VERSION "BASE;119 -- 04.07.2025 -- R3233 -- FDMgenDBC1.0"

NS_ :

BS_:

BU_: CM4

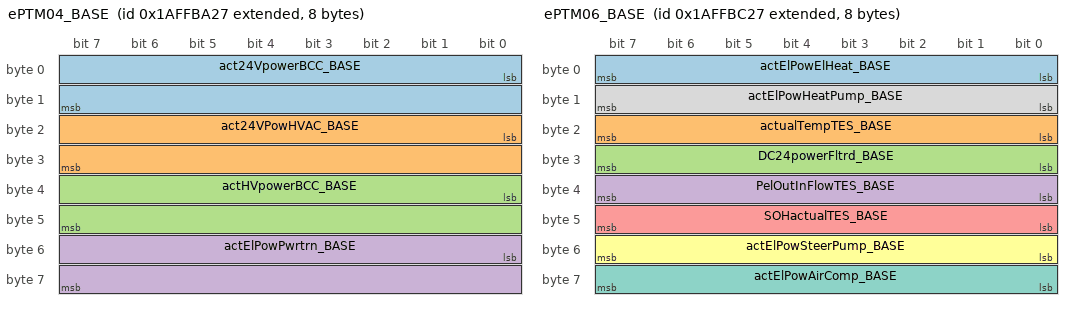
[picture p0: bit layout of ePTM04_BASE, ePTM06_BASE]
BO_ 2600450599 ePTM04_BASE: 8 Vector__XXX
 SG_ act24VpowerBCC_BASE : 0|16@1+ (0.0025,0) [0|13] "kW" CM4
 SG_ act24VPowHVAC_BASE : 16|16@1+ (1,0) [0|60000] "W" CM4
 SG_ actHVpowerBCC_BASE : 32|16@1+ (0.0125,0) [0|100] "kW" CM4
 SG_ actElPowPwrtrn_BASE : 48|16@1+ (1,-600) [-600|600] "kW" CM4

BO_ 2600451111 ePTM06_BASE: 8 Vector__XXX
 SG_ actElPowElHeat_BASE : 0|8@1+ (500,0) [0|125000] "W" CM4
 SG_ actualTempTES_BASE : 16|8@1+ (0.5,-40) [-40|85] "°C" CM4
 SG_ DC24powerFltrd_BASE : 24|8@1+ (0.125,0) [0|30] "kW" CM4
 SG_ PelOutInFlowTES_BASE : 32|8@1+ (5,-625) [-625|625] "kW" CM4
 SG_ SOHactualTES_BASE : 40|8@1+ (0.4,0) [0|100] "%" CM4
 SG_ actElPowSteerPump_BASE : 48|8@1+ (0.05,0) [0|8.125] "kW" CM4
 SG_ actElPowAirComp_BASE : 56|8@1+ (0.05,0) [0|10.8] "kW" CM4
 SG_ actElPowHeatPump_BASE : 8|8@1+ (500,0) [0|125000] "W" CM4

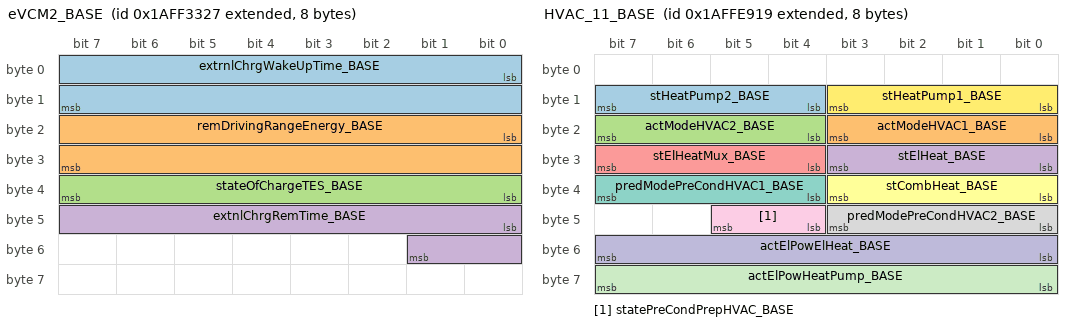
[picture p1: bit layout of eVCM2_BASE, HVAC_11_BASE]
BO_ 2600416039 eVCM2_BASE: 8 Vector__XXX
 SG_ extrnlChrgWakeUpTime_BASE : 0|16@1+ (60,0) [0|64255] "s" CM4
 SG_ remDrivingRangeEnergy_BASE : 16|16@1+ (0.5,0) [0|32127.5] "km" CM4
 SG_ stateOfChargeTES_BASE : 32|8@1+ (0.4,0) [0|100] "%" CM4
 SG_ extnlChrgRemTime_BASE : 40|10@1+ (5,0) [0|4320] "min" CM4

BO_ 2600462617 HVAC_11_BASE: 8 Vector__XXX
 SG_ stHeatPump2_BASE : 12|4@1+ (1,0) [0|0] "-" CM4
 SG_ actModeHVAC1_BASE : 16|4@1+ (1,0) [0|0] "-" CM4
 SG_ actModeHVAC2_BASE : 20|4@1+ (1,0) [0|0] "-" CM4
 SG_ stElHeat_BASE : 24|4@1+ (1,0) [0|0] "-" CM4
 SG_ stElHeatMux_BASE : 28|4@1+ (1,0) [0|0] "-" CM4
 SG_ stCombHeat_BASE : 32|4@1+ (1,0) [0|0] "-" CM4
 SG_ predModePreCondHVAC1_BASE : 36|4@1+ (1,0) [0|0] "-" CM4
 SG_ predModePreCondHVAC2_BASE : 40|4@1+ (1,0) [0|0] "-" CM4
 SG_ statePreCondPrepHVAC_BASE : 44|2@1+ (1,0) [0|0] "-" CM4
 SG_ actElPowElHeat_BASE : 48|8@1+ (500,0) [0|125000] "W" CM4
 SG_ actElPowHeatPump_BASE : 56|8@1+ (500,0) [0|125000] "W" CM4
 SG_ stHeatPump1_BASE : 8|4@1+ (1,0) [0|0] "-" CM4

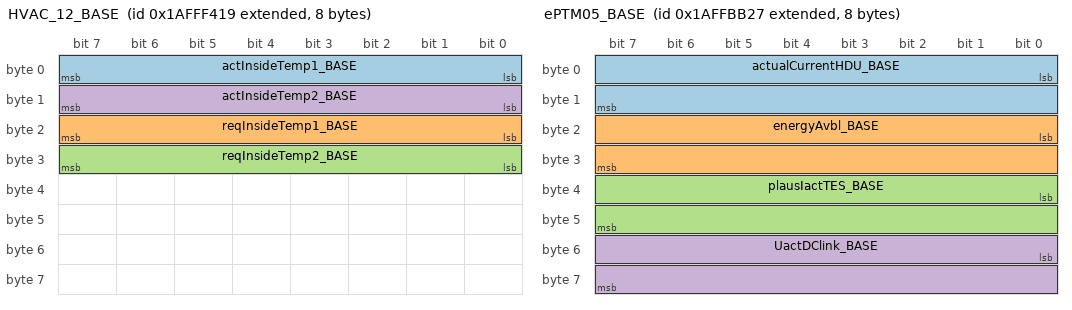
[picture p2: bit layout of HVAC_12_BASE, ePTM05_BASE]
BO_ 2600465433 HVAC_12_BASE: 8 Vector__XXX
 SG_ actInsideTemp1_BASE : 0|8@1+ (0.33,-30) [-30|52.5] "°C" CM4
 SG_ reqInsideTemp1_BASE : 16|8@1+ (0.33,-30) [-30|52.5] "°C" CM4
 SG_ reqInsideTemp2_BASE : 24|8@1+ (0.33,-30) [-30|52.5] "°C" CM4
 SG_ actInsideTemp2_BASE : 8|8@1+ (0.33,-30) [-30|52.5] "°C" CM4

BO_ 2600450855 ePTM05_BASE: 8 Vector__XXX
 SG_ actualCurrentHDU_BASE : 0|16@1+ (0.25,-8031.75) [-8031.75|8032] "A" CM4
 SG_ energyAvbl_BASE : 16|16@1+ (0.01,0) [0|600] "kWh" CM4
 SG_ plausIactTES_BASE : 32|16@1+ (0.25,-8031.875) [-8031.875|8031.875] "A" CM4
 SG_ UactDClink_BASE : 48|16@1+ (0.05,0) [0|3212.75] "V" CM4

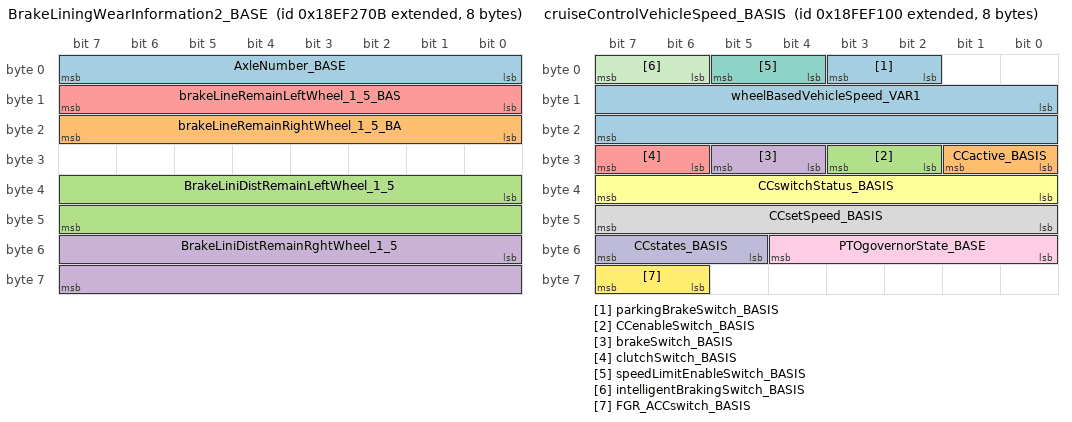
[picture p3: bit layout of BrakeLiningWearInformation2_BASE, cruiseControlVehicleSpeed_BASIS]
BO_ 2565809931 BrakeLiningWearInformation2_BASE: 8 Vector__XXX
 SG_ AxleNumber_BASE : 0|8@1+ (1,0) [0|250] "-" CM4
 SG_ brakeLineRemainRightWheel_1_5_BA : 16|8@1+ (0.4,0) [0|100] "%" CM4
 SG_ BrakeLiniDistRemainLeftWheel_1_5 : 32|16@1+ (100,0) [0|6553500] "km" CM4
 SG_ BrakeLiniDistRemainRghtWheel_1_5 : 48|16@1+ (100,0) [0|6553500] "km" CM4
 SG_ brakeLineRemainLeftWheel_1_5_BAS : 8|8@1+ (0.4,0) [0|100] "%" CM4

BO_ 2566844672 cruiseControlVehicleSpeed_BASIS: 8 Vector__XXX
 SG_ parkingBrakeSwitch_BASIS : 2|2@1+ (1,0) [0|0] "-" CM4
 SG_ CCactive_BASIS : 24|2@1+ (1,0) [0|0] "-" CM4
 SG_ CCenableSwitch_BASIS : 26|2@1+ (1,0) [0|0] "-" CM4
 SG_ brakeSwitch_BASIS : 28|2@1+ (1,0) [0|0] "-" CM4
 SG_ clutchSwitch_BASIS : 30|2@1+ (1,0) [0|0] "-" CM4
 SG_ CCswitchStatus_BASIS : 32|8@1+ (1,0) [0|0] "-" CM4
 SG_ speedLimitEnableSwitch_BASIS : 4|2@1+ (1,0) [0|0] "-" CM4
 SG_ CCsetSpeed_BASIS : 40|8@1+ (1,0) [0|250] "km/h" CM4
 SG_ PTOgovernorState_BASE : 48|5@1+ (1,0) [0|0] "-" CM4
 SG_ CCstates_BASIS : 53|3@1+ (1,0) [0|0] "-" CM4
 SG_ intelligentBrakingSwitch_BASIS : 6|2@1+ (1,0) [0|0] "-" CM4
 SG_ FGR_ACCswitch_BASIS : 62|2@1+ (1,0) [0|0] "-" CM4
 SG_ wheelBasedVehicleSpeed_VAR1 : 8|16@1+ (0.00390625,0) [0|250.996] "km/h" CM4

BO_ 2365479471 ASC1_BASIS: 8 Vector__XXX
 SG_ nominalLevelFrontAxle_BASIS : 0|4@1+ (1,0) [0|0] "-" CM4
 SG_ belowNominalLevelRearAxle_BASIS : 10|2@1+ (1,0) [0|0] "-" CM4
 SG_ aboveNominalLevelFrontAxle_BASIS : 12|2@1+ (1,0) [0|0] "-" CM4
 SG_ aboveNominalLevelRearAxle_BASIS : 14|2@1+ (1,0) [0|0] "-" CM4
 SG_ loweringControlModeFrontAxle_BAS : 16|2@1+ (1,0) [0|0] "-" CM4
 SG_ loweringControlModeRearAxle_BASI : 18|2@1+ (1,0) [0|0] "-" CM4
 SG_ liftingControlModeFrontAxle_BASI : 20|2@1+ (1,0) [0|0] "-" CM4
 SG_ liftingControlModeRearAxle_BASIS : 22|2@1+ (1,0) [0|0] "-" CM4
 SG_ kneelingInformation_BASIS : 24|4@1+ (1,0) [0|0] "-" CM4
 SG_ levelControlMode_BASIS : 28|4@1+ (1,0) [0|0] "-" CM4
 SG_ securityDevice_BASIS : 32|2@1+ (1,0) [0|0] "-" CM4
 SG_ vehicleMotionInhibit_BASIS : 34|2@1+ (1,0) [0|0] "-" CM4
 SG_ doorRelease_BASIS : 36|2@1+ (1,0) [0|0] "-" CM4
 SG_ liftAxle1position_BASIS : 38|2@1+ (1,0) [0|0] "-" CM4
 SG_ nominalLevelRearAxle_BASIS : 4|4@1+ (1,0) [0|0] "-" CM4
 SG_ frontAxleBumperRange_BASIS : 40|2@1+ (1,0) [0|0] "-" CM4
 SG_ rearAxleBumperRange_BASIS : 42|2@1+ (1,0) [0|0] "-" CM4
 SG_ liftAxle2position_BASIS : 46|2@1+ (1,0) [0|0] "-" CM4
 SG_ suspensionRemoteControl1_BASIS : 48|2@1+ (1,0) [0|0] "-" CM4
 SG_ suspensionRemoteControl2_BASIS : 50|2@1+ (1,0) [0|0] "-" CM4
 SG_ allowLvlCtrlDuringBrakingStatus_ : 52|2@1+ (1,0) [0|0] "-" CM4
 SG_ speedDependantLevelControlStatus : 54|2@1+ (1,0) [0|0] "-" CM4
 SG_ suspensionControlRefusalInfo_BAS : 56|4@1+ (1,0) [0|0] "-" CM4
 SG_ belowNominalLevelFrontAxle_BASIS : 8|2@1+ (1,0) [0|0] "-" CM4

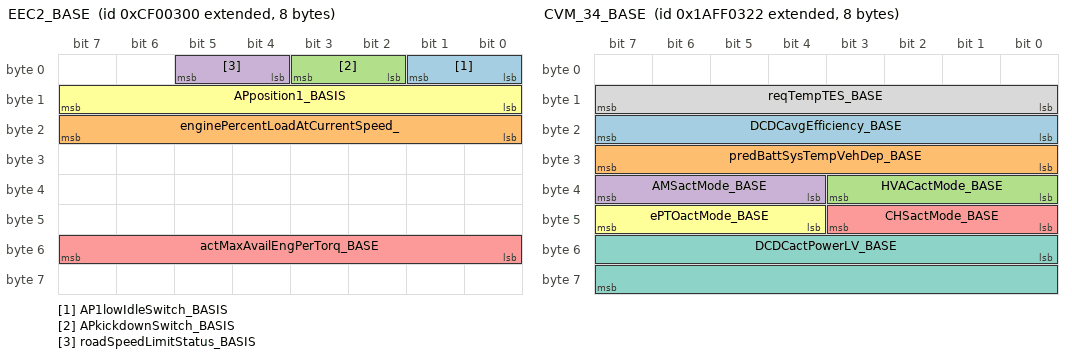
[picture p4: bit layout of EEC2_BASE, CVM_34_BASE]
BO_ 2364539648 EEC2_BASE: 8 Vector__XXX
 SG_ AP1lowIdleSwitch_BASIS : 0|2@1+ (1,0) [0|0] "-" CM4
 SG_ enginePercentLoadAtCurrentSpeed_ : 16|8@1+ (1,0) [0|250] "%" CM4
 SG_ APkickdownSwitch_BASIS : 2|2@1+ (1,0) [0|0] "-" CM4
 SG_ roadSpeedLimitStatus_BASIS : 4|2@1+ (1,0) [0|0] "-" CM4
 SG_ actMaxAvailEngPerTorq_BASE : 48|8@1+ (0.4,0) [0|100] "%" CM4
 SG_ APposition1_BASIS : 8|8@1+ (0.4,0) [0|100] "%" CM4

BO_ 2600403746 CVM_34_BASE: 8 Vector__XXX
 SG_ DCDCavgEfficiency_BASE : 16|8@1+ (0.005,0) [0|1] "-" CM4
 SG_ predBattSysTempVehDep_BASE : 24|8@1+ (0.5,-40) [-40|85] "°C" CM4
 SG_ HVACactMode_BASE : 32|4@1+ (1,0) [0|0] "-" CM4
 SG_ AMSactMode_BASE : 36|4@1+ (1,0) [0|0] "-" CM4
 SG_ CHSactMode_BASE : 40|4@1+ (1,0) [0|0] "-" CM4
 SG_ ePTOactMode_BASE : 44|4@1+ (1,0) [0|0] "-" CM4
 SG_ DCDCactPowerLV_BASE : 48|16@1+ (0.025,-800) [-800|800] "kW" CM4
 SG_ reqTempTES_BASE : 8|8@1+ (0.5,-40) [-40|85] "°C" CM4

BO_ 2600403748 CVM_36_BASE: 8 Vector__XXX
 SG_ AMSenergyNorm_BASE : 0|32@1+ (0.0025,-1000000) [-1000000|1000000] "kWs" CM4
 SG_ AMS1sMeanPowerLV_BASE : 32|16@1+ (0.025,-800) [-800|800] "kW" CM4
 SG_ AMS1sMeanPowerHV_BASE : 48|16@1+ (0.025,-800) [-800|800] "kW" CM4

BO_ 2600403749 CVM_37_BASE: 8 Vector__XXX
 SG_ CHSenergyNorm_BASE : 0|32@1+ (0.0025,-1000000) [-1000000|1000000] "kWs" CM4
 SG_ CHS1sMeanPowerLV_BASE : 32|16@1+ (0.025,-800) [-800|800] "kW" CM4
 SG_ CHS1sMeanPowerHV_BASE : 48|16@1+ (0.025,-800) [-800|800] "kW" CM4

BO_ 2600403750 CVM_38_BASE: 8 Vector__XXX
 SG_ ePTOenergyNorm_BASE : 0|32@1+ (0.0025,-1000000) [-1000000|1000000] "kWs" CM4
 SG_ ePTO1sMeanPowerLV_BASE : 32|16@1+ (0.025,-800) [-800|800] "kW" CM4
 SG_ ePTO1sMeanPowerHV_BASE : 48|16@1+ (0.025,-800) [-800|800] "kW" CM4

BO_ 2600403751 CVM_39_BASE: 8 Vector__XXX
 SG_ HVACenergyNorm_BASE : 0|32@1+ (0.0025,-1000000) [-1000000|1000000] "kWs" CM4
 SG_ HVAC1sMeanPowerLV_BASE : 32|16@1+ (0.025,-800) [-800|800] "kW" CM4
 SG_ HVAC1sMeanPowerHV_BASE : 48|16@1+ (0.025,-800) [-800|800] "kW" CM4

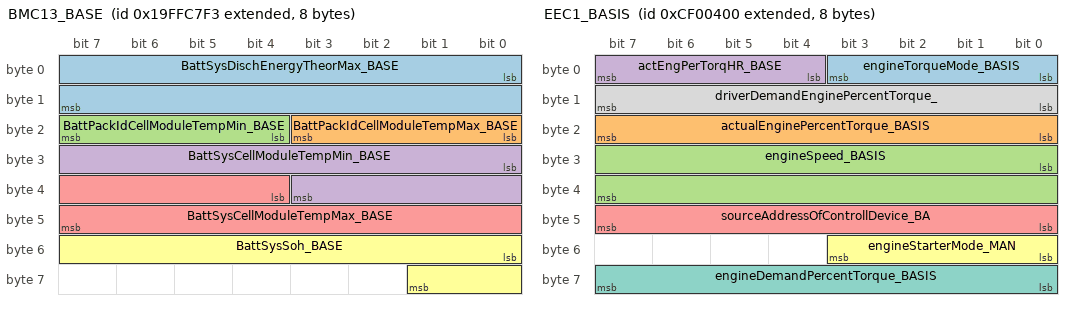
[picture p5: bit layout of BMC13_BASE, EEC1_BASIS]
BO_ 2583676915 BMC13_BASE: 8 Vector__XXX
 SG_ BattSysDischEnergyTheorMax_BASE : 0|16@1+ (0.05,0) [0|1000] "kWh" CM4
 SG_ BattPackIdCellModuleTempMax_BASE : 16|4@1+ (1,1) [1|16] "-" CM4
 SG_ BattPackIdCellModuleTempMin_BASE : 20|4@1+ (1,1) [1|16] "-" CM4
 SG_ BattSysCellModuleTempMin_BASE : 24|12@1+ (0.1,-50) [-50|90] "°C" CM4
 SG_ BattSysCellModuleTempMax_BASE : 36|12@1+ (0.1,-50) [-50|90] "°C" CM4
 SG_ BattSysSoh_BASE : 48|10@1+ (0.1,0) [0|100] "%" CM4

BO_ 2566535975 EPTO1I_BASE: 8 Vector__XXX
 SG_ ePTO1CurrentLimit_BASE : 0|16@1+ (0.05,0) [0|3212.75] "-" CM4
 SG_ ePTO1Current_BASE : 16|16@1+ (0.05,0) [0|3212.75] "A" CM4
 SG_ ePTO1Voltage_BASE : 32|16@1+ (0.05,0) [0|3212.75] "-" CM4

BO_ 2566889761 auxStatZBR1_BASIS: 8 Vector__XXX
 SG_ tuerkontaktLinks_BASIS : 0|2@1+ (1,0) [0|0] "-" CM4
 SG_ fahrerhausVerriegelung_BASIS : 10|2@1+ (1,0) [0|0] "-" CM4
 SG_ haengerABSerkennung_BASIS : 12|2@1+ (1,0) [0|0] "-" CM4
 SG_ flammstartAktiv_BASIS : 14|2@1+ (1,0) [0|0] "-" CM4
 SG_ fernlichtEinRueckmeldung_BASIS : 18|2@1+ (1,0) [0|0] "-" CM4
 SG_ tuerkontaktRechts_BASIS : 2|2@1+ (1,0) [0|0] "-" CM4
 SG_ schalterFahrniveau1oder2senken_B : 24|2@1+ (1,0) [0|0] "-" CM4
 SG_ hybTripReset_BASE : 36|2@1+ (1,0) [0|0] "-" CM4
 SG_ instrFunktionsfaehig_BASIS : 38|2@1+ (1,0) [0|0] "-" CM4
 SG_ kraftstoffuellstandZuNiedrig_BAS : 4|2@1+ (1,0) [0|0] "-" CM4
 SG_ schalterBlinkerRechtsRueckm_BASI : 44|2@1+ (1,0) [0|0] "-" CM4
 SG_ schalterBlinkerLinksRueckm_BASIS : 46|2@1+ (1,0) [0|0] "-" CM4
 SG_ lichttestAktivRueckmeldung_BASIS : 48|2@1+ (1,0) [0|0] "-" CM4
 SG_ kontrVersorgAnhaengerABS_BASIS : 50|2@1+ (1,0) [0|0] "-" CM4
 SG_ highBeamOutpState_BASE : 52|2@1+ (1,0) [0|0] "-" CM4
 SG_ beleuchtungHaenger1erkannt_BASIS : 54|2@1+ (1,0) [0|0] "-" CM4
 SG_ fahrlichtEinRueckmeldung_BASIS : 56|2@1+ (1,0) [0|0] "-" CM4
 SG_ rueckwaertsgangEingelegt_BASIS : 6|2@1+ (1,0) [0|0] "-" CM4
 SG_ infoNotaus_BASIS : 8|2@1+ (1,0) [0|0] "-" CM4

BO_ 2565865739 EBC1_BASIS: 8 Vector__XXX
 SG_ ASRengineControlActPass_BASIS : 0|2@1+ (1,0) [0|0] "-" CM4
 SG_ ABSoffroadSwitch_BASIS : 16|2@1+ (1,0) [0|0] "-" CM4
 SG_ ASRoffroadSwitch_BASIS : 18|2@1+ (1,0) [0|0] "-" CM4
 SG_ ASRbrakeControlActPass_BASIS : 2|2@1+ (1,0) [0|0] "-" CM4
 SG_ ASRhillHolderSwitch_BASIS : 20|2@1+ (1,0) [0|0] "-" CM4
 SG_ tractionControlOverrideSwitch_BA : 22|2@1+ (1,0) [0|0] "-" CM4
 SG_ acceleratorInterlockSwitch_BASIS : 24|2@1+ (1,0) [0|0] "-" CM4
 SG_ engineDerateSwitch_BASIS : 26|2@1+ (1,0) [0|0] "-" CM4
 SG_ engineAuxiliaryShutdownSwitch_BA : 28|2@1+ (1,0) [0|0] "-" CM4
 SG_ remoteAcceleratorEnableSwitch_BA : 30|2@1+ (1,0) [0|0] "-" CM4
 SG_ engineRetarderSelection_BASIS : 32|8@1+ (0.4,0) [0|100] "%" CM4
 SG_ ABSactive_BASIS : 4|2@1+ (1,0) [0|0] "-" CM4
 SG_ ABSfullyOperational_BASIS : 40|2@1+ (1,0) [0|0] "-" CM4
 SG_ EBSredWarningSignal_BASIS : 42|2@1+ (1,0) [0|0] "-" CM4
 SG_ ABS_EBSamberWarningSignal_BASIS : 44|2@1+ (1,0) [0|0] "-" CM4
 SG_ ATC_ASRinformationSignal_BASIS : 46|2@1+ (1,0) [0|0] "-" CM4
 SG_ sourceAddressOfControllDevice_EB : 48|8@1+ (1,0) [0|253] "-" CM4
 SG_ haltBrakeSwitch_BASIS : 58|2@1+ (1,0) [0|0] "-" CM4
 SG_ EBSbrakeSwitch_BASIS : 6|2@1+ (1,0) [0|0] "-" CM4
 SG_ trailerABSstatus_BASIS : 60|2@1+ (1,0) [0|0] "-" CM4
 SG_ tractMountTrailerABSwarningSig_B : 62|2@1+ (1,0) [0|0] "-" CM4
 SG_ BPposition_BASIS : 8|8@1+ (0.4,0) [0|100] "%" CM4

BO_ 2364539904 EEC1_BASIS: 8 Vector__XXX
 SG_ engineTorqueMode_BASIS : 0|4@1+ (1,0) [0|0] "-" CM4
 SG_ actualEnginePercentTorque_BASIS : 16|8@1+ (1,-125) [-125|125] "%" CM4
 SG_ engineSpeed_BASIS : 24|16@1+ (0.125,0) [0|8031.875] "rpm" CM4
 SG_ actEngPerTorqHR_BASE : 4|4@1+ (0.125,0) [0|1.875] "%" CM4
 SG_ sourceAddressOfControllDevice_BA : 40|8@1+ (1,0) [0|255] "-" CM4
 SG_ engineStarterMode_MAN : 48|4@1+ (1,0) [0|0] "-" CM4
 SG_ engineDemandPercentTorque_BASIS : 56|8@1+ (1,-125) [-125|125] "%" CM4
 SG_ driverDemandEnginePercentTorque_ : 8|8@1+ (1,-125) [-125|125] "%" CM4

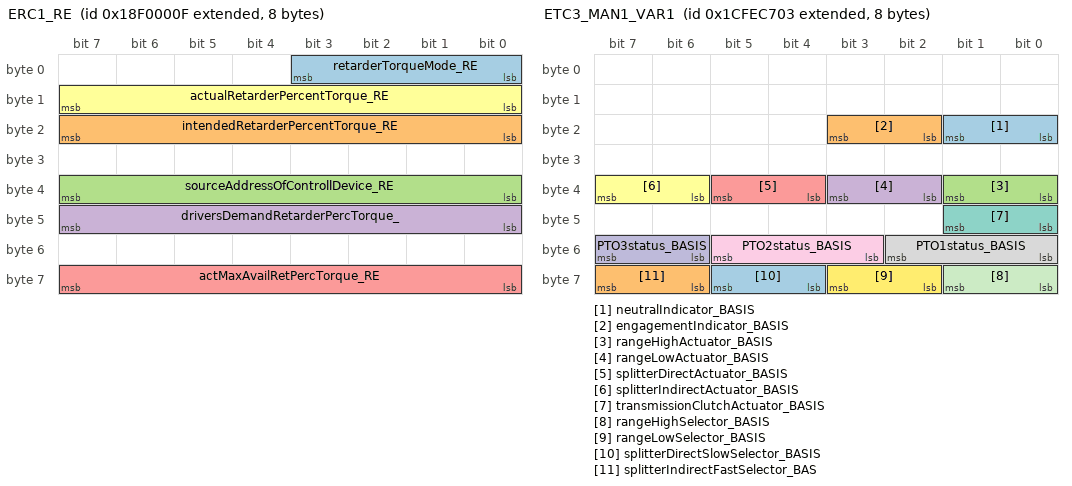
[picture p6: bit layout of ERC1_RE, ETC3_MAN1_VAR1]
BO_ 2565865487 ERC1_RE: 8 Vector__XXX
 SG_ retarderTorqueMode_RE : 0|4@1+ (1,0) [0|0] "-" CM4
 SG_ intendedRetarderPercentTorque_RE : 16|8@1+ (1,-125) [-125|125] "%" CM4
 SG_ sourceAddressOfControllDevice_RE : 32|8@1+ (1,0) [0|255] "-" CM4
 SG_ driversDemandRetarderPercTorque_ : 40|8@1+ (1,-125) [-125|125] "%" CM4
 SG_ actMaxAvailRetPercTorque_RE : 56|8@1+ (1,-125) [-125|125] "%" CM4
 SG_ actualRetarderPercentTorque_RE : 8|8@1+ (1,-125) [-125|125] "%" CM4

BO_ 2633942787 ETC3_MAN1_VAR1: 8 Vector__XXX
 SG_ neutralIndicator_BASIS : 16|2@1+ (1,0) [0|0] "-" CM4
 SG_ engagementIndicator_BASIS : 18|2@1+ (1,0) [0|0] "-" CM4
 SG_ rangeHighActuator_BASIS : 32|2@1+ (1,0) [0|0] "-" CM4
 SG_ rangeLowActuator_BASIS : 34|2@1+ (1,0) [0|0] "-" CM4
 SG_ splitterDirectActuator_BASIS : 36|2@1+ (1,0) [0|0] "-" CM4
 SG_ splitterIndirectActuator_BASIS : 38|2@1+ (1,0) [0|0] "-" CM4
 SG_ transmissionClutchActuator_BASIS : 40|2@1+ (1,0) [0|0] "-" CM4
 SG_ PTO1status_BASIS : 48|3@1+ (1,0) [0|0] "-" CM4
 SG_ PTO2status_BASIS : 51|3@1+ (1,0) [0|0] "-" CM4
 SG_ PTO3status_BASIS : 54|2@1+ (1,0) [0|0] "-" CM4
 SG_ rangeHighSelector_BASIS : 56|2@1+ (1,0) [0|0] "-" CM4
 SG_ rangeLowSelector_BASIS : 58|2@1+ (1,0) [0|0] "-" CM4
 SG_ splitterDirectSlowSelector_BASIS : 60|2@1+ (1,0) [0|0] "-" CM4
 SG_ splitterIndirectFastSelector_BAS : 62|2@1+ (1,0) [0|0] "-" CM4

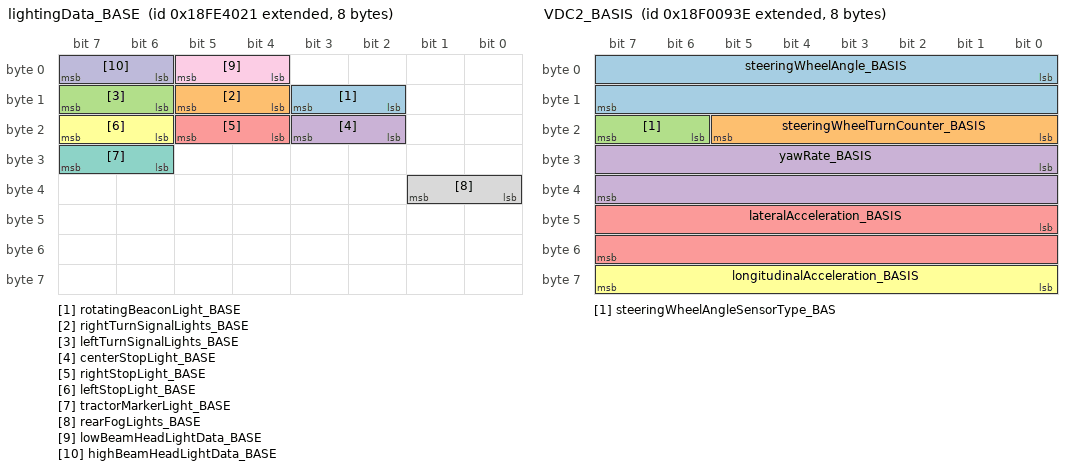
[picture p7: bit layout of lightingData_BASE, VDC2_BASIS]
BO_ 2566799393 lightingData_BASE: 8 Vector__XXX
 SG_ rotatingBeaconLight_BASE : 10|2@1+ (1,0) [0|0] "-" CM4
 SG_ rightTurnSignalLights_BASE : 12|2@1+ (1,0) [0|0] "-" CM4
 SG_ leftTurnSignalLights_BASE : 14|2@1+ (1,0) [0|0] "-" CM4
 SG_ centerStopLight_BASE : 18|2@1+ (1,0) [0|0] "-" CM4
 SG_ rightStopLight_BASE : 20|2@1+ (1,0) [0|0] "-" CM4
 SG_ leftStopLight_BASE : 22|2@1+ (1,0) [0|0] "-" CM4
 SG_ tractorMarkerLight_BASE : 30|2@1+ (1,0) [0|0] "-" CM4
 SG_ rearFogLights_BASE : 32|2@1+ (1,0) [0|0] "-" CM4
 SG_ lowBeamHeadLightData_BASE : 4|2@1+ (1,0) [0|0] "-" CM4
 SG_ highBeamHeadLightData_BASE : 6|2@1+ (1,0) [0|0] "-" CM4

BO_ 2565867838 VDC2_BASIS: 8 Vector__XXX
 SG_ steeringWheelAngle_BASIS : 0|16@1+ (0.0009765625,-31.374) [-31.374|31.3750234375000012221] "rad" CM4
 SG_ steeringWheelTurnCounter_BASIS : 16|6@1+ (1,-32) [-32|29] "turn" CM4
 SG_ steeringWheelAngleSensorType_BAS : 22|2@1+ (1,0) [0|0] "-" CM4
 SG_ yawRate_BASIS : 24|16@1+ (0.0001220703125,-3.92) [-3.92|3.9236279296875000711] "rad/s" CM4
 SG_ lateralAcceleration_BASIS : 40|16@1+ (0.00048828125,-15.687) [-15.687|15.687] "m/s²" CM4
 SG_ longitudinalAcceleration_BASIS : 56|8@1+ (0.1,-12.5) [-12.5|12.5] "m/s²" CM4

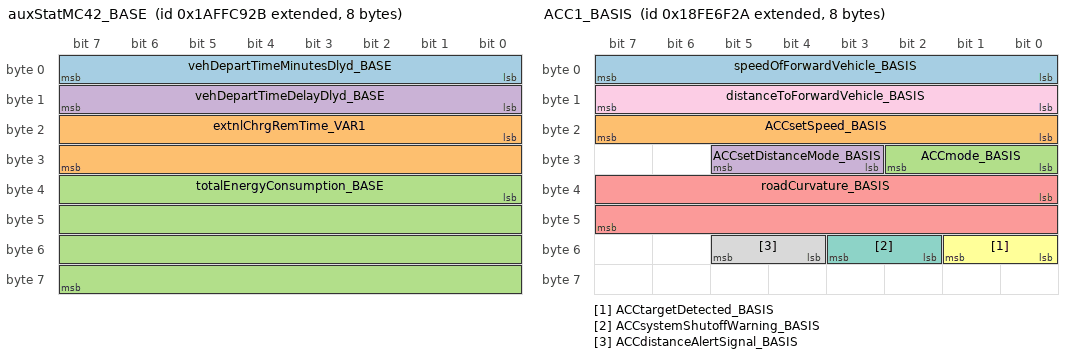
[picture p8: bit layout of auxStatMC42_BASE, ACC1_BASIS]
BO_ 2600454443 auxStatMC42_BASE: 8 Vector__XXX
 SG_ vehDepartTimeMinutesDlyd_BASE : 0|8@1+ (1,0) [0|250] "min" CM4
 SG_ extnlChrgRemTime_VAR1 : 16|16@1+ (5,0) [0|4320] "min" CM4
 SG_ totalEnergyConsumption_BASE : 32|32@1+ (1,0) [0|4211081215] "kWh" CM4
 SG_ vehDepartTimeDelayDlyd_BASE : 8|8@1+ (5,0) [0|1250] "min" CM4

BO_ 2566811434 ACC1_BASIS: 8 Vector__XXX
 SG_ speedOfForwardVehicle_BASIS : 0|8@1+ (1,0) [0|250] "km/h" CM4
 SG_ ACCsetSpeed_BASIS : 16|8@1+ (1,0) [0|250] "km/h" CM4
 SG_ ACCmode_BASIS : 24|3@1+ (1,0) [0|0] "-" CM4
 SG_ ACCsetDistanceMode_BASIS : 27|3@1+ (1,0) [0|0] "-" CM4
 SG_ roadCurvature_BASIS : 32|16@1+ (0.007813,-250) [-250|251.992] "1/km" CM4
 SG_ ACCtargetDetected_BASIS : 48|2@1+ (1,0) [0|0] "-" CM4
 SG_ ACCsystemShutoffWarning_BASIS : 50|2@1+ (1,0) [0|0] "-" CM4
 SG_ ACCdistanceAlertSignal_BASIS : 52|2@1+ (1,0) [0|0] "-" CM4
 SG_ distanceToForwardVehicle_BASIS : 8|8@1+ (1,0) [0|250] "m" CM4

BO_ 2566889767 auxStatMC1_BASE: 8 Vector__XXX
 SG_ AEBSactivationState_BASE : 0|2@1+ (1,0) [0|0] "-" CM4
 SG_ DPFlowLevelWarning_BASE : 10|2@1+ (1,0) [0|0] "-" CM4
 SG_ DPFmiddleLevelWarning_BASE : 12|2@1+ (1,0) [0|0] "-" CM4
 SG_ DPFactiveRegenerationManual_BASE : 14|2@1+ (1,0) [0|0] "-" CM4
 SG_ engDerateDueToUreaLevel_BASE : 16|2@1+ (1,0) [0|0] "-" CM4
 SG_ engDerateDueToUreaQuality_BASE : 18|2@1+ (1,0) [0|0] "-" CM4
 SG_ wrnDfctLDW_BASE : 2|2@1+ (1,0) [0|0] "-" CM4
 SG_ engDerateDueToUreaSystem_BASE : 20|2@1+ (1,0) [0|0] "-" CM4
 SG_ engDerateDueToATSystem_BASE : 22|2@1+ (1,0) [0|0] "-" CM4
 SG_ creepModeDueToUreaLevel_BASE : 24|2@1+ (1,0) [0|0] "-" CM4
 SG_ creepModeDueToUreaQuality_BASE : 26|2@1+ (1,0) [0|0] "-" CM4
 SG_ creepModeDueToUreaSystem_BASE : 28|2@1+ (1,0) [0|0] "-" CM4
 SG_ creepModeDueToATSystem_BASE : 30|2@1+ (1,0) [0|0] "-" CM4
 SG_ emgcyBrkState_BASE : 32|2@1+ (1,0) [0|0] "-" CM4
 SG_ antiJackknifeBrake_BASE : 34|2@1+ (1,0) [0|0] "-" CM4
 SG_ vehSpdLimWrn_BASE : 38|2@1+ (1,0) [0|0] "-" CM4
 SG_ wrnDfctEBA_BASE : 4|2@1+ (1,0) [0|0] "-" CM4
 SG_ PCCAenabled_BASE : 40|2@1+ (1,0) [0|0] "-" CM4
 SG_ PCCAecoDisp_BASE : 48|2@1+ (1,0) [0|0] "-" CM4
 SG_ dispMotionDataCnflct_BASE : 50|2@1+ (1,0) [0|0] "-" CM4
 SG_ LDWselected_BASE : 52|2@1+ (1,0) [0|0] "-" CM4
 SG_ dispMotionDataLimit_BASE : 54|2@1+ (1,0) [0|0] "-" CM4
 SG_ PCCAactiveDisp_BASE : 56|4@1+ (1,0) [0|0] "-" CM4
 SG_ brakeLightTailDfct_BASE : 6|2@1+ (1,0) [0|0] "-" CM4
 SG_ drvSysReadyToMove_BASE : 60|2@1+ (1,0) [0|0] "-" CM4
 SG_ exhaustHighTempLamp_BASE : 8|2@1+ (1,0) [0|0] "-" CM4

BO_ 2566913831 PCCA_VAR2: 8 Vector__XXX
 SG_ modePCCA_BASE : 0|4@1+ (1,0) [0|0] "-" CM4
 SG_ spdIncPCCA_BASE : 16|8@1+ (1,0) [0|250] "km/h" CM4
 SG_ spdDecPCCA_BASE : 24|8@1+ (1,0) [0|250] "km/h" CM4

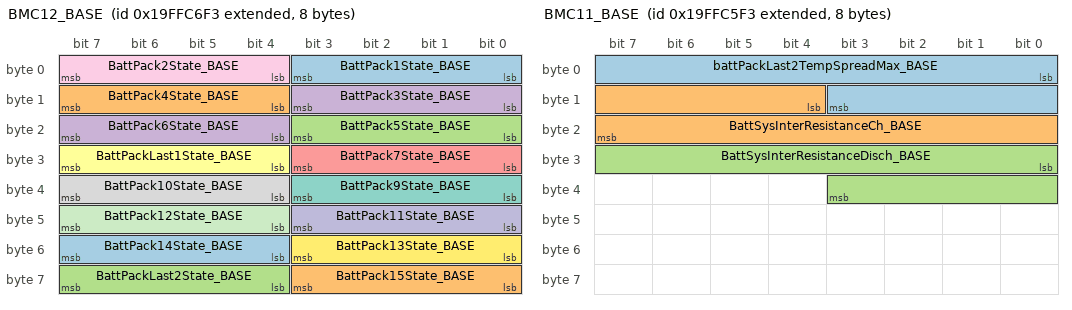
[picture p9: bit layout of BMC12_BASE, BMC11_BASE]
BO_ 2583676659 BMC12_BASE: 8 Vector__XXX
 SG_ BattPack1State_BASE : 0|4@1+ (1,0) [0|0] "-" CM4
 SG_ BattPack4State_BASE : 12|4@1+ (1,0) [0|0] "-" CM4
 SG_ BattPack5State_BASE : 16|4@1+ (1,0) [0|0] "-" CM4
 SG_ BattPack6State_BASE : 20|4@1+ (1,0) [0|0] "-" CM4
 SG_ BattPack7State_BASE : 24|4@1+ (1,0) [0|0] "-" CM4
 SG_ BattPackLast1State_BASE : 28|4@1+ (1,0) [0|0] "-" CM4
 SG_ BattPack9State_BASE : 32|4@1+ (1,0) [0|0] "-" CM4
 SG_ BattPack10State_BASE : 36|4@1+ (1,0) [0|0] "-" CM4
 SG_ BattPack2State_BASE : 4|4@1+ (1,0) [0|0] "-" CM4
 SG_ BattPack11State_BASE : 40|4@1+ (1,0) [0|0] "-" CM4
 SG_ BattPack12State_BASE : 44|4@1+ (1,0) [0|0] "-" CM4
 SG_ BattPack13State_BASE : 48|4@1+ (1,0) [0|0] "-" CM4
 SG_ BattPack14State_BASE : 52|4@1+ (1,0) [0|0] "-" CM4
 SG_ BattPack15State_BASE : 56|4@1+ (1,0) [0|0] "-" CM4
 SG_ BattPackLast2State_BASE : 60|4@1+ (1,0) [0|0] "-" CM4
 SG_ BattPack3State_BASE : 8|4@1+ (1,0) [0|0] "-" CM4

BO_ 2583676403 BMC11_BASE: 8 Vector__XXX
 SG_ battPackLast2TempSpreadMax_BASE : 0|12@1+ (0.1,0) [0|401.5] "°C" CM4
 SG_ BattSysInterResistanceCh_BASE : 12|12@1+ (0.001,0) [0|4.015] "Ohm" CM4
 SG_ BattSysInterResistanceDisch_BASE : 24|12@1+ (0.001,0) [0|4.015] "Ohm" CM4

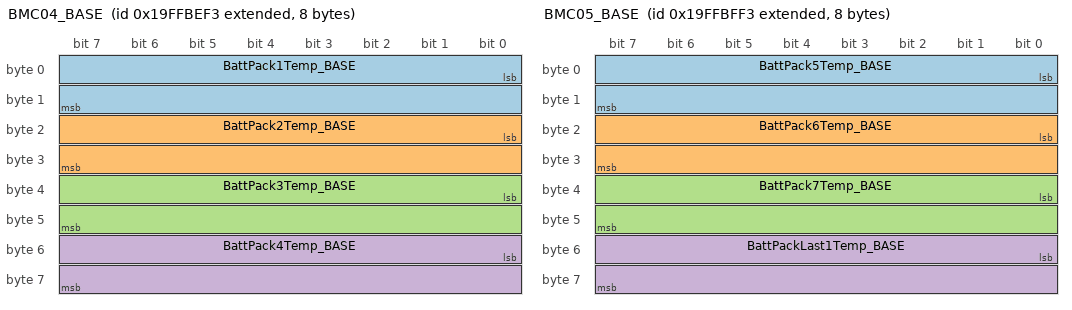
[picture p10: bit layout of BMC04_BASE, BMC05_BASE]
BO_ 2583674611 BMC04_BASE: 8 Vector__XXX
 SG_ BattPack1Temp_BASE : 0|16@1+ (0.01,-50) [-50|592.55] "°C" CM4
 SG_ BattPack2Temp_BASE : 16|16@1+ (0.01,-50) [-50|592.55] "°C" CM4
 SG_ BattPack3Temp_BASE : 32|16@1+ (0.01,-50) [-50|592.55] "°C" CM4
 SG_ BattPack4Temp_BASE : 48|16@1+ (0.01,-50) [-50|592.55] "°C" CM4

BO_ 2583674867 BMC05_BASE: 8 Vector__XXX
 SG_ BattPack5Temp_BASE : 0|16@1+ (0.01,-50) [-50|592.55] "°C" CM4
 SG_ BattPack6Temp_BASE : 16|16@1+ (0.01,-50) [-50|592.55] "°C" CM4
 SG_ BattPack7Temp_BASE : 32|16@1+ (0.01,-50) [-50|592.55] "°C" CM4
 SG_ BattPackLast1Temp_BASE : 48|16@1+ (0.01,-50) [-50|592.55] "°C" CM4

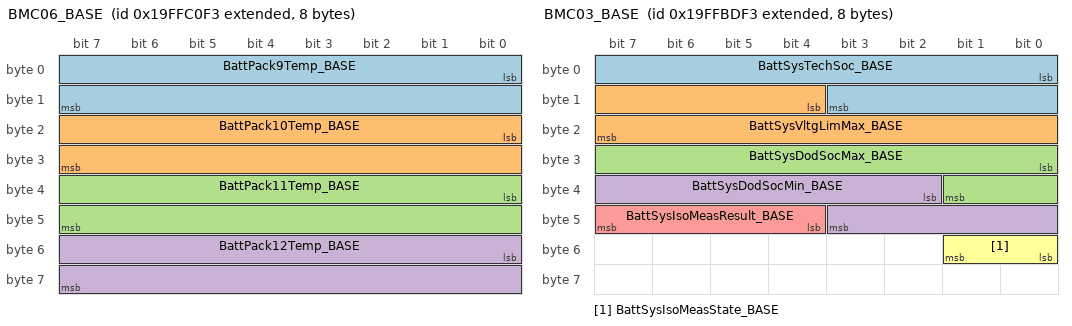
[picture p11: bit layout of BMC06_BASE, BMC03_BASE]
BO_ 2583675123 BMC06_BASE: 8 Vector__XXX
 SG_ BattPack9Temp_BASE : 0|16@1+ (0.01,-50) [-50|592.55] "°C" CM4
 SG_ BattPack10Temp_BASE : 16|16@1+ (0.01,-50) [-50|592.55] "°C" CM4
 SG_ BattPack11Temp_BASE : 32|16@1+ (0.01,-50) [-50|592.55] "°C" CM4
 SG_ BattPack12Temp_BASE : 48|16@1+ (0.01,-50) [-50|592.55] "°C" CM4

BO_ 2583675379 BMC07_BASE: 8 Vector__XXX
 SG_ BattPack13Temp_BASE : 0|16@1+ (0.01,-50) [-50|592.55] "°C" CM4
 SG_ BattPack14Temp_BASE : 16|16@1+ (0.01,-50) [-50|592.55] "°C" CM4
 SG_ BattPack15Temp_BASE : 32|16@1+ (0.01,-50) [-50|592.55] "°C" CM4
 SG_ BattPackLast2Temp_BASE : 48|16@1+ (0.01,-50) [-50|592.55] "°C" CM4

BO_ 2566801959 ETC7_VAR1: 8 Vector__XXX
 SG_ transmissionMode1indicator_BASIS : 22|2@1+ (1,0) [0|0] "-" CM4

BO_ 2583674355 BMC03_BASE: 8 Vector__XXX
 SG_ BattSysTechSoc_BASE : 0|12@1+ (0.025,0) [0|100.375] "%" CM4
 SG_ BattSysVltgLimMax_BASE : 12|12@1+ (0.5,0) [0|2007.5] "V" CM4
 SG_ BattSysDodSocMax_BASE : 24|10@1+ (0.1,0) [0|100] "%" CM4
 SG_ BattSysDodSocMin_BASE : 34|10@1+ (0.1,0) [0|100] "%" CM4
 SG_ BattSysIsoMeasResult_BASE : 44|4@1+ (1,0) [0|0] "-" CM4
 SG_ BattSysIsoMeasState_BASE : 48|2@1+ (1,0) [0|0] "-" CM4

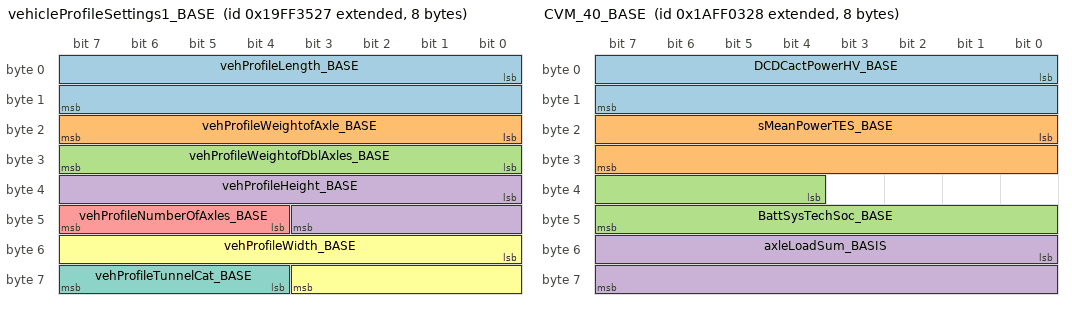
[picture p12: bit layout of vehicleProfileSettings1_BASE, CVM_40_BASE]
BO_ 2583639335 vehicleProfileSettings1_BASE: 8 Vector__XXX
 SG_ vehProfileLength_BASE : 0|16@1+ (0.01,0) [0|51.82] "m" CM4
 SG_ vehProfileWeightofAxle_BASE : 16|8@1+ (500,0) [0|99000] "kg" CM4
 SG_ vehProfileWeightofDblAxles_BASE : 24|8@1+ (500,0) [0|99000] "kg" CM4
 SG_ vehProfileHeight_BASE : 32|12@1+ (0.01,0) [0|6.1] "m" CM4
 SG_ vehProfileNumberOfAxles_BASE : 44|4@1+ (1,0) [0|11] "-" CM4
 SG_ vehProfileWidth_BASE : 48|12@1+ (0.01,0) [0|3.05] "m" CM4
 SG_ vehProfileTunnelCat_BASE : 60|4@1+ (1,0) [0|0] "-" CM4

BO_ 2600403752 CVM_40_BASE: 8 Vector__XXX
 SG_ DCDCactPowerHV_BASE : 0|16@1+ (0.025,-800) [-800|800] "kW" CM4
 SG_ sMeanPowerTES_BASE : 16|16@1+ (0.05,-1600) [-1600|1600] "kW" CM4
 SG_ BattSysTechSoc_BASE : 36|12@1+ (0.025,0) [0|100.375] "%" CM4
 SG_ axleLoadSum_BASIS : 48|16@1+ (2,0) [0|128510] "kg" CM4

BO_ 2600403753 CVM_41_BASE: 8 Vector__XXX
 SG_ BattSysChCurrLimDyn_BASE : 0|16@1+ (0.1,0) [0|6425.5] "A" CM4
 SG_ extrnlChrgImaxLim_BASE : 16|16@1+ (0.0625,0) [0|4015.9375] "A" CM4
 SG_ extrnlChrgTargetCurrHR_BASE : 32|16@1+ (0.0625,0) [0|4015.9375] "A" CM4
 SG_ extrnlChrgDCchrgngCurrent_BASE : 48|16@1+ (0.25,-8031.75) [-8031.75|8032] "A" CM4

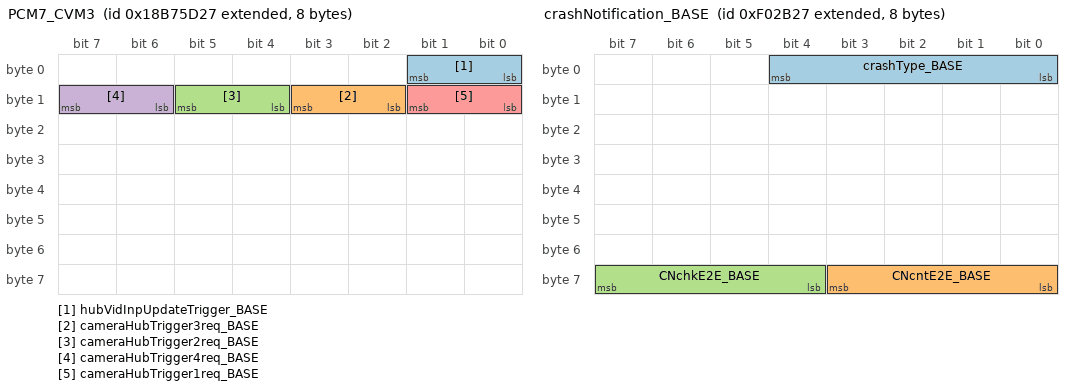
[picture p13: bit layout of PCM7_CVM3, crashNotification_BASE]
BO_ 2562153767 PCM7_CVM3: 8 Vector__XXX
 SG_ hubVidInpUpdateTrigger_BASE : 0|2@1+ (1,0) [0|0] "-" CM4
 SG_ cameraHubTrigger3req_BASE : 10|2@1+ (1,0) [0|0] "-" CM4
 SG_ cameraHubTrigger2req_BASE : 12|2@1+ (1,0) [0|0] "-" CM4
 SG_ cameraHubTrigger4req_BASE : 14|2@1+ (1,0) [0|0] "-" CM4
 SG_ cameraHubTrigger1req_BASE : 8|2@1+ (1,0) [0|0] "-" CM4

BO_ 2600407304 customerInterface15_BASE: 8 Vector__XXX
 SG_ placeholderCuIntf15_BASE : 0|8@1+ (1,0) [0|255] "-" CM4

BO_ 2600407309 customerInterface20_BASE: 8 Vector__XXX
 SG_ placeholderCuIntf20_BASE : 0|8@1+ (1,0) [0|255] "-" CM4

BO_ 2600407307 customerInterface18_BASE: 8 Vector__XXX
 SG_ placeholderCuIntf18_BASE : 0|8@1+ (1,0) [0|255] "-" CM4

BO_ 2600407308 customerInterface19_BASE: 8 Vector__XXX
 SG_ placeholderCuIntf19_BASE : 0|8@1+ (1,0) [0|255] "-" CM4

BO_ 2600407306 customerInterface17_BASE: 8 Vector__XXX
 SG_ placeholderCuIntf17_BASE : 0|8@1+ (1,0) [0|255] "-" CM4

BO_ 2600407305 customerInterface16_BASE: 8 Vector__XXX
 SG_ placeholderCuIntf16_BASE : 0|8@1+ (1,0) [0|255] "-" CM4

BO_ 2566575655 EVSE1S1_BASE: 8 Vector__XXX
 SG_ inletContactorState_BASE : 10|2@1+ (1,0) [0|0] "-" CM4
 SG_ EVSEconnectorLockState_BASE : 4|3@1+ (1,0) [0|0] "-" CM4

BO_ 2365561639 bodyBuilderInfo5_BASE: 8 Vector__XXX
 SG_ BB_PlaceHolder_BASE : 0|8@1+ (1,0) [0|255] "-" CM4

BO_ 2554986535 EVMCDCS1_BASE: 8 Vector__XXX
 SG_ EVmcCabinCondFlag_BASE : 0|2@1+ (1,0) [0|0] "-" CM4
 SG_ EVmcRESScondFlag_BASE : 2|2@1+ (1,0) [0|0] "-" CM4

BO_ 2163223335 crashNotification_BASE: 8 Vector__XXX
 SG_ crashType_BASE : 0|5@1+ (1,0) [0|0] "-" CM4
 SG_ CNcntE2E_BASE : 56|4@1+ (1,0) [0|15] "-" CM4
 SG_ CNchkE2E_BASE : 60|4@1+ (1,0) [0|15] "-" CM4

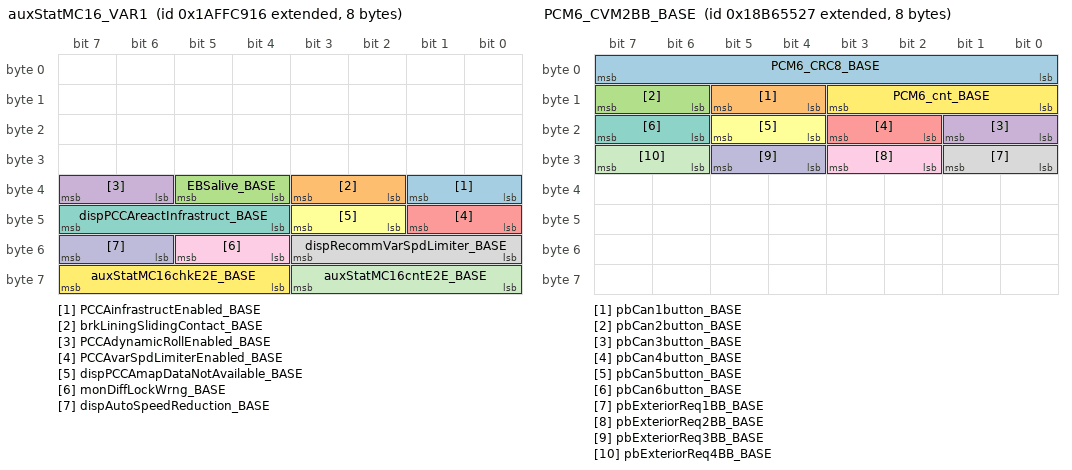
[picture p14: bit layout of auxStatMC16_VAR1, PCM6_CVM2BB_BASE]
BO_ 2600454422 auxStatMC16_VAR1: 8 Vector__XXX
 SG_ PCCAinfrastructEnabled_BASE : 32|2@1+ (1,0) [0|0] "-" CM4
 SG_ brkLiningSlidingContact_BASE : 34|2@1+ (1,0) [0|0] "-" CM4
 SG_ EBSalive_BASE : 36|2@1+ (1,0) [0|0] "-" CM4
 SG_ PCCAdynamicRollEnabled_BASE : 38|2@1+ (1,0) [0|0] "-" CM4
 SG_ PCCAvarSpdLimiterEnabled_BASE : 40|2@1+ (1,0) [0|0] "-" CM4
 SG_ dispPCCAmapDataNotAvailable_BASE : 42|2@1+ (1,0) [0|0] "-" CM4
 SG_ dispPCCAreactInfrastruct_BASE : 44|4@1+ (1,0) [0|0] "-" CM4
 SG_ dispRecommVarSpdLimiter_BASE : 48|4@1+ (1,0) [0|0] "-" CM4
 SG_ monDiffLockWrng_BASE : 52|2@1+ (1,0) [0|0] "-" CM4
 SG_ dispAutoSpeedReduction_BASE : 54|2@1+ (1,0) [0|0] "-" CM4
 SG_ auxStatMC16cntE2E_BASE : 56|4@1+ (1,0) [0|15] "-" CM4
 SG_ auxStatMC16chkE2E_BASE : 60|4@1+ (1,0) [0|15] "-" CM4

BO_ 2562086183 PCM6_CVM2BB_BASE: 8 Vector__XXX
 SG_ PCM6_CRC8_BASE : 0|8@1+ (1,0) [0|255] "-" CM4
 SG_ pbCan1button_BASE : 12|2@1+ (1,0) [0|0] "-" CM4
 SG_ pbCan2button_BASE : 14|2@1+ (1,0) [0|0] "-" CM4
 SG_ pbCan3button_BASE : 16|2@1+ (1,0) [0|0] "-" CM4
 SG_ pbCan4button_BASE : 18|2@1+ (1,0) [0|0] "-" CM4
 SG_ pbCan5button_BASE : 20|2@1+ (1,0) [0|0] "-" CM4
 SG_ pbCan6button_BASE : 22|2@1+ (1,0) [0|0] "-" CM4
 SG_ pbExteriorReq1BB_BASE : 24|2@1+ (1,0) [0|0] "-" CM4
 SG_ pbExteriorReq2BB_BASE : 26|2@1+ (1,0) [0|0] "-" CM4
 SG_ pbExteriorReq3BB_BASE : 28|2@1+ (1,0) [0|0] "-" CM4
 SG_ pbExteriorReq4BB_BASE : 30|2@1+ (1,0) [0|0] "-" CM4
 SG_ PCM6_cnt_BASE : 8|4@1+ (1,0) [0|15] "-" CM4

BO_ 2566540583 EVEI_BASE: 8 Vector__XXX
 SG_ totalTripEnergyConsumed_BASE : 0|32@1+ (0.1,0) [0|421108121.5] "kWh" CM4
 SG_ tripDriveEnergyEconomy_BASE : 32|16@1+ (0.001953125,0) [0|125.498046875] "kWh/km" CM4

BO_ 2600403754 CVM_42_BASE: 8 Vector__XXX
 SG_ ActTransmOutputShaftTrq_BASE : 0|14@1+ (10,-80000) [-80000|83030] "Nm" CM4
 SG_ DrivrDemTransOutputShftTrq_BASE : 16|14@1+ (10,-80000) [-80000|83030] "Nm" CM4

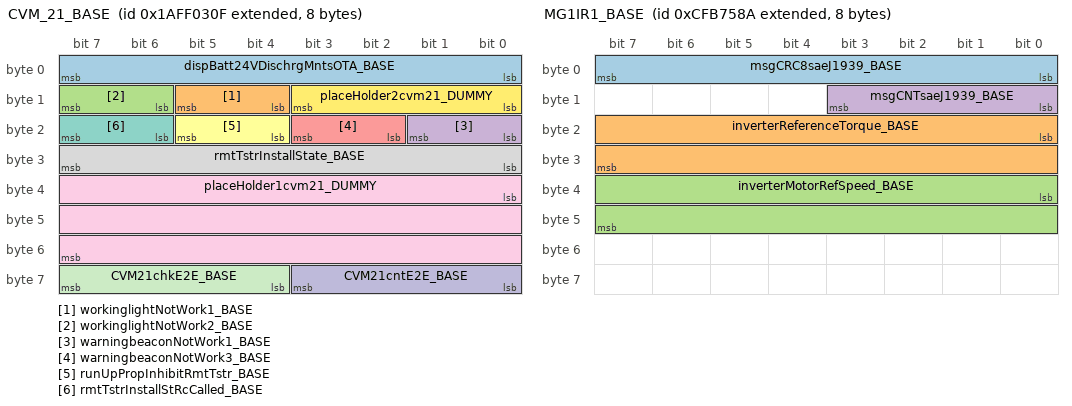
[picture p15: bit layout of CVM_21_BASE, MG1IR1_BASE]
BO_ 2600403727 CVM_21_BASE: 8 Vector__XXX
 SG_ dispBatt24VDischrgMntsOTA_BASE : 0|8@1+ (5,0) [0|1250] "min" CM4
 SG_ workinglightNotWork1_BASE : 12|2@1+ (1,0) [0|0] "-" CM4
 SG_ workinglightNotWork2_BASE : 14|2@1+ (1,0) [0|0] "-" CM4
 SG_ warningbeaconNotWork1_BASE : 16|2@1+ (1,0) [0|0] "-" CM4
 SG_ warningbeaconNotWork3_BASE : 18|2@1+ (1,0) [0|0] "-" CM4
 SG_ runUpPropInhibitRmtTstr_BASE : 20|2@1+ (1,0) [0|0] "-" CM4
 SG_ rmtTstrInstallStRcCalled_BASE : 22|2@1+ (1,0) [0|0] "-" CM4
 SG_ rmtTstrInstallState_BASE : 24|8@1+ (1,0) [0|0] "-" CM4
 SG_ placeHolder1cvm21_DUMMY : 32|24@1+ (1,0) [0|1] "-" CM4
 SG_ CVM21cntE2E_BASE : 56|4@1+ (1,0) [0|15] "-" CM4
 SG_ CVM21chkE2E_BASE : 60|4@1+ (1,0) [0|15] "-" CM4
 SG_ placeHolder2cvm21_DUMMY : 8|4@1+ (1,0) [0|1] "-" CM4

BO_ 2365289866 MG1IR1_BASE: 8 Vector__XXX
 SG_ msgCRC8saeJ1939_BASE : 0|8@1+ (1,0) [0|255] "-" CM4
 SG_ inverterReferenceTorque_BASE : 16|16@1+ (0.5,0) [0|32127.5] "-" CM4
 SG_ inverterMotorRefSpeed_BASE : 32|16@1+ (4,0) [0|257020] "rpm" CM4
 SG_ msgCNTsaeJ1939_BASE : 8|4@1+ (1,0) [0|15] "-" CM4

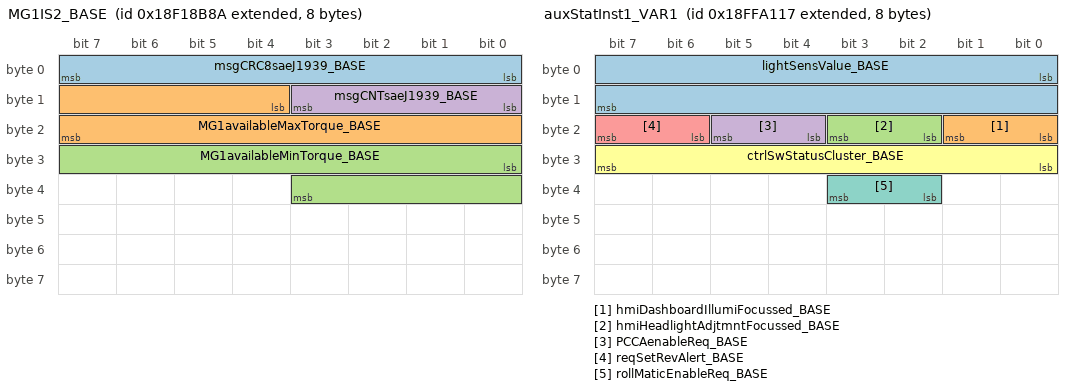
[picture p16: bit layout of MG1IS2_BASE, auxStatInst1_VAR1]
BO_ 2565966730 MG1IS2_BASE: 8 Vector__XXX
 SG_ msgCRC8saeJ1939_BASE : 0|8@1+ (1,0) [0|255] "-" CM4
 SG_ MG1availableMaxTorque_BASE : 12|12@1+ (0.0625,-125) [-125|125.9375] "-" CM4
 SG_ MG1availableMinTorque_BASE : 24|12@1+ (0.0625,-125) [-125|125.9375] "-" CM4
 SG_ msgCNTsaeJ1939_BASE : 8|4@1+ (1,0) [0|15] "-" CM4

BO_ 2566889751 auxStatInst1_VAR1: 8 Vector__XXX
 SG_ lightSensValue_BASE : 0|16@1+ (1,0) [0|5400] "lx" CM4
 SG_ hmiDashboardIllumiFocussed_BASE : 16|2@1+ (1,0) [0|0] "-" CM4
 SG_ hmiHeadlightAdjtmntFocussed_BASE : 18|2@1+ (1,0) [0|0] "-" CM4
 SG_ PCCAenableReq_BASE : 20|2@1+ (1,0) [0|0] "-" CM4
 SG_ reqSetRevAlert_BASE : 22|2@1+ (1,0) [0|0] "-" CM4
 SG_ ctrlSwStatusCluster_BASE : 24|8@1+ (1,0) [0|0] "-" CM4
 SG_ rollMaticEnableReq_BASE : 34|2@1+ (1,0) [0|0] "-" CM4

BO_ 2566890263 auxStatInst3_BASE: 8 Vector__XXX
 SG_ daytimeRunninLightReq_BASE : 0|2@1+ (1,0) [0|0] "-" CM4
 SG_ backgroundLightAutoRevReq_BASE : 12|2@1+ (1,0) [0|0] "-" CM4
 SG_ bckgrndLghtDyNghtMdAutReq_BASE : 14|2@1+ (1,0) [0|0] "-" CM4
 SG_ uiFCWactivWrnReq_BASE : 16|2@1+ (1,0) [0|0] "-" CM4
 SG_ uiFCWactivActWrnReq_BASE : 18|2@1+ (1,0) [0|0] "-" CM4
 SG_ DPFrgnrtnReq_BASE : 2|2@1+ (1,0) [0|0] "-" CM4
 SG_ hmiWarningAGenabledReq_BASE : 20|4@1+ (1,0) [0|0] "-" CM4
 SG_ lccpaEnableReq_BASE : 24|2@1+ (1,0) [0|0] "-" CM4
 SG_ reqHmiSeatVbrtnLft_BASE : 26|2@1+ (1,0) [0|0] "-" CM4
 SG_ reqHmiSeatVbrtnRght_BASE : 28|2@1+ (1,0) [0|0] "-" CM4
 SG_ crpCtrlEnableReq_BASE : 30|2@1+ (1,0) [0|0] "-" CM4
 SG_ bckgrndLghtDyNghtMdManReq_BASE : 32|2@1+ (1,0) [0|0] "-" CM4
 SG_ interiorLightAutoCLreq_BASE : 34|2@1+ (1,0) [0|0] "-" CM4
 SG_ interiorLightAutoReq_BASE : 36|2@1+ (1,0) [0|0] "-" CM4
 SG_ lightWasherReq_BASE : 38|2@1+ (1,0) [0|0] "-" CM4
 SG_ comfModeSlct_BASE : 4|2@1+ (1,0) [0|0] "-" CM4
 SG_ showAxleLoadCntrlReq_BASE : 40|2@1+ (1,0) [0|0] "-" CM4
 SG_ reqLateralLaneAlignmentLKA_BASE : 42|4@1+ (1,0) [0|0] "-" CM4
 SG_ confirmReverseReq_BASE : 46|2@1+ (1,0) [0|0] "-" CM4
 SG_ entranceLightAutoReq_BASE : 48|2@1+ (1,0) [0|0] "-" CM4
 SG_ uiCntrlLockSpeedSelect_BASE : 50|2@1+ (1,0) [0|0] "-" CM4
 SG_ uiCntrlUnlockDoorSelect_BASE : 52|2@1+ (1,0) [0|0] "-" CM4
 SG_ uiDispAddDrvTimePreWarnReq_BASE : 54|2@1+ (1,0) [0|0] "-" CM4
 SG_ intBrkSwReq_BASE : 6|2@1+ (1,0) [0|0] "-" CM4
 SG_ brkmaticOffsetReq_BASE : 8|4@1+ (1,0) [0|12] "km/h" CM4

BO_ 2566890519 auxStatInst4_BASE: 8 Vector__XXX
 SG_ resetTourReason1_BASE : 0|2@1+ (1,0) [0|0] "-" CM4
 SG_ lightTestWithLearnReq_BASE : 16|2@1+ (1,0) [0|0] "-" CM4
 SG_ lightTestWithoutLearnReq_BASE : 18|2@1+ (1,0) [0|0] "-" CM4
 SG_ resetTourReason2_BASE : 2|2@1+ (1,0) [0|0] "-" CM4
 SG_ PCCAinfrastructEnableReq_BASE : 20|2@1+ (1,0) [0|0] "-" CM4
 SG_ PCCAdynamicRollEnableReq_BASE : 22|2@1+ (1,0) [0|0] "-" CM4
 SG_ PCCAvarSpdLimiterEnableReq_BASE : 24|2@1+ (1,0) [0|0] "-" CM4
 SG_ revgPrhbtnSw_BASE : 26|2@1+ (1,0) [0|0] "-" CM4
 SG_ TJAenableReq_BASE : 28|2@1+ (1,0) [0|0] "-" CM4
 SG_ LGAenableReq_BASE : 30|2@1+ (1,0) [0|0] "-" CM4
 SG_ LDWenableReq_BASE : 32|2@1+ (1,0) [0|0] "-" CM4
 SG_ setTirePressAutoMode_BASE : 34|2@1+ (1,0) [0|0] "-" CM4
 SG_ instrWorkg_BASE : 36|2@1+ (1,0) [0|0] "-" CM4
 SG_ payloadReset_BASE : 38|2@1+ (1,0) [0|0] "-" CM4
 SG_ resetTourReason3_BASE : 4|2@1+ (1,0) [0|0] "-" CM4
 SG_ setTireSize_BASE : 40|8@1+ (1,0) [0|250] "-" CM4
 SG_ axleLocSetTireSize_BASE : 48|8@1+ (1,0) [0|0] "-" CM4
 SG_ auxStatInst4cntE2E_BASE : 56|4@1+ (1,0) [0|15] "-" CM4
 SG_ transferCaseCtrlNeutReq_BASE : 6|2@1+ (1,0) [0|0] "-" CM4
 SG_ auxStatInst4chkE2E_BASE : 60|4@1+ (1,0) [0|15] "-" CM4
 SG_ statusAcousticWrnSig_BASE : 8|8@1+ (1,0) [0|0] "-" CM4

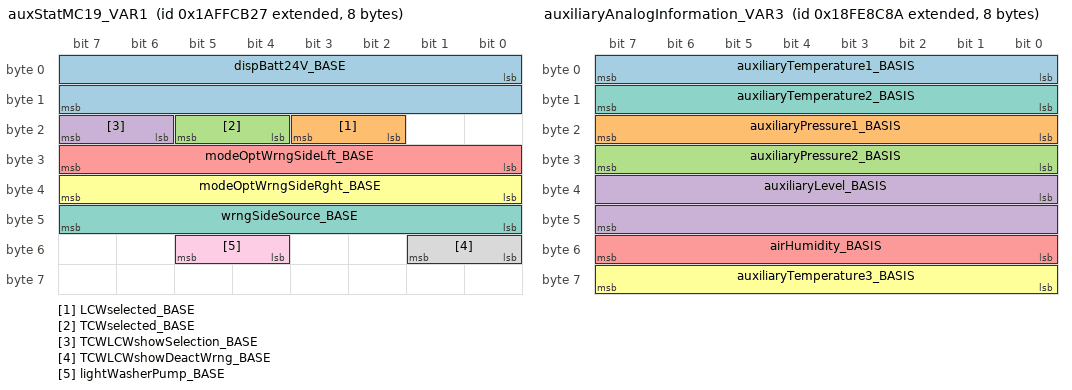
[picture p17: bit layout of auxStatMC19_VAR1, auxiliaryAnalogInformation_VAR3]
BO_ 2600454951 auxStatMC19_VAR1: 8 Vector__XXX
 SG_ dispBatt24V_BASE : 0|16@1+ (0.001,0) [0|64.255] "V" CM4
 SG_ LCWselected_BASE : 18|2@1+ (1,0) [0|0] "-" CM4
 SG_ TCWselected_BASE : 20|2@1+ (1,0) [0|0] "-" CM4
 SG_ TCWLCWshowSelection_BASE : 22|2@1+ (1,0) [0|0] "-" CM4
 SG_ modeOptWrngSideLft_BASE : 24|8@1+ (1,0) [0|0] "-" CM4
 SG_ modeOptWrngSideRght_BASE : 32|8@1+ (1,0) [0|0] "-" CM4
 SG_ wrngSideSource_BASE : 40|8@1+ (1,0) [0|0] "-" CM4
 SG_ TCWLCWshowDeactWrng_BASE : 48|2@1+ (1,0) [0|0] "-" CM4
 SG_ lightWasherPump_BASE : 52|2@1+ (1,0) [0|0] "-" CM4

BO_ 2600454424 auxStatMC23_VAR1: 8 Vector__XXX
 SG_ dispHGBactiveState_BASE : 0|4@1+ (1,0) [0|0] "-" CM4
 SG_ tsiStateLEDreq_BASE : 12|2@1+ (1,0) [0|0] "-" CM4
 SG_ TSInotificationSound_BASE : 14|2@1+ (1,0) [0|0] "-" CM4
 SG_ TSIwrnSound_BASE : 16|2@1+ (1,0) [0|0] "-" CM4
 SG_ reqDispSafeStopEnd_BASE : 18|2@1+ (1,0) [0|0] "-" CM4
 SG_ reqDispSafeStopActive_BASE : 20|2@1+ (1,0) [0|0] "-" CM4
 SG_ dispCrpCtrlAbortPreWarn_BASE : 22|2@1+ (1,0) [0|0] "-" CM4
 SG_ dispCrpCtrlState_BASE : 24|4@1+ (1,0) [0|0] "-" CM4
 SG_ dispCrpCtrlActivationState_BASE : 28|2@1+ (1,0) [0|0] "-" CM4
 SG_ tsiChangeInfoSetting_BASE : 30|2@1+ (1,0) [0|0] "-" CM4
 SG_ tsiToleranceSetting_BASE : 32|6@1+ (1,0) [0|0] "-" CM4
 SG_ tsiEnableSpdWrn_BASE : 38|2@1+ (1,0) [0|0] "-" CM4
 SG_ dispHGBactiveStateAcoustic_BASE : 4|4@1+ (1,0) [0|0] "-" CM4
 SG_ tsiSelectedMode_BASE : 40|4@1+ (1,0) [0|0] "-" CM4
 SG_ dispFCWwarning_BASE : 44|4@1+ (1,0) [0|0] "-" CM4
 SG_ gearNotEfficient_BASE : 48|2@1+ (1,0) [0|0] "-" CM4
 SG_ highThermalLoadOnEngShtdwn_BASE : 50|2@1+ (1,0) [0|0] "-" CM4
 SG_ fcwUiMenuEnable_BASE : 52|2@1+ (1,0) [0|0] "-" CM4
 SG_ ISCroadSweeperActv_BASE : 54|2@1+ (1,0) [0|0] "-" CM4

BO_ 2600454427 auxStatMC26_VAR1: 8 Vector__XXX
 SG_ EBAselected_BASE : 0|2@1+ (1,0) [0|0] "-" CM4
 SG_ EBAsystemEngEnd_BASE : 10|2@1+ (1,0) [0|0] "-" CM4
 SG_ dispADASmenuReq_BASE : 12|2@1+ (1,0) [0|0] "-" CM4
 SG_ muteADASwrnReq_BASE : 14|2@1+ (1,0) [0|0] "-" CM4
 SG_ currMaxSpdPCCA_BASE : 16|8@1+ (0.2,80) [80|130] "km/h" CM4
 SG_ EBAselectedVRU_BASE : 2|2@1+ (1,0) [0|0] "-" CM4
 SG_ bremsomatAvailable_BASE : 24|2@1+ (1,0) [0|0] "-" CM4
 SG_ TAsysActivated_BASE : 26|2@1+ (1,0) [0|0] "-" CM4
 SG_ DVFRlateRevCAMmessage_BASE : 28|2@1+ (1,0) [0|0] "-" CM4
 SG_ ACC_FailureJ10_BASE : 30|2@1+ (1,0) [0|0] "-" CM4
 SG_ dispFrontVehicleAvailable_BASE : 32|2@1+ (1,0) [0|0] "-" CM4
 SG_ attentionGuardAvailable_BASE : 34|2@1+ (1,0) [0|0] "-" CM4
 SG_ hmiWarningAGenabled_BASE : 36|2@1+ (1,0) [0|0] "-" CM4
 SG_ dispDPFactvRgnrtnClngDwn_BASE : 38|2@1+ (1,0) [0|0] "-" CM4
 SG_ EBAsystemAvailableVEH_BASE : 4|2@1+ (1,0) [0|0] "-" CM4
 SG_ CCselectedMode_BASE : 40|3@1+ (1,0) [0|0] "-" CM4
 SG_ TSIuiMenuEnable_BASE : 43|2@1+ (1,0) [0|0] "-" CM4
 SG_ higherLvlCtrlRsp_BASE : 45|3@1+ (1,0) [0|0] "-" CM4
 SG_ reqDispLDWworking_BASE : 48|2@1+ (1,0) [0|0] "-" CM4
 SG_ reqDispLCCPAworking_BASE : 50|2@1+ (1,0) [0|0] "-" CM4
 SG_ reqDispTJAworking_BASE : 52|2@1+ (1,0) [0|0] "-" CM4
 SG_ reqDispLGAworking_BASE : 54|2@1+ (1,0) [0|0] "-" CM4
 SG_ ldwSysState_VAR1 : 56|8@1+ (1,0) [0|0] "-" CM4
 SG_ EBAsystemAvailableVRU_BASE : 6|2@1+ (1,0) [0|0] "-" CM4
 SG_ EBAdispNoSelectPossibleVRU_BASE : 8|2@1+ (1,0) [0|0] "-" CM4

BO_ 2600454428 auxStatMC27_VAR1: 8 Vector__XXX
 SG_ dispVASCmenuReq_BASE : 0|6@1+ (1,0) [0|0] "-" CM4
 SG_ levelLearnTrlStatusSpdLvl_BASE : 12|2@1+ (1,0) [0|0] "-" CM4
 SG_ spdDpndntLvlCtrlStatus_BASE : 14|2@1+ (1,0) [0|0] "-" CM4
 SG_ liftAxleAutoStatus_BASE : 16|3@1+ (1,0) [0|0] "-" CM4
 SG_ relieveAxleNotPossible_BASE : 19|3@1+ (1,0) [0|0] "-" CM4
 SG_ nomLvlNotSet_BASE : 22|2@1+ (1,0) [0|0] "-" CM4
 SG_ lvlCtrlNotPossible_BASE : 24|3@1+ (1,0) [0|0] "-" CM4
 SG_ liftAxleNotPossible_BASE : 27|3@1+ (1,0) [0|0] "-" CM4
 SG_ spdDpndntLvlCtrlRsp_BASE : 30|2@1+ (1,0) [0|0] "-" CM4
 SG_ trctnHlpTrlRefusal_BASE : 32|4@1+ (1,0) [0|0] "-" CM4
 SG_ kneelingOff_BASE : 36|2@1+ (1,0) [0|0] "-" CM4
 SG_ VASCerrorActive_BASE : 38|2@1+ (1,0) [0|0] "-" CM4
 SG_ kneelingNotPossible_BASE : 40|2@1+ (1,0) [0|0] "-" CM4
 SG_ kneelgPrslctAutoState_BASE : 42|2@1+ (1,0) [0|0] "-" CM4
 SG_ belowFAminSteeringLoad_BASE : 44|2@1+ (1,0) [0|0] "-" CM4
 SG_ lccpaSelected_BASE : 46|2@1+ (1,0) [0|0] "-" CM4
 SG_ trctnHlpNotPossible_BASE : 48|3@1+ (1,0) [0|0] "-" CM4
 SG_ lateralLaneAlignmentLKA_BASE : 51|3@1+ (1,0) [0|0] "-" CM4
 SG_ FCWacuteWarningSelected_BASE : 54|2@1+ (1,0) [0|0] "-" CM4
 SG_ FCWwarningSelected_BASE : 56|2@1+ (1,0) [0|0] "-" CM4
 SG_ distanceGuardCollWrn_BASE : 58|3@1+ (1,0) [0|0] "-" CM4
 SG_ levelLearnTrlStatusNL2_BASE : 6|2@1+ (1,0) [0|0] "-" CM4
 SG_ distanceWarning_BASE : 61|3@1+ (1,0) [0|0] "-" CM4
 SG_ levelLearnTrlStatus_BASE : 8|4@1+ (1,0) [0|0] "-" CM4

BO_ 2566891303 auxStatMC6_VAR1: 8 Vector__XXX
 SG_ ASRactvRsp_BASE : 20|2@1+ (1,0) [0|0] "-" CM4
 SG_ curBrkmaticMode_BASE : 24|8@1+ (1,0) [0|0] "-" CM4
 SG_ curBrkmaticSpeedAbs_BASE : 32|8@1+ (1,0) [0|250] "km/h" CM4

BO_ 2600403717 CVM_05_VAR1: 8 Vector__XXX
 SG_ transShiftingServoHSpdf_BASE : 0|16@1+ (0.1,0) [0|100] "%" CM4
 SG_ transShiftingServoLS_BASE : 16|2@1+ (1,0) [0|0] "%" CM4
 SG_ PTO1HS_BASE : 18|2@1+ (1,0) [0|0] "-" CM4
 SG_ PTO2HS_BASE : 20|2@1+ (1,0) [0|0] "-" CM4
 SG_ PTO3HS_BASE : 22|2@1+ (1,0) [0|0] "-" CM4
 SG_ PTO3userReqResp_BASE : 24|2@1+ (1,0) [0|0] "-" CM4
 SG_ signalHorn_BASE : 26|2@1+ (1,0) [0|0] "-" CM4
 SG_ signalHornValveOn_BASE : 28|2@1+ (1,0) [0|0] "-" CM4
 SG_ CAVIcomReq_BASE : 30|2@1+ (1,0) [0|0] "-" CM4
 SG_ elecSteerBackupNotAvail_BASE : 32|2@1+ (1,0) [0|0] "-" CM4
 SG_ LDWselectedCB_BASE : 34|2@1+ (1,0) [0|0] "-" CM4
 SG_ LGAselected_BASE : 36|2@1+ (1,0) [0|0] "-" CM4
 SG_ LKAselected_BASE : 38|2@1+ (1,0) [0|0] "-" CM4
 SG_ reqDispCtrlSteeringWheel_BASE : 40|2@1+ (1,0) [0|0] "-" CM4
 SG_ reqDispHandsOff1_BASE : 42|2@1+ (1,0) [0|0] "-" CM4
 SG_ reqDispHandsOff2_BASE : 44|2@1+ (1,0) [0|0] "-" CM4
 SG_ reqDispHandsOff3_BASE : 46|2@1+ (1,0) [0|0] "-" CM4
 SG_ reqDispLGAactive_BASE : 48|2@1+ (1,0) [0|0] "-" CM4
 SG_ reqDispLGAdeactTemp_BASE : 50|2@1+ (1,0) [0|0] "-" CM4
 SG_ reqDispLGAmodeActive_BASE : 52|2@1+ (1,0) [0|0] "-" CM4
 SG_ slowVoltDecrDtctd_BASE : 54|2@1+ (1,0) [0|0] "-" CM4
 SG_ CVM05cntE2E_BASE : 56|4@1+ (1,0) [0|15] "-" CM4
 SG_ CVM05chkE2E_BASE : 60|4@1+ (1,0) [0|15] "-" CM4

BO_ 2566890279 auxStatMC3_VAR1: 8 Vector__XXX
 SG_ dispDPFregProgress_BASE : 0|8@1+ (0.4,0) [0|100] "%" CM4
 SG_ LDWdispNoActvnReqPossible_BASE : 10|2@1+ (1,0) [0|0] "-" CM4
 SG_ lvlOutOfRgRsp_BASE : 12|2@1+ (1,0) [0|0] "-" CM4
 SG_ drvSwitchNeutralReq_BASE : 14|2@1+ (1,0) [0|0] "-" CM4
 SG_ airFilterClogged_BASE : 16|2@1+ (1,0) [0|0] "-" CM4
 SG_ fuelLvlWarning_BASE : 18|2@1+ (1,0) [0|0] "-" CM4
 SG_ condFuelPrefilterHtngFail_BASE : 20|2@1+ (1,0) [0|0] "-" CM4
 SG_ washerFluidLvlLow_BASE : 22|2@1+ (1,0) [0|0] "-" CM4
 SG_ displayAntiTheftWarning2_BASE : 24|2@1+ (1,0) [0|0] "-" CM4
 SG_ displayAntiTheftWarning_BASE : 26|2@1+ (1,0) [0|0] "-" CM4
 SG_ dispWarningCoolantLvl_BASE : 28|2@1+ (1,0) [0|0] "-" CM4
 SG_ deactInfrFGRwarn_BASE : 30|2@1+ (1,0) [0|0] "-" CM4
 SG_ engineStarterMode_MAN : 32|4@1+ (1,0) [0|0] "-" CM4
 SG_ DPFRgnDrvSysActvReq_BASE : 36|2@1+ (1,0) [0|0] "-" CM4
 SG_ DPFRgnClutchReleaseReq_BASE : 38|2@1+ (1,0) [0|0] "-" CM4
 SG_ DPFRgnReleasePTOreq_BASE : 40|2@1+ (1,0) [0|0] "-" CM4
 SG_ DPFrgnrtnProhReleaseReq_BASE : 42|2@1+ (1,0) [0|0] "-" CM4
 SG_ DPFRgnVehStandStillReq_BASE : 44|2@1+ (1,0) [0|0] "-" CM4
 SG_ DPFRgnWarmUpEngReq_BASE : 46|2@1+ (1,0) [0|0] "-" CM4
 SG_ DPFRgnNeutrGearReq_BASE : 48|2@1+ (1,0) [0|0] "-" CM4
 SG_ DPFRgnParkBrkActvReq_BASE : 50|2@1+ (1,0) [0|0] "-" CM4
 SG_ DPFrgnReleaseAPreq_BASE : 52|2@1+ (1,0) [0|0] "-" CM4
 SG_ DPFrgnReleaseBPReq_BASE : 54|2@1+ (1,0) [0|0] "-" CM4
 SG_ auxStatMC3cntE2E_BASE : 56|4@1+ (1,0) [0|15] "-" CM4
 SG_ auxStatMC3chkE2E_BASE : 60|4@1+ (1,0) [0|15] "-" CM4
 SG_ EBAdispNoSelectionPossible_BASE : 8|2@1+ (1,0) [0|0] "-" CM4

BO_ 2566818954 auxiliaryAnalogInformation_VAR3: 8 Vector__XXX
 SG_ auxiliaryTemperature1_BASIS : 0|8@1+ (1,-40) [-40|210] "°C" CM4
 SG_ auxiliaryPressure1_BASIS : 16|8@1+ (16,0) [0|4000] "kPa" CM4
 SG_ auxiliaryPressure2_BASIS : 24|8@1+ (16,0) [0|4000] "kPa" CM4
 SG_ auxiliaryLevel_BASIS : 32|16@1+ (0.1,0) [0|6425.5] "mm" CM4
 SG_ airHumidity_BASIS : 48|8@1+ (0.4,0) [0|100] "%" CM4
 SG_ auxiliaryTemperature3_BASIS : 56|8@1+ (1,-40) [-40|210] "°C" CM4
 SG_ auxiliaryTemperature2_BASIS : 8|8@1+ (1,-40) [-40|210] "°C" CM4

BO_ 2566743552 engineTemperature4_BASE: 8 Vector__XXX
 SG_ engineCoolantTemperature2_BASE : 0|8@1+ (1,-40) [-40|210] "°C" CM4

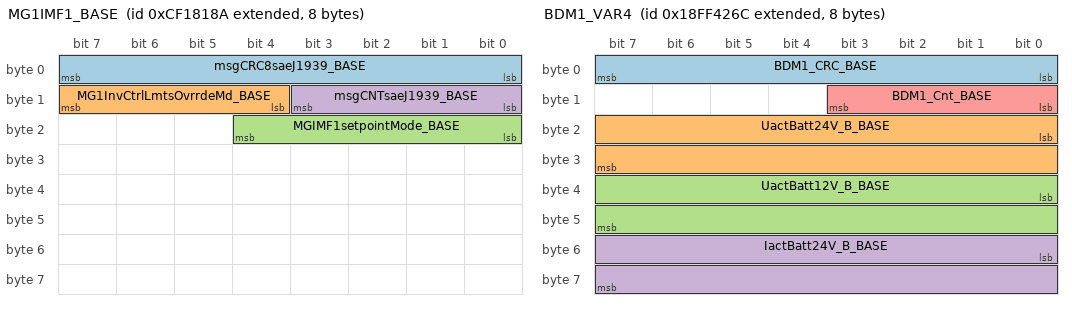
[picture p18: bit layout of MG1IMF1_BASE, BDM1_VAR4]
BO_ 2364637578 MG1IMF1_BASE: 8 Vector__XXX
 SG_ msgCRC8saeJ1939_BASE : 0|8@1+ (1,0) [0|255] "-" CM4
 SG_ MG1InvCtrlLmtsOvrrdeMd_BASE : 12|4@1+ (1,0) [0|0] "-" CM4
 SG_ MGIMF1setpointMode_BASE : 16|5@1+ (1,0) [0|0] "-" CM4
 SG_ msgCNTsaeJ1939_BASE : 8|4@1+ (1,0) [0|15] "-" CM4

BO_ 2600460802 auxStatInst8_BASE: 8 Vector__XXX
 SG_ currSelectMenuID_BASE : 0|16@1+ (1,0) [0|9999] "-" CM4

BO_ 2583662700 BDM6_VAR1: 8 Vector__XXX
 SG_ batt24VchargeOutptAccmlt_B_BASE : 0|16@1+ (5,0) [0|321275] "Ah" CM4
 SG_ batt24VchargeInputAccmlt_B_BASE : 16|16@1+ (5,0) [0|321275] "Ah" CM4

BO_ 2583662741 BDM6_BASE: 8 Vector__XXX
 SG_ batt24VchargeOutputAccmlt_A_BASE : 0|16@1+ (5,0) [0|321275] "Ah" CM4
 SG_ batt24VchargeInputAccmlt_A_BASE : 16|16@1+ (5,0) [0|321275] "Ah" CM4

BO_ 2566865516 BDM1_VAR4: 8 Vector__XXX
 SG_ BDM1_CRC_BASE : 0|8@1+ (1,0) [0|255] "-" CM4
 SG_ UactBatt24V_B_BASE : 16|16@1+ (0.01,0) [0|642.55] "V" CM4
 SG_ UactBatt12V_B_BASE : 32|16@1+ (0.01,0) [0|642.55] "V" CM4
 SG_ IactBatt24V_B_BASE : 48|16@1+ (0.05,-2000) [-2000|1212.75] "A" CM4
 SG_ BDM1_Cnt_BASE : 8|4@1+ (1,0) [0|15] "-" CM4

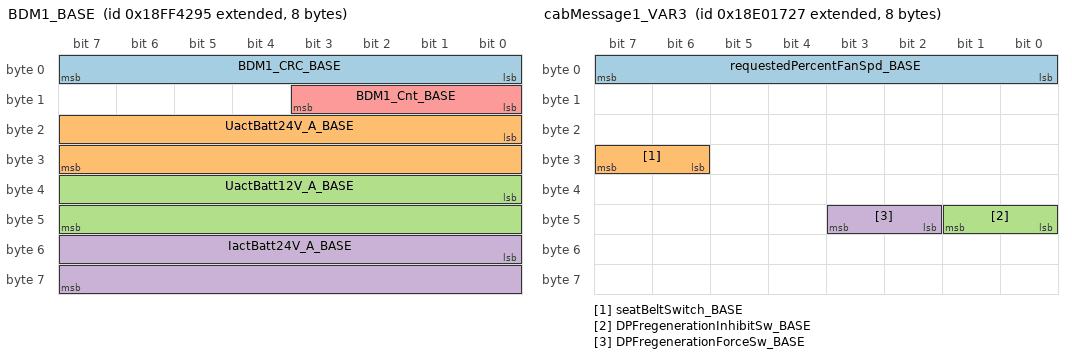
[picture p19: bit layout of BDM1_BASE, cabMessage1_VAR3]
BO_ 2566865557 BDM1_BASE: 8 Vector__XXX
 SG_ BDM1_CRC_BASE : 0|8@1+ (1,0) [0|255] "-" CM4
 SG_ UactBatt24V_A_BASE : 16|16@1+ (0.01,0) [0|642.55] "V" CM4
 SG_ UactBatt12V_A_BASE : 32|16@1+ (0.01,0) [0|642.55] "V" CM4
 SG_ IactBatt24V_A_BASE : 48|16@1+ (0.05,-2000) [-2000|1212.75] "A" CM4
 SG_ BDM1_Cnt_BASE : 8|4@1+ (1,0) [0|15] "-" CM4

BO_ 2564822823 cabMessage1_VAR3: 8 Vector__XXX
 SG_ requestedPercentFanSpd_BASE : 0|8@1+ (0.4,0) [0|100] "%" CM4
 SG_ seatBeltSwitch_BASE : 30|2@1+ (1,0) [0|0] "-" CM4
 SG_ DPFregenerationInhibitSw_BASE : 40|2@1+ (1,0) [0|0] "-" CM4
 SG_ DPFregenerationForceSw_BASE : 42|2@1+ (1,0) [0|0] "-" CM4

CM_ BO_ 2600450599 "CANBOT for E-Mobility OTA information";
CM_ SG_ 2600450599 act24VpowerBCC_BASE "Actual 24V power of the componentes within the battery cooling circuit.";
CM_ SG_ 2600450599 act24VPowHVAC_BASE "Calculated current power consumption from the 24V-electric power supply by the heating-, ventilation- and climatisation-components.";
CM_ SG_ 2600450599 actHVpowerBCC_BASE "Actual HV power of the components within the battery cooling circuit.";
CM_ SG_ 2600450599 actElPowPwrtrn_BASE "Actual electrical power of the powertrain. negative: recuperation positive: consumption";
CM_ BO_ 2600451111 "CANBOT for E-Mobility OTA information";
CM_ SG_ 2600451111 actElPowElHeat_BASE "currently consumed electrical power (HV) of the electric heaters for the passenger cabin";
CM_ SG_ 2600451111 actualTempTES_BASE "Current characteristic total temperature of the TES.";
CM_ SG_ 2600451111 DC24powerFltrd_BASE "Actual electrical power output of the 24V voltage converter (filtered).";
CM_ SG_ 2600451111 PelOutInFlowTES_BASE "power flow / power outflow in/from TES (traction energy storage) positive: charge negative: discharge";
CM_ SG_ 2600451111 SOHactualTES_BASE "Current state of health (SoH) of the TES:";
CM_ SG_ 2600451111 actElPowSteerPump_BASE "Power consumption of the electric hydraulic steering pump.";
CM_ SG_ 2600451111 actElPowAirComp_BASE "Power consumption of the electric air compressor.";
CM_ SG_ 2600451111 actElPowHeatPump_BASE "currently consumed electrical power (HV) of the electric heat pumps for the passenger cabin";
CM_ BO_ 2600416039 "RX message of the Vehicle Connectivity Manager (VCM) for eMobility first use E4C";
CM_ SG_ 2600416039 extrnlChrgWakeUpTime_BASE "By the vehicle control requested duration until wake-up.";
CM_ SG_ 2600416039 remDrivingRangeEnergy_BASE "Remaining range for the existing energy content of the TES.";
CM_ SG_ 2600416039 stateOfChargeTES_BASE "Relative charge state of the TES (traction energy accumulator).";
CM_ SG_ 2600416039 extnlChrgRemTime_BASE "Remaining charging time of the TES (max. three days)";
CM_ BO_ 2600462617 "TX message of the climate system (BKRB) first use in E4C";
CM_ SG_ 2600462617 stHeatPump2_BASE "Feedback of the current status of the heat pump in the front of the vehicle of an articulated bus.";
CM_ SG_ 2600462617 actModeHVAC1_BASE "Current control mode of the climate controller in a solobus or in the rear of the vehicle of an articulated bus.";
CM_ SG_ 2600462617 actModeHVAC2_BASE "Current control mode of the climate controller in the front of the vehicle of an articulated bus.";
CM_ SG_ 2600462617 stElHeat_BASE "Feedback of the current status of the electric heater of the climate system. The individual heaters are communicated sequentially. The corresponding heater can be found in the stElHeatMux signal.";
CM_ SG_ 2600462617 stElHeatMux_BASE "Multiplexer belonging to the signal stElHeat; this shows the status of the heater communicated here.";
CM_ SG_ 2600462617 stCombHeat_BASE "Feedback of the current status of the combustion heater of the climate system.";
CM_ SG_ 2600462617 predModePreCondHVAC1_BASE "Expected control mode of the climate controller in a solobus or in the rear of the vehicle of an articulated bus, once the preconditioning of the vehicle interior is started.";
CM_ SG_ 2600462617 predModePreCondHVAC2_BASE "Expected control mode of the climate controller in the front of the vehicle of an articulated bus, once the preconditioning of the vehicle interior is started.";
CM_ SG_ 2600462617 statePreCondPrepHVAC_BASE "status whether all the preconditions necessary for preconditioning the vehicle interior are fulfilled";
CM_ SG_ 2600462617 actElPowElHeat_BASE "currently consumed electrical power (HV) of the electric heaters for the passenger cabin";
CM_ SG_ 2600462617 actElPowHeatPump_BASE "currently consumed electrical power (HV) of the electric heat pumps for the passenger cabin";
CM_ SG_ 2600462617 stHeatPump1_BASE "Feedback of the current status of the heat pump in a solobus or in the rear of the vehicle of an articulated bus.";
CM_ BO_ 2600465433 "TX message of the climate system (BKRB) first use in E4C";
CM_ SG_ 2600465433 actInsideTemp1_BASE "Actual inside temperature in a solobus or in the rear of the vehicle of an articulated bus.";
CM_ SG_ 2600465433 reqInsideTemp1_BASE "Requested inside temperature in a solobus or in the rear of the vehicle of an articulated bus.";
CM_ SG_ 2600465433 reqInsideTemp2_BASE "Requested inside temperature in the front of the vehicle of an articulated bus.";
CM_ SG_ 2600465433 actInsideTemp2_BASE "Actual inside temperature in the front of the vehicle of an articulated bus.";
CM_ BO_ 2600450855 "CANBOT for E-Mobility OTA information";
CM_ SG_ 2600450855 actualCurrentHDU_BASE "actual current which is flowing through the HDU";
CM_ SG_ 2600450855 energyAvbl_BASE "Actual available energy of the traction energy storage (TES).";
CM_ SG_ 2600450855 plausIactTES_BASE "plausible current current of the traction energy storage. Current direction: a charging current is given with positive, a discharge current with negative values";
CM_ SG_ 2600450855 UactDClink_BASE "Current voltage at the HV connections of the TES (the contactors on the vehicle)";
CM_ BO_ 2565809931 "Returns brake lining wear informations with multiplex concept. Mulitplexor signal is axleNumber. In dependence of the value axleNumber the correspondig brakeLineRemainLeftWheel and brakeLineRemainRightWheel are sent.";
CM_ SG_ 2565809931 AxleNumber_BASE "Return the axles number as a multiplexor signal. Value 0 has not to be used. Direction from front axle to last rear axle. Example: 1st axle -> axleNumber is 1.";
CM_ SG_ 2565809931 brakeLineRemainRightWheel_1_5_BA "The percentage of brake lining which can still be measured for the right wheel on axle n (n is the value of AxleNumber).";
CM_ SG_ 2565809931 BrakeLiniDistRemainLeftWheel_1_5 "BrakeLiniDistRemainLeftWheel_1_5 The available dictance of brake lining which can still be measured for the left wheel on axle n (n is the value of AxleNumber). Brake linings new 0xFB00 Change brake linings 0xFB10 error FE00h to FEFFh not available FF00h ";
CM_ SG_ 2565809931 BrakeLiniDistRemainRghtWheel_1_5 "BrakeLiniDistRemainRghtWheel_1_5 The available dictance of brake lining which can still be measured for the right wheel on axle n (n is the value of AxleNumber). Brake linings new 0xFB00 Change brake linings 0xFB10 error FE00h to FEFFh not available FF00h";
CM_ SG_ 2565809931 brakeLineRemainLeftWheel_1_5_BAS "The percentage of brake lining which can still be measured for the left wheel on axle n (n is the value of AxleNumber).";
CM_ BO_ 2566844672 "MAN proprietary message contains signals related to Cruise Control and Vehicle Speed";
CM_ SG_ 2566844672 parkingBrakeSwitch_BASIS "Switch signal which indicates when the parking brake is set. In general the switch actuated by the operator's park brake control, whether a pedal, lever or other control mechanism.";
CM_ SG_ 2566844672 CCactive_BASIS "Cruise control is switched on. It is not ensured that the engine is controlled by cruise control, as in the case of a large driver's demand the engine is controlled by the driver while cruise control is active (maximum selection of cruise control and driv";
CM_ SG_ 2365479471 nominalLevelFrontAxle_BASIS "Signal which indicates the nominal (desired) height of the front axle to be controlled by the suspension system. These heights are discrete levels. They are the upper level, lower level, normal level 1, normal level 2, normal level 3, customer level, and ";
CM_ SG_ 2365479471 belowNominalLevelRearAxle_BASIS "Signal which indicates whether the actual height of the rear axle is below the nominal (desired) level for the rear axle. For explanations of nominal level see parameter :nominal level front axle.";
CM_ SG_ 2365479471 aboveNominalLevelRearAxle_BASIS "Signal which indicates whether the actual height of the rear axle is above the nominal (desired) level of the rear axle.";
CM_ SG_ 2365479471 levelControlMode_BASIS "Signal which indicates the actual control mode of the air suspension system";
CM_ SG_ 2365479471 nominalLevelRearAxle_BASIS "Signal which indicates the nominal (desired) height of the rear axle to be controlled by the suspension system. For further explanations see SPN 1734 - Nominal Level Front Axle.";
CM_ SG_ 2365479471 belowNominalLevelFrontAxle_BASIS "Signal which indicates whether the actual height of the front axle is below the nominal (desired) level for the front axle. For explanations of nominal level see parameter: nominal level front axle.";
CM_ BO_ 2364539648 "Identifies electronic engine control related parameters.";
CM_ BO_ 2600403746 "CANMSG CVM_34";
CM_ SG_ 2600403746 DCDCavgEfficiency_BASE "The average efficiency of the DC-DC converters to convert HV-power into LV-power.";
CM_ SG_ 2600403746 predBattSysTempVehDep_BASE "The predicted battery system temperature at vehicle departure time.";
CM_ SG_ 2600403746 HVACactMode_BASE "Current operation mode of the HVAC system.";
CM_ SG_ 2600403746 AMSactMode_BASE "Current operation mode of the Air Management System (AMS).";
CM_ SG_ 2600403746 CHSactMode_BASE "Current operation mode of the Cooling and Heating System (CHS).";
CM_ SG_ 2600403746 ePTOactMode_BASE "Current operation mode of the electric Power Take Off (ePTO).";
CM_ SG_ 2600403746 DCDCactPowerLV_BASE "Current output LV-power of the DC-DC converters.";
CM_ SG_ 2600403746 reqTempTES_BASE "Set temperature of the high voltage energy storage";
CM_ BO_ 2600403748 "CANMSG CVM_36";
CM_ SG_ 2600403748 AMSenergyNorm_BASE "Currently stored energy in the Air Management System (AMS) energy storage referred to the minimum necessary energy for Normal operation mode (i.e. negative values indicate a not fully conditioned storage).";
CM_ SG_ 2600403748 AMS1sMeanPowerLV_BASE "1 s mean value of the LV-power consumption of the Air Management System (AMS).";
CM_ SG_ 2600403748 AMS1sMeanPowerHV_BASE "1 s mean value of the HV-power consumption of the Air Management System (AMS).";
CM_ BO_ 2600403749 "CANMSG CVM_37";
CM_ SG_ 2600403749 CHSenergyNorm_BASE "Currently stored energy in the Cooling and Heating System (CHS) energy storage referred to the minimum necessary energy for Normal operation mode (i.e. negative values indicate a not fully conditioned storage).";
CM_ SG_ 2600403749 CHS1sMeanPowerLV_BASE "1 s mean value of the LV-power consumption of the Cooling and Heating System (CHS).";
CM_ SG_ 2600403749 CHS1sMeanPowerHV_BASE "1 s mean value of the HV-power consumption of the Cooling and Heating System (CHS).";
CM_ BO_ 2600403750 "CANMSG CVM_38";
CM_ SG_ 2600403750 ePTOenergyNorm_BASE "Currently stored energy in the electric Power Take Off (ePTO) energy storage referred to the minimum necessary energy for Normal operation mode (i.e. negative values indicate a not fully conditioned storage).";
CM_ SG_ 2600403750 ePTO1sMeanPowerLV_BASE "1 s mean value of the LV-power consumption of the electric Power Take Off (ePTO).";
CM_ SG_ 2600403750 ePTO1sMeanPowerHV_BASE "1 s mean value of the HV-power consumption of the electric Power Take Off (ePTO).";
CM_ BO_ 2600403751 "CANMSG CVM_39";
CM_ SG_ 2600403751 HVACenergyNorm_BASE "Currently stored energy in the Heating, Ventilation and Air Conditioning (HVAC) system energy storage referred to the minimum necessary energy for Normal operation mode (i.e. negative values indicate a not fully conditioned storage).";
CM_ SG_ 2600403751 HVAC1sMeanPowerLV_BASE "1 s mean value of the LV-power consumption of the Heating, Ventilation and Air Conditioning (HVAC) System.";
CM_ SG_ 2600403751 HVAC1sMeanPowerHV_BASE "1 s mean value of the HV-power consumption of the Heating, Ventilation and Air Conditioning (HVAC) System.";
CM_ BO_ 2583676915 "BMC13 (MAN spezific)";
CM_ SG_ 2583676915 BattSysDischEnergyTheorMax_BASE "Battery system theoretical available energy";
CM_ SG_ 2583676915 BattPackIdCellModuleTempMax_BASE "Id of battery pack with maximum cell module temperature within the battery system";
CM_ SG_ 2583676915 BattPackIdCellModuleTempMin_BASE "Id of battery pack with minimum cell module temperature within the battery system";
CM_ SG_ 2583676915 BattSysCellModuleTempMin_BASE "Minimum cell module temperature within the battery system";
CM_ SG_ 2583676915 BattSysCellModuleTempMax_BASE "Maximum cell module temperature within the battery system";
CM_ SG_ 2583676915 BattSysSoh_BASE "Battery system state of health";
CM_ BO_ 2566535975 "Electric PTO 1 Information";
CM_ SG_ 2566535975 ePTO1CurrentLimit_BASE "Maximum current ePTO equipment is allowed to draw";
CM_ SG_ 2566535975 ePTO1Current_BASE "Actual current consumed by ePTO equipment";
CM_ SG_ 2566535975 ePTO1Voltage_BASE "Voltage applied at the ePTO equipment terminals";
CM_ BO_ 2566889761 "Proprietary CAN message auxStatZBR1.";
CM_ SG_ 2566889761 haengerABSerkennung_BASIS "Signal indicates, if trailer was detected with ABS functionality or not. If status-signal indicates value not available, trailer is not available.";
CM_ SG_ 2566889761 hybTripReset_BASE "Reset signal for trip kilometres and trip recovery quote.";
CM_ SG_ 2566889761 instrFunktionsfaehig_BASIS "Signal instrument operative/not operative. Notification if instrumentaion takes part on data traffic.";
CM_ SG_ 2566889761 lichttestAktivRueckmeldung_BASIS "signal light test active response";
CM_ SG_ 2566889761 kontrVersorgAnhaengerABS_BASIS "Signal indicates, if trailer-ABS operates correctly or if trailer-ABS requests an indicator lamp.";
CM_ SG_ 2566889761 highBeamOutpState_BASE "State of highbeam outputs";
CM_ SG_ 2566889761 beleuchtungHaenger1erkannt_BASIS "Internal Analysis of indicator outputs trailer left and right and brakelight trailer";
CM_ SG_ 2566889761 infoNotaus_BASIS "Signal indicates if emergency shut off has been pressed or not.";
CM_ BO_ 2565865739 "brake control information";
CM_ SG_ 2565865739 ABSactive_BASIS "State signal which indicates that the ABS is active. The signal is set when...";
CM_ SG_ 2565865739 BPposition_BASIS "Ratio of brake pedal position to maximum pedal position. Used for electric brake applications. 0% means no braking. Also when there are two brake pedals on the machine the maximum of the two should be transmitted for Brake Pedal Position.";
CM_ BO_ 2364539904 "Electronic Engine Controller 1 - Engine related parameters.";
CM_ SG_ 2364539904 engineTorqueMode_BASIS "State signal which indicates which engine torque mode is currently generating, limiting, or controlling the torque. Note that the modes are not in prioritized order. Not all modes may be relevant for a given device. Some devices may not implement all func";
CM_ SG_ 2364539904 actualEnginePercentTorque_BASIS "The calculated output torque of the engine. The data is transmitted in indicated torque as a percent of reference engine torque (see the engine configuration message, PGN 65251). The engine percent torque value will not be less than zero and it includes t";
CM_ SG_ 2364539904 engineSpeed_BASIS "Actual engine speed which is calculated over a minimum crankshaft angle of 720 degrees divided by the number of cylinders.";
CM_ SG_ 2364539904 actEngPerTorqHR_BASE "displays an additional torque in percent of the reference engine torque.";
CM_ SG_ 2364539904 engineDemandPercentTorque_BASIS "Engine Demand-Percent Torque";
CM_ SG_ 2364539904 driverDemandEnginePercentTorque_ "The requested torque output of the engine by the driver. It is based on input from the following requestors external to the powertrain: operator (via the accelerator pedal), cruise control and/or road speed limit governor. Dynamic commands from internal p";
CM_ SG_ 2633942787 rangeHighActuator_BASIS "Identifies the status of the range high actuator in the auxiliary unit.";
CM_ SG_ 2633942787 rangeLowActuator_BASIS "Identifies the status of the range low actuator in the auxiliary unit.";
CM_ SG_ 2633942787 splitterDirectActuator_BASIS "Identifies the status of the splitter direct actuator in the auxiliary unit.";
CM_ SG_ 2633942787 splitterIndirectActuator_BASIS "Identifies the status of the splitter indirect actuator in the auxiliary unit.";
CM_ BO_ 2565867838 "SAE: 10ms , MAN: 20ms Vehicle Dynamic Stability Control 2; Contains information which relates to the vehicle's movement.";
CM_ SG_ 2565867838 steeringWheelAngle_BASIS "The main operator's steering wheel angle (on the steering column, not the actual wheel angle). The vehicle being steered to the left results in a positive steering wheel angle.";
CM_ BO_ 2600454443 "CANMSG auxStatMC42";
CM_ SG_ 2600454443 vehDepartTimeMinutesDlyd_BASE "Component 'minute' of the updated delayed departure time, if the charging process can't be completed until the original departure time.";
CM_ SG_ 2600454443 extnlChrgRemTime_VAR1 "Remaining charging time of the TES (max. three days)";
CM_ SG_ 2600454443 totalEnergyConsumption_BASE "overall energy consumption over the vehicle life";
CM_ SG_ 2600454443 vehDepartTimeDelayDlyd_BASE "Updated delayed departure delay time (holding time), if the charging process can't be completed until the original departure time.";
CM_ SG_ 2566889767 vehSpdLimWrn_BASE "Shows a warning at overspeed";
CM_ SG_ 2566889767 drvSysReadyToMove_BASE "Signal indicates whether the indicator light for the driving readiness display is to be switched on.";
CM_ BO_ 2583676659 "BMC12 (MAN spezific)";
CM_ SG_ 2583676659 BattPack1State_BASE "Battery pack 1 state";
CM_ SG_ 2583676659 BattPack4State_BASE "Battery pack 4 state";
CM_ SG_ 2583676659 BattPack5State_BASE "Battery pack 5 state";
CM_ SG_ 2583676659 BattPack6State_BASE "Battery pack 6 state";
CM_ SG_ 2583676659 BattPack7State_BASE "Battery pack 7 state";
CM_ SG_ 2583676659 BattPackLast1State_BASE "High voltage Last Battery Pack State on the first Battery System CAN";
CM_ SG_ 2583676659 BattPack9State_BASE "Battery pack 9 state";
CM_ SG_ 2583676659 BattPack10State_BASE "Battery pack 10 state";
CM_ SG_ 2583676659 BattPack2State_BASE "Battery pack 2 state";
CM_ SG_ 2583676659 BattPack11State_BASE "Battery pack 11 state";
CM_ SG_ 2583676659 BattPack12State_BASE "Battery pack 12 state";
CM_ SG_ 2583676659 BattPack13State_BASE "Battery pack 13 state";
CM_ SG_ 2583676659 BattPack14State_BASE "Battery pack 14 state";
CM_ SG_ 2583676659 BattPack15State_BASE "Battery pack 15 state";
CM_ SG_ 2583676659 BattPackLast2State_BASE "High voltage Last Battery Pack State on the second Battery System CAN";
CM_ SG_ 2583676659 BattPack3State_BASE "Battery pack 3 state";
CM_ SG_ 2583676403 battPackLast2TempSpreadMax_BASE "Maximum temperature spread within last high voltage battery pack on the second Battery System CAN";
CM_ SG_ 2583676403 BattSysInterResistanceCh_BASE "Internal resistance charge";
CM_ SG_ 2583676403 BattSysInterResistanceDisch_BASE "Internal resistance discharge";
CM_ SG_ 2583674611 BattPack1Temp_BASE "Battery pack 1 temperature";
CM_ SG_ 2583674611 BattPack2Temp_BASE "Battery pack 2 temperature";
CM_ SG_ 2583674611 BattPack3Temp_BASE "Battery pack 3 temperature";
CM_ SG_ 2583674611 BattPack4Temp_BASE "Battery pack 4 temperature";
CM_ SG_ 2583674867 BattPack5Temp_BASE "Battery pack 5 temperature";
CM_ SG_ 2583674867 BattPack6Temp_BASE "Battery pack 6 temperature";
CM_ SG_ 2583674867 BattPack7Temp_BASE "Battery pack 7 temperature";
CM_ SG_ 2583674867 BattPackLast1Temp_BASE "High Voltage Last Battery Pack Temperature on the first Battery System CAN";
CM_ SG_ 2583675123 BattPack9Temp_BASE "Battery pack 9 temperature";
CM_ SG_ 2583675123 BattPack10Temp_BASE "Battery pack 10 temperature";
CM_ SG_ 2583675123 BattPack11Temp_BASE "Battery pack 11 temperature";
CM_ SG_ 2583675123 BattPack12Temp_BASE "Battery pack 12 temperature";
CM_ SG_ 2583675379 BattPack13Temp_BASE "Battery pack 13 temperature";
CM_ SG_ 2583675379 BattPack14Temp_BASE "Battery pack 14 temperature";
CM_ SG_ 2583675379 BattPack15Temp_BASE "Battery pack 15 temperature";
CM_ SG_ 2583675379 BattPackLast2Temp_BASE "High Voltage Last Battery Pack Temperature on the second Battery System CAN";
CM_ BO_ 2566801959 "ETC7 Transmission status information from the transmission controller to network. In difference to SAE J1939 signal is cyclic 1000 ms and on Event 100 ms. ";
CM_ SG_ 2566801959 transmissionMode1indicator_BASIS "This state signal is the transmission¿s indication that it is operating under transmission mode 1 (SPN 1852) as commanded via the TC1 message (PGN 256). The definition of the transmission mode is left to the discretion of the transmission manufacturer.";
CM_ SG_ 2583674355 BattSysTechSoc_BASE "Battery system technical SOC";
CM_ SG_ 2583674355 BattSysVltgLimMax_BASE "Battery system upper voltage limit";
CM_ SG_ 2583674355 BattSysDodSocMax_BASE "Upper user SOC limit";
CM_ SG_ 2583674355 BattSysDodSocMin_BASE "Lower user SOC limit";
CM_ SG_ 2583674355 BattSysIsoMeasResult_BASE "Result of the isolation measurement";
CM_ SG_ 2583674355 BattSysIsoMeasState_BASE "Isolation measurement state";
CM_ SG_ 2583639335 vehProfileLength_BASE "Lenght of vehicle combination according profile setting. Unit (m or ft) is managed centrally. 102.3 - error 102.35 - not available";
CM_ SG_ 2583639335 vehProfileWeightofAxle_BASE "Maximum axle load according vehicle profile setting. 0 - No profile selected. 127000 - error 127500 - not available";
CM_ SG_ 2583639335 vehProfileWeightofDblAxles_BASE "Maximum double axle load according vehicle profile setting. 127000 - error 127500 - not available";
CM_ SG_ 2583639335 vehProfileHeight_BASE "Height of vehicle according profile setting. Unit (m or ft) is managed centrally. 12.7 - error 12.75 - not available";
CM_ SG_ 2583639335 vehProfileNumberOfAxles_BASE "Number of axles of the vehicle combination according profile setting. 0 - No profile selected. 14 - error 15 - not available";
CM_ SG_ 2583639335 vehProfileWidth_BASE "Width of vehicle according profile setting. Unit (m or ft) is managed centrally. 3.1 - error 3.15 - not available";
CM_ SG_ 2583639335 vehProfileTunnelCat_BASE "The signal describes if the tunnel restriction applies due to dangerous goods.";
CM_ BO_ 2600403752 "CANMSG CVM_40";
CM_ SG_ 2600403752 DCDCactPowerHV_BASE "Current HV-power consumption of the DC-DC converters.";
CM_ SG_ 2600403752 sMeanPowerTES_BASE "1 s mean value of the power output of the Traction Energy Storage (TES). Power flowing into the TES has a positive sign, power flowing out of the TES has a negative sign.";
CM_ SG_ 2600403752 BattSysTechSoc_BASE "Battery system technical SOC";
CM_ BO_ 2600403753 "CANMSG CVM_41";
CM_ SG_ 2600403753 BattSysChCurrLimDyn_BASE "Dynamic charge current limit";
CM_ SG_ 2600403753 extrnlChrgImaxLim_BASE "Maximum charging current allowed the by the vehicle.";
CM_ SG_ 2600403753 extrnlChrgTargetCurrHR_BASE "Requested nominal charging current at the charger (AC charging) or charging infrastructure (DC charging).";
CM_ SG_ 2600403753 extrnlChrgDCchrgngCurrent_BASE "Measured DC current of the active charging interface.";
CM_ BO_ 2562153767 "Message for controlling external camera hub";
CM_ SG_ 2562153767 hubVidInpUpdateTrigger_BASE "Trigger signal for the Camera Hub to start checking the video input ports for attached cameras.";
CM_ SG_ 2562153767 cameraHubTrigger3req_BASE "Camera Hub Input Trigger to route Video signal to Video Output from Video Input Port 3";
CM_ SG_ 2562153767 cameraHubTrigger2req_BASE "Camera Hub Input Trigger to route Video signal to Video Output from Video Input Port 2";
CM_ SG_ 2562153767 cameraHubTrigger4req_BASE "Camera Hub Input Trigger to route Video signal to Video Output from Video Input Port 4";
CM_ SG_ 2562153767 cameraHubTrigger1req_BASE "Camera Hub Input Trigger to route Video signal to Video Output from Video Input Port 1";
CM_ BO_ 2600407304 "prop. message for the transmission of customer-specific signals";
CM_ SG_ 2600407304 placeholderCuIntf15_BASE "placeholder signal";
CM_ BO_ 2600407309 "prop. message for the transmission of customer-specific signals";
CM_ SG_ 2600407309 placeholderCuIntf20_BASE "placeholder signal";
CM_ BO_ 2600407307 "prop. message for the transmission of customer-specific signals";
CM_ SG_ 2600407307 placeholderCuIntf18_BASE "placeholder signal";
CM_ BO_ 2600407308 "prop. message for the transmission of customer-specific signals";
CM_ SG_ 2600407308 placeholderCuIntf19_BASE "placeholder signal";
CM_ BO_ 2600407306 "prop. message for the transmission of customer-specific signals";
CM_ SG_ 2600407306 placeholderCuIntf17_BASE "placeholder signal";
CM_ BO_ 2600407305 "prop. message for the transmission of customer-specific signals";
CM_ SG_ 2600407305 placeholderCuIntf16_BASE "placeholder signal";
CM_ BO_ 2566575655 "This message is sent by the CA that manages the connection to Electric Vehicle Supply Equipment (EVSE). This PG is related to the physical connection and is generic to all types of EVSE (AC or DC).";
CM_ SG_ 2566575655 inletContactorState_BASE "The state of the contactors fitted to this power inlet. If the EVCC controls contactors fitted to its associated power inlet then this SP shall report their state.";
CM_ SG_ 2566575655 EVSEconnectorLockState_BASE "Indicates the state of this EVSE Connector Lock (if present).";
CM_ BO_ 2365561639 "bodyBuilderInfo5";
CM_ BO_ 2554986535 "This message carries status of the vehicle during DC charging to the EVCC or EVSE.";
CM_ SG_ 2554986535 EVmcCabinCondFlag_BASE "Informs the EVSE that the EV is performing cabin conditioning";
CM_ SG_ 2554986535 EVmcRESScondFlag_BASE "Informs the EVSE that the EV is using energy from the EVSE to perform battery (RESS or HVES) conditioning.";
CM_ BO_ 2163223335 "Crash Notification  Devices developed to the standard published after June 2019 will transmit this message at a rate of 500 ms.  Additionally, these devices will also transmit this message every 20 ms for at least 3 s when a crash is detected.";
CM_ SG_ 2163223335 crashType_BASE "Type of crash event.";
CM_ SG_ 2163223335 CNcntE2E_BASE "counter of end-to-end communication protection";
CM_ SG_ 2163223335 CNchkE2E_BASE "checksum of end-to-end communication protection";
CM_ SG_ 2600454422 PCCAinfrastructEnabled_BASE "Activation state of PCCA function reaction on intrastructure after user input.";
CM_ SG_ 2600454422 brkLiningSlidingContact_BASE "The signal indicates whether a brake lining wear of the towing vehicle is insufficient (detection by sliding contacts).";
CM_ SG_ 2600454422 PCCAdynamicRollEnabled_BASE "Activation state of PCCA function dynamic rolling after user input.";
CM_ SG_ 2600454422 PCCAvarSpdLimiterEnabled_BASE "Activation state of PCCA function variable speed limiter after user input.";
CM_ SG_ 2600454422 dispPCCAmapDataNotAvailable_BASE "The Signal indicates if map data are currently not available for efficient cruise.";
CM_ SG_ 2600454422 dispPCCAreactInfrastruct_BASE "Signal indicates, on which infrastrukture element of PCCA the ACC/FGR has been disabled.";
CM_ SG_ 2600454422 dispRecommVarSpdLimiter_BASE "Signal indicates the recommendation to the driver for the variable speed limiter.";
CM_ SG_ 2600454422 monDiffLockWrng_BASE "Warning in case state of differential locks does not match the expectations.";
CM_ SG_ 2600454422 auxStatMC16chkE2E_BASE "checksum of end-to-end communication protection";
CM_ BO_ 2562086183 "CAN message from Push Button CAN (CPB) 1 to CVM ASP 2 Data ID: 192 93 236 107 13 195 1 146 123 194 104 226 212 53 198 112; Data ID No: 374; OnEvent and Cylcic: 1000 ms Cylic, On Event (push button) 50 ms.";
CM_ SG_ 2562086183 PCM6_CRC8_BASE "CRC8 Autosar Profile 2 with Data ID";
CM_ SG_ 2562086183 pbCan1button_BASE "Feedback CAN push button";
CM_ SG_ 2562086183 pbCan2button_BASE "Feedback CAN push button";
CM_ SG_ 2562086183 pbCan3button_BASE "Feedback CAN push button";
CM_ SG_ 2562086183 pbCan4button_BASE "Feedback CAN push button";
CM_ SG_ 2562086183 pbCan5button_BASE "Feedback CAN push button";
CM_ SG_ 2562086183 pbCan6button_BASE "Feedback CAN push button";
CM_ SG_ 2562086183 pbExteriorReq1BB_BASE "Push Button 1 Door";
CM_ SG_ 2562086183 pbExteriorReq2BB_BASE "Push Button 2 Door";
CM_ SG_ 2562086183 pbExteriorReq3BB_BASE "Push Button 3 Door";
CM_ SG_ 2562086183 pbExteriorReq4BB_BASE "Push Button 4 Door";
CM_ SG_ 2562086183 PCM6_cnt_BASE "Cnt Autosar Profile 2";
CM_ BO_ 2566540583 "EV Economy Information";
CM_ SG_ 2566540583 totalTripEnergyConsumed_BASE "Energy consumed by all the vehicle active powertrain and electrified accessories since the last Trip Reset. (See PGN 56832 RESET)";
CM_ SG_ 2566540583 tripDriveEnergyEconomy_BASE "Trip Drive Energy Economy (i.e. powertrain and electrified accessory energy) is equal to the electric vehicle Total Trip Energy Consumed (SPN 20876) divided by the vehicle distance traveled (in KM) since the last Trip Reset. (See PGN 56832 RESET)";
CM_ BO_ 2600403754 "CANMSG CVM_42";
CM_ SG_ 2600403754 ActTransmOutputShaftTrq_BASE "reserved range from raw value: 0x3FB0/dec 16304 to 0x3FDF/dec 16351; error range from raw value: 0x3FE0/dec 16352 to 0x3FEF/dec 16367; not available range from raw value: 0x3FF0/dec 16368 to 0x3FFF/dec 16383";
CM_ SG_ 2600403754 DrivrDemTransOutputShftTrq_BASE "reserved range from raw value: 0x3FB0/dec 16304 to 0x3FDF/dec 16351; error range from raw value: 0x3FE0/dec 16352 to 0x3FEF/dec 16367; not available range from raw value: 0x3FF0/dec 16368 to 0x3FFF/dec 16383";
CM_ BO_ 2600403727 "prop. message of CVM2";
CM_ SG_ 2600403727 dispBatt24VDischrgMntsOTA_BASE "Estimated maximum discharge time in minutes during an OTA update until the shut off condition is met.";
CM_ SG_ 2600403727 workinglightNotWork1_BASE "The signal describes, if a not functional workinglight is requested";
CM_ SG_ 2600403727 workinglightNotWork2_BASE "The signal describes, if a not functional workinglight is requested";
CM_ SG_ 2600403727 warningbeaconNotWork1_BASE "The signal describes, if a not functional workinglight is requested";
CM_ SG_ 2600403727 warningbeaconNotWork3_BASE "The signal describes, if a not functional workinglight is requested";
CM_ SG_ 2600403727 runUpPropInhibitRmtTstr_BASE "Indicates whether the drive system start up is inhibited or not due to remote tester install state.";
CM_ SG_ 2600403727 rmtTstrInstallStRcCalled_BASE "Indicates, whether the UDS routine control has been executed succesfully (at least one time) during the current powercycle. (A powercycle is defined as the period between the start-up of the ECU and the shut-down or reset of the ECU.)";
CM_ SG_ 2600403727 rmtTstrInstallState_BASE "Remote-Tester state persisted in CVM. Details can be found here: https://collaboration.msi.audi.com/confluence/display/MANRMTTST/003+-+Remote-Tester+State+and+State-Transitions Please refer also to: Service Specification for RemoteTesterFeatureList (Servi";
CM_ SG_ 2600403727 CVM21cntE2E_BASE "counter of end-to-end communication protection The counter prevents other ECUs from reacting to a faulty transmission of the PGN and serves as a safety mechanism. The counter is being incremented by 1 for every sent message, starting with 0. (0 follows ";
CM_ SG_ 2600403727 CVM21chkE2E_BASE "checksum of end-to-end communication protection The checksum is used to verify the signal path from the CVM2-ECU to other ECUs.The 4 bit checksum is the sum of the high nibble and the low nibble of the sum of the identifier, the first 7 data bytes and the";
CM_ BO_ 2365289866 "Motor Generator 1 Inverter Reference 1 msg id: 0x00FB758A";
CM_ SG_ 2365289866 msgCRC8saeJ1939_BASE "CRC8 SAE J1939";
CM_ SG_ 2365289866 inverterReferenceTorque_BASE "This value is used for converting torque in percent to units of Nm";
CM_ SG_ 2365289866 inverterMotorRefSpeed_BASE "Reference motor speed of the drive inverter. This value is used for converting speed in percent to units of rpm. SAE-SPN: 10171";
CM_ SG_ 2365289866 msgCNTsaeJ1939_BASE "The message counter is used to detect situations where the transmitting ECU malfunction repeats the same frame all the time. The receiver of the information may use the counter parameter to detect this situation. The transmitting device will increase the ";
CM_ BO_ 2565966730 "Second Status Message from the Inverter 1";
CM_ SG_ 2565966730 msgCRC8saeJ1939_BASE "CRC8 SAE J1939";
CM_ SG_ 2565966730 MG1availableMaxTorque_BASE "This is an estimate of the maximum available motor torque including active deratings at the present motor speed.";
CM_ SG_ 2565966730 MG1availableMinTorque_BASE "This is an estimate of the minimum available motor torque including active deratings at the present motor speed.";
CM_ SG_ 2565966730 msgCNTsaeJ1939_BASE "The message counter is used to detect situations where the transmitting ECU malfunction repeats the same frame all the time. The receiver of the information may use the counter parameter to detect this situation. The transmitting device will increase the ";
CM_ SG_ 2566889751 lightSensValue_BASE "signal of brightness sensor";
CM_ SG_ 2566889751 PCCAenableReq_BASE "Activation Request PCCA (predictive cruise control)";
CM_ SG_ 2566889751 reqSetRevAlert_BASE "This signal requests the default behaviour of the acoustic output of the reversing warning device.";
CM_ SG_ 2566889751 ctrlSwStatusCluster_BASE "Indicated status of the user input for intermediate speed control without MFL";
CM_ SG_ 2566890263 hmiWarningAGenabledReq_BASE "Signal indicates if the attnetionGuard HIM warning ist requested by the driver if drowsiness is detected.";
CM_ SG_ 2566890263 lccpaEnableReq_BASE "Signal indicates an user request to enable LCCPA (LaneChangeCollisionPreventionAssist).";
CM_ SG_ 2566890263 reqHmiSeatVbrtnLft_BASE "This signal defines a cluster request for the generation of a vibration in the vehicle.";
CM_ SG_ 2566890263 reqHmiSeatVbrtnRght_BASE "This signal defines a cluster request for the generation of a vibration in the vehicle.";
CM_ SG_ 2566890263 crpCtrlEnableReq_BASE "Benutzeranforderung zum Aktivieren oder Deaktivieren der Kriechmomentennachbildung. User request to activate or deactivate the creep torque emulation (pulse for changing state)";
CM_ SG_ 2566890263 showAxleLoadCntrlReq_BASE "This signal informs if there is a request for the display of the starting aid control.";
CM_ SG_ 2566890263 reqLateralLaneAlignmentLKA_BASE "Indicates the lateral alignment in the lane, which is requested via the guidance menu.";
CM_ SG_ 2566890519 PCCAinfrastructEnableReq_BASE "User request for activation or deactivation of PCCA function reaction on infrastructure. If an user request occurs, the signal is set for one sending cycle to the value 1.";
CM_ SG_ 2566890519 PCCAdynamicRollEnableReq_BASE "User request for activation or deactivation of PCCA function dynamic rolling. If an user request occurs, the signal is set for one sending cycle to the value 1.";
CM_ SG_ 2566890519 PCCAvarSpdLimiterEnableReq_BASE "User request for activation or deactivation of PCCA function variable speed limiter. If an user request occurs, the signal is set for one sending cycle to the value 1.";
CM_ SG_ 2566890519 TJAenableReq_BASE "User request to select traffic jam assist.";
CM_ SG_ 2566890519 LGAenableReq_BASE "User request to select lane guard assist.";
CM_ SG_ 2566890519 LDWenableReq_BASE "User request to select lane departure warning.";
CM_ SG_ 2566890519 setTirePressAutoMode_BASE "Signal contains the user request for manually or automatically tire pressure setting.";
CM_ SG_ 2566890519 instrWorkg_BASE "Signal indicates, if the display of the intrument is working or not working.";
CM_ SG_ 2566890519 payloadReset_BASE "Signal to reset the dispalyed payload.";
CM_ SG_ 2566890519 setTireSize_BASE "Signal describe the user request for the selection of tire size for a specific axle.";
CM_ SG_ 2566890519 auxStatInst4cntE2E_BASE "counter of end-to-end communication protection";
CM_ SG_ 2566890519 auxStatInst4chkE2E_BASE "checksum of end-to-end communication protection";
CM_ SG_ 2600454951 LCWselected_BASE "Signal shows, whether the LCW-system was selected by the driver (Lane Change Warning).";
CM_ SG_ 2600454951 TCWselected_BASE "Signal shows, whether the TCW-system (Turn Collision Warning) was sewlected by the driver.";
CM_ SG_ 2600454951 TCWLCWshowSelection_BASE "Signal requests that the selection menu for TCW and LCW is displayed.";
CM_ SG_ 2600454951 modeOptWrngSideLft_BASE "Arbitrated warning level on the left a-pillar warning lamp or the left monitor of the camera-monitor-system.";
CM_ SG_ 2600454951 modeOptWrngSideRght_BASE "Arbitrated warning level on the left a-pillar warning lamp or the left monitor of the camera-monitor-system.";
CM_ SG_ 2600454951 wrngSideSource_BASE "Source of a warning issued on the a-pillar warning lamps or the monitor of the camera-monitor-system.";
CM_ BO_ 2600454424 "prop. channel - displays from management computer to cluster";
CM_ SG_ 2600454424 dispHGBactiveState_BASE "This signal controls the optical display of the maximum speed limiter (HGB1).";
CM_ SG_ 2600454424 tsiStateLEDreq_BASE "This signal controls if the tell-tale ISA OFF is to be displayed to the driver.";
CM_ SG_ 2600454424 TSInotificationSound_BASE "The signal requests the TSI notification sound.";
CM_ SG_ 2600454424 TSIwrnSound_BASE "The signal describes if the TSI warning sound should be played or not.";
CM_ SG_ 2600454424 reqDispSafeStopEnd_BASE "Request to display SafeStop beeing completed";
CM_ SG_ 2600454424 reqDispSafeStopActive_BASE "Request to display SafeStop beeing active";
CM_ SG_ 2600454424 dispCrpCtrlAbortPreWarn_BASE "Display if creep torque emulation will be aborted.";
CM_ SG_ 2600454424 dispCrpCtrlState_BASE "Displays if creep torque emulation is available and active.";
CM_ SG_ 2600454424 dispCrpCtrlActivationState_BASE "Displays the activation state of the creep torque emulation.";
CM_ SG_ 2600454424 tsiChangeInfoSetting_BASE "This signal shows the current status of the sound notfication setting. The sound notification is provided when the speed limit changed.";
CM_ SG_ 2600454424 tsiToleranceSetting_BASE "Speed limit tolerance for the speed limit violation warning. Current tolerance setting value.";
CM_ SG_ 2600454424 tsiEnableSpdWrn_BASE "This signal shows the current status of the speed warning enabled setting.";
CM_ SG_ 2600454424 dispHGBactiveStateAcoustic_BASE "This signal controls the acoustic warning of the maximum speed limiter (HGB1).";
CM_ SG_ 2600454424 tsiSelectedMode_BASE "The signal is used to display the operation mode of the traffic sign information.";
CM_ SG_ 2600454424 dispFCWwarning_BASE "This signal outputs the calculated Front Detection Warning Level (FCW).";
CM_ SG_ 2600454424 gearNotEfficient_BASE "The Signal shows if the OD gear in the GW Gearbox is not the most efficient gear.";
CM_ SG_ 2600454424 highThermalLoadOnEngShtdwn_BASE "signal indicates whether a high thermal load of the powertrain is detected in order to suggest engine overrun before engine shutdown";
CM_ SG_ 2600454424 fcwUiMenuEnable_BASE "Request to grey out items in the menu for FCW.";
CM_ SG_ 2600454424 ISCroadSweeperActv_BASE "Intermediate Speed Control Sweepter Active";
CM_ SG_ 2600454427 EBAselected_BASE "This signal indicates, if the EBA is selected by the driver.";
CM_ SG_ 2600454427 EBAsystemEngEnd_BASE "This signal indicates whether the EBA system was active in the intervention (braking).";
CM_ SG_ 2600454427 dispADASmenuReq_BASE "Driver request to open the ADAS menu";
CM_ SG_ 2600454427 muteADASwrnReq_BASE "Driver request to mute the warnings of all ADAS functions.";
CM_ SG_ 2600454427 currMaxSpdPCCA_BASE "The signal indicates the current maximum speed for PCCA system";
CM_ SG_ 2600454427 EBAselectedVRU_BASE "This signal indicates, if the VRU component (Vulnerable Road User) of the EBA is selected by the driver.";
CM_ SG_ 2600454427 bremsomatAvailable_BASE "This signal indicates if the brakematic-System is available";
CM_ SG_ 2600454427 TAsysActivated_BASE "The signal shows, whether or not the turn alert system is active. An active system warns pedestrians about possibly dangerous turns, if certain driving conditions are met.";
CM_ SG_ 2600454427 DVFRlateRevCAMmessage_BASE "This signal triggers the message on the cluster, that a reverse camera might be activated too late. Too late refers to the requested 2 seconds for a camera to be shown after the reverse gear was set.";
CM_ SG_ 2600454427 ACC_FailureJ10_BASE "Adaptive Cruise Control failure ISO 7000-2581 Symbol trigger J.10";
CM_ SG_ 2600454427 dispFrontVehicleAvailable_BASE "This signal indicates if displaying the front vehicle information is available";
CM_ SG_ 2600454427 attentionGuardAvailable_BASE "This signal indicates if the attentionGuard-System is available";
CM_ SG_ 2600454427 hmiWarningAGenabled_BASE "This signal indicates if attentionGuard HMI output is enabled. If enabled, it also defines the kind of HMI warning (acoustic, visual or both).";
CM_ SG_ 2600454427 dispDPFactvRgnrtnClngDwn_BASE "Status of display information of DPF regeneration cool down phase";
CM_ SG_ 2600454427 EBAsystemAvailableVEH_BASE "This signal indicates, if the Emergency Brake Assist (EBA) is available.";
CM_ SG_ 2600454427 CCselectedMode_BASE "This signal indicates which longitudinal assistance system is preselected.";
CM_ SG_ 2600454427 TSIuiMenuEnable_BASE "Request to disable the settings in the TSI (Traffic Sign Information) user menu. (Disabled settings are displayed in grey).";
CM_ SG_ 2600454427 higherLvlCtrlRsp_BASE "This signal describes the status of the higher speed dependant level control.";
CM_ SG_ 2600454427 reqDispLDWworking_BASE "Indicates whether LDW should be displayed as working";
CM_ SG_ 2600454427 reqDispLCCPAworking_BASE "Indicates whether LCCPA should be displayed as working";
CM_ SG_ 2600454427 reqDispTJAworking_BASE "Indicates whether TJA should be displayed as working";
CM_ SG_ 2600454427 reqDispLGAworking_BASE "Indicates whether LGA should be displayed as working";
CM_ SG_ 2600454427 ldwSysState_VAR1 "The signal outputs the status of the LDW.";
CM_ SG_ 2600454427 EBAsystemAvailableVRU_BASE "This signal indicates, if the Emergency Brake Assist (EBA) is available.";
CM_ SG_ 2600454427 EBAdispNoSelectPossibleVRU_BASE "Display when actuating the EBA-VRU checkbox if the VRU component of the EBA system cannot be preselected.";
CM_ BO_ 2600454428 "prop. channel - displays from management computer to cluster";
CM_ SG_ 2600454428 dispVASCmenuReq_BASE "This signal defines the current level control state of the air suspension control for the automatic activation of the menu.";
CM_ SG_ 2600454428 levelLearnTrlStatusSpdLvl_BASE "This signal indicates whether the speed dependant level is approached.";
CM_ SG_ 2600454428 liftAxleAutoStatus_BASE "This signal indicates whether the lift axle automatically lowers due to exceedance of legal axle loads or lifts due to undershoot of a parametrizable axle load.";
CM_ SG_ 2600454428 relieveAxleNotPossible_BASE "This signal indicates that unloading of the tag axle is not possible with indication of the cause.";
CM_ SG_ 2600454428 nomLvlNotSet_BASE "Signal indicates the feedback nominal level not set";
CM_ SG_ 2600454428 lvlCtrlNotPossible_BASE "This signal indicates that a control process has not been started or has been aborted with indication of the cause.";
CM_ SG_ 2600454428 spdDpndntLvlCtrlRsp_BASE "This signal indicates if the function speed dependant level control is activated.";
CM_ SG_ 2600454428 trctnHlpTrlRefusal_BASE "This signal describes the reason for deactivation of the traction help of the trailer.";
CM_ SG_ 2600454428 kneelingOff_BASE "The signal indicates, whether the kneeling function is deactivated.";
CM_ SG_ 2600454428 VASCerrorActive_BASE "This signal informs the driver, that the air suspension control system still has an error.";
CM_ SG_ 2600454428 kneelingNotPossible_BASE "Feedback that kneeling cannot be activated.";
CM_ SG_ 2600454428 kneelgPrslctAutoState_BASE "This signal describes whether kneeling preselect or kneeling automatic is active.";
CM_ SG_ 2600454428 belowFAminSteeringLoad_BASE "This signal indicates the undershoot of the front axle steering load.";
CM_ SG_ 2600454428 lccpaSelected_BASE "Signal indicates that LCCPA is selected (LaneChangeCollisionPreventionAssist).";
CM_ SG_ 2600454428 lateralLaneAlignmentLKA_BASE "Indicates the lateral alignment in the lane";
CM_ SG_ 2600454428 FCWacuteWarningSelected_BASE "Signal shows, whether the FCW acute warning was selected by the driver (Front Collision Warning).";
CM_ SG_ 2600454428 FCWwarningSelected_BASE "Signal shows, whether the FCW warning was selected by the driver (Front Collision Warning).";
CM_ SG_ 2600454428 distanceGuardCollWrn_BASE "Signal to control the warnings for the function Distance Guard, when a collision is imminent.";
CM_ SG_ 2600454428 levelLearnTrlStatusNL2_BASE "This signal indicates whether the second driving level is approached.";
CM_ SG_ 2600454428 distanceWarning_BASE "Warning, if the vehicle is keeping not enough distance to the preceeding vehicle.";
CM_ SG_ 2600454428 levelLearnTrlStatus_BASE "This signal describes the status of level learning of the trailer.";
CM_ BO_ 2566891303 "MAN proprietary message contains information related to display (state signals) from Management Computer (MC)";
CM_ SG_ 2600403717 transShiftingServoHSpdf_BASE "Pulse duty factor of the high side output for shifting servo.";
CM_ SG_ 2600403717 CAVIcomReq_BASE "With this signal, the ComReq for the stationary function is requested";
CM_ SG_ 2600403717 LGAselected_BASE "Signal indicates that LGA system is activated (Lane Guard Assist).";
CM_ SG_ 2600403717 reqDispCtrlSteeringWheel_BASE "Request to display the demand on the driver to control the steering wheel.";
CM_ SG_ 2600403717 reqDispHandsOff1_BASE "Request to display the demand to the driver to control the steering wheel (hands-off detection for 15 s, escalation level 1).";
CM_ SG_ 2600403717 reqDispHandsOff2_BASE "Request to display the demand to the driver to control the steering wheel (hands-off detection for 30 s, escalation level 2).";
CM_ SG_ 2600403717 reqDispHandsOff3_BASE "Request to display traffic jam assist beeing deactivated by driving hands-off (hands-off detection for 60 s, escalation level 3).";
CM_ SG_ 2600403717 reqDispLGAactive_BASE "Request to display an active LaneGuardAssist (LGA) intervention";
CM_ SG_ 2600403717 reqDispLGAdeactTemp_BASE "Request to display LaneGuardAssist (LGA) beeing temporarly deactivated.";
CM_ SG_ 2600403717 CVM05chkE2E_BASE "checksum of end-to-end communication protection";
CM_ SG_ 2566890279 displayAntiTheftWarning2_BASE "Driver Information: component locked by AntiTheft";
CM_ SG_ 2566890279 displayAntiTheftWarning_BASE "Driver Information: driving prohibited by AntiTheft";
CM_ SG_ 2566890279 auxStatMC3cntE2E_BASE "counter of end-to-end communication protection";
CM_ SG_ 2566890279 auxStatMC3chkE2E_BASE "checksum of end-to-end communication protection";
CM_ BO_ 2566818954 "auxiliary Analog Information (used for urea sensor)";
CM_ SG_ 2566818954 auxiliaryTemperature1_BASIS "Auxiliary Temperature 1";
CM_ SG_ 2566818954 auxiliaryPressure1_BASIS "Auxiliary Pressure 1";
CM_ SG_ 2566818954 auxiliaryPressure2_BASIS "Auxiliary Pressure 2";
CM_ SG_ 2566818954 auxiliaryLevel_BASIS "Level measured by a sensor";
CM_ SG_ 2566818954 airHumidity_BASIS "air humidity";
CM_ SG_ 2566818954 auxiliaryTemperature3_BASIS "Auxiliary Temperature 3";
CM_ SG_ 2566818954 auxiliaryTemperature2_BASIS "Auxiliary Temperature 2";
CM_ BO_ 2566743552 "Engine temperatures.";
CM_ SG_ 2566743552 engineCoolantTemperature2_BASE "Second temperature of liquid found in the engine cooling system.";
CM_ BO_ 2364637578 "Motor/Generator 1 Inverter Mode Feedback 1 MsgId: 0x00F1818A";
CM_ SG_ 2364637578 msgCRC8saeJ1939_BASE "CRC8 SAE J1939";
CM_ SG_ 2364637578 MG1InvCtrlLmtsOvrrdeMd_BASE "Motor Generator 1 Inverter Control Limits Override Mode";
CM_ SG_ 2364637578 MGIMF1setpointMode_BASE "Reports the inverter mode";
CM_ SG_ 2364637578 msgCNTsaeJ1939_BASE "The message counter is used to detect situations where the transmitting ECU malfunction repeats the same frame all the time. The receiver of the information may use the counter parameter to detect this situation. The transmitting device will increase the ";
CM_ BO_ 2600460802 "CANMSG auxStatInst8";
CM_ SG_ 2600460802 currSelectMenuID_BASE "This signal indicates the currently selected menu, sub-menu, detail view or drop-down entry by signalling the corresponding menu ID.";
CM_ BO_ 2583662700 "Transmit message 6 of the Battery Data Module (BDM)";
CM_ SG_ 2583662700 batt24VchargeOutptAccmlt_B_BASE "Total charge output used over the service life of 24V battery set B.";
CM_ SG_ 2583662700 batt24VchargeInputAccmlt_B_BASE "Total charge input used over the service life of 24V battery set B.";
CM_ BO_ 2583662741 "Transmit message 6 of the Battery Data Module (BDM)";
CM_ SG_ 2583662741 batt24VchargeOutputAccmlt_A_BASE "Total charge output used over the service life of 24V battery set A.";
CM_ SG_ 2583662741 batt24VchargeInputAccmlt_A_BASE "Total charge input used over the service life of 24V battery set A.";
CM_ BO_ 2566865516 "Transmit message 1 of the Battery Data Module (BDM). E2E Protection Autosarprofile 2. Data ID: 15 45 136 26 32 178 94 56 162 249 54 24 230 97 250 76";
CM_ SG_ 2566865516 BDM1_CRC_BASE "The message checksum is used to verify the signal path from the transmitting device to the receiving device.";
CM_ SG_ 2566865516 UactBatt24V_B_BASE "Actual voltage at battery set B at the 24V electrical system.";
CM_ SG_ 2566865516 UactBatt12V_B_BASE "Actual voltage at the battery (battery set B) whose negative terminal is connected directly with the vehicle body. Remark: battery set of 12V batteries connected in series.";
CM_ SG_ 2566865516 IactBatt24V_B_BASE "Actual current battery set B at the 24V electrical system. Discharge currents of the battery are negative.";
CM_ SG_ 2566865516 BDM1_Cnt_BASE "Counter of end-to-end communication protection. Refer to SPN 3189 (counter) of SAE J1939 standard.";
CM_ BO_ 2566865557 "Transmit message 1 of the Battery Data Module (BDM). E2E Protection Autosarprofile 2. Data ID: 185 36 221 84 152 229 183 135 81 219 113 49 249 38 67 109";
CM_ SG_ 2566865557 BDM1_CRC_BASE "The message checksum is used to verify the signal path from the transmitting device to the receiving device.";
CM_ SG_ 2566865557 UactBatt24V_A_BASE "Actual voltage at battery set A at the 24V electrical system.";
CM_ SG_ 2566865557 UactBatt12V_A_BASE "Actual voltage at the battery (battery set A) whose negative terminal is connected directly with the vehicle body. Remark: battery set of 12V batteries connected in series.";
CM_ SG_ 2566865557 IactBatt24V_A_BASE "Actual current battery set A at the 24V electrical system. Discharge currents of the battery are negative.";
CM_ SG_ 2566865557 BDM1_Cnt_BASE "Counter of end-to-end communication protection. Refer to SPN 3189 (counter) of SAE J1939 standard.";
BA_DEF_ SG_  "SigType" ENUM  "DEFAULT","RANGE","RANGESIGNED","ASCII","DISCRETE","CONTROL","REFERENCEPGN","DTC","STRINGDELIMITER","STRINGLENGTH","STRINGLENGTHCONTROL","vector_leerstring";
BA_DEF_ SG_  "GenSigSendType" ENUM  "Cyclic","OnWrite","reserved","OnChange","reserved","reserved","reserved","NoSigSendType";
BA_DEF_ BO_  "VFrameFormat" ENUM  "CAN Standard","CAN Extended","reserved","J1939PG","reserved","reserved","reserved","reserved","reserved","reserved","reserved","reserved","reserved","reserved","StandardCAN_FD","ExtendedCAN_FD","vector_leerstring";
BA_DEF_ BO_  "GenMsgSendType" ENUM  "cyclic","reserved","cyclicIfActive","reserved","reserved","reserved","reserved","reserved","noMsgSendType","vector_leerstring";
BA_DEF_ BO_  "GenMsgCycleTime" INT 0 3600000;
BA_DEF_ BO_  "GenMsgStartDelayTime" INT 0 0;
BA_DEF_ BO_  "GenMsgILSupport" ENUM  "No","Yes","vector_leerstring";
BA_DEF_ SG_  "SystemSignalLongSymbol" STRING ;
BA_DEF_ BO_  "SystemMessageLongSymbol" STRING ;
BA_DEF_DEF_  "SigType" "DEFAULT";
BA_DEF_DEF_  "VFrameFormat" "CAN Extended";
BA_DEF_DEF_  "GenMsgSendType" "noMsgSendType";
BA_DEF_DEF_  "GenMsgCycleTime" 1000;
BA_DEF_DEF_  "GenMsgStartDelayTime" 0;
BA_DEF_DEF_  "GenMsgILSupport" "Yes";
BA_DEF_DEF_  "SystemSignalLongSymbol" "";
BA_DEF_DEF_  "GenSigSendType" "NoSigSendType";

BA_ "GenMsgILSupport" BO_ 2600450599 0;
BA_ "GenMsgSendType" BO_ 2600450599 0;
BA_ "VFrameFormat" BO_ 2600450599 3;

BA_ "GenMsgSendType" BO_ 2600451111 0;
BA_ "VFrameFormat" BO_ 2600451111 3;

BA_ "GenMsgSendType" BO_ 2600416039 0;
BA_ "VFrameFormat" BO_ 2600416039 3;

BA_ "GenMsgSendType" BO_ 2600462617 0;
BA_ "GenMsgCycleTime" BO_ 2600462617 100;
BA_ "VFrameFormat" BO_ 2600462617 3;

BA_ "GenMsgSendType" BO_ 2600465433 0;
BA_ "GenMsgCycleTime" BO_ 2600465433 500;
BA_ "VFrameFormat" BO_ 2600465433 3;

BA_ "GenMsgILSupport" BO_ 2600450855 0;
BA_ "GenMsgSendType" BO_ 2600450855 0;
BA_ "VFrameFormat" BO_ 2600450855 3;

BA_ "GenMsgILSupport" BO_ 2565809931 0;
BA_ "GenMsgSendType" BO_ 2565809931 0;

BA_ "GenMsgSendType" BO_ 2566844672 0;
BA_ "GenMsgCycleTime" BO_ 2566844672 100;
BA_ "GenMsgStartDelayTime" BO_ 2566844672 10;

BA_ "GenMsgSendType" BO_ 2365479471 0;
BA_ "GenMsgCycleTime" BO_ 2365479471 100;

BA_ "GenMsgSendType" BO_ 2364539648 0;
BA_ "GenMsgCycleTime" BO_ 2364539648 50;

BA_ "GenMsgILSupport" BO_ 2600403746 0;
BA_ "GenMsgSendType" BO_ 2600403746 0;

BA_ "GenMsgILSupport" BO_ 2600403748 0;
BA_ "GenMsgSendType" BO_ 2600403748 0;

BA_ "GenMsgILSupport" BO_ 2600403749 0;
BA_ "GenMsgSendType" BO_ 2600403749 0;

BA_ "GenMsgILSupport" BO_ 2600403750 0;
BA_ "GenMsgSendType" BO_ 2600403750 0;

BA_ "GenMsgILSupport" BO_ 2600403751 0;
BA_ "GenMsgSendType" BO_ 2600403751 0;

BA_ "GenMsgSendType" BO_ 2583676915 0;
BA_ "VFrameFormat" BO_ 2583676915 3;

BA_ "GenMsgILSupport" BO_ 2566535975 0;
BA_ "GenMsgSendType" BO_ 2566535975 0;
BA_ "GenMsgCycleTime" BO_ 2566535975 100;

BA_ "GenMsgILSupport" BO_ 2566889761 0;

BA_ "GenMsgSendType" BO_ 2565865739 0;
BA_ "GenMsgCycleTime" BO_ 2565865739 100;
BA_ "VFrameFormat" BO_ 2565865739 3;

BA_ "GenMsgSendType" BO_ 2364539904 0;
BA_ "GenMsgCycleTime" BO_ 2364539904 10;

BA_ "GenMsgSendType" BO_ 2565865487 0;
BA_ "GenMsgCycleTime" BO_ 2565865487 100;

BA_ "GenMsgSendType" BO_ 2633942787 0;
BA_ "GenMsgCycleTime" BO_ 2633942787 100;
BA_ "GenMsgStartDelayTime" BO_ 2633942787 90;

BA_ "GenMsgILSupport" BO_ 2566799393 0;

BA_ "GenMsgILSupport" BO_ 2565867838 0;
BA_ "GenMsgSendType" BO_ 2565867838 0;
BA_ "GenMsgCycleTime" BO_ 2565867838 20;

BA_ "GenMsgILSupport" BO_ 2600454443 0;
BA_ "GenMsgSendType" BO_ 2600454443 0;
BA_ "GenMsgCycleTime" BO_ 2600454443 5000;

BA_ "GenMsgSendType" BO_ 2566811434 0;
BA_ "GenMsgCycleTime" BO_ 2566811434 100;

BA_ "GenMsgSendType" BO_ 2566889767 0;
BA_ "GenMsgCycleTime" BO_ 2566889767 100;

BA_ "GenMsgSendType" BO_ 2566913831 0;
BA_ "GenMsgCycleTime" BO_ 2566913831 100;
BA_ "VFrameFormat" BO_ 2566913831 3;

BA_ "GenMsgSendType" BO_ 2583676659 0;
BA_ "VFrameFormat" BO_ 2583676659 3;

BA_ "GenMsgSendType" BO_ 2583676403 0;
BA_ "VFrameFormat" BO_ 2583676403 3;

BA_ "GenMsgSendType" BO_ 2583674611 0;
BA_ "VFrameFormat" BO_ 2583674611 3;

BA_ "GenMsgSendType" BO_ 2583674867 0;
BA_ "VFrameFormat" BO_ 2583674867 3;

BA_ "GenMsgSendType" BO_ 2583675123 0;
BA_ "VFrameFormat" BO_ 2583675123 3;

BA_ "GenMsgSendType" BO_ 2583675379 0;
BA_ "VFrameFormat" BO_ 2583675379 3;

BA_ "GenMsgILSupport" BO_ 2566801959 0;

BA_ "GenMsgSendType" BO_ 2583674355 0;
BA_ "GenMsgCycleTime" BO_ 2583674355 100;
BA_ "VFrameFormat" BO_ 2583674355 3;

BA_ "GenMsgILSupport" BO_ 2583639335 0;
BA_ "VFrameFormat" BO_ 2583639335 3;

BA_ "GenMsgILSupport" BO_ 2600403752 0;
BA_ "GenMsgSendType" BO_ 2600403752 0;

BA_ "GenMsgILSupport" BO_ 2600403753 0;
BA_ "GenMsgSendType" BO_ 2600403753 0;

BA_ "GenMsgILSupport" BO_ 2562153767 0;

BA_ "GenMsgILSupport" BO_ 2600407304 0;
BA_ "GenMsgSendType" BO_ 2600407304 0;
BA_ "VFrameFormat" BO_ 2600407304 3;

BA_ "GenMsgILSupport" BO_ 2600407309 0;
BA_ "GenMsgSendType" BO_ 2600407309 0;
BA_ "VFrameFormat" BO_ 2600407309 3;

BA_ "GenMsgILSupport" BO_ 2600407307 0;
BA_ "GenMsgSendType" BO_ 2600407307 0;
BA_ "VFrameFormat" BO_ 2600407307 3;

BA_ "GenMsgILSupport" BO_ 2600407308 0;
BA_ "GenMsgSendType" BO_ 2600407308 0;
BA_ "VFrameFormat" BO_ 2600407308 3;

BA_ "GenMsgILSupport" BO_ 2600407306 0;
BA_ "GenMsgSendType" BO_ 2600407306 0;
BA_ "VFrameFormat" BO_ 2600407306 3;

BA_ "GenMsgILSupport" BO_ 2600407305 0;
BA_ "GenMsgSendType" BO_ 2600407305 0;
BA_ "VFrameFormat" BO_ 2600407305 3;

BA_ "GenMsgILSupport" BO_ 2566575655 0;
BA_ "GenMsgSendType" BO_ 2566575655 0;

BA_ "GenMsgILSupport" BO_ 2365561639 0;
BA_ "GenMsgSendType" BO_ 2365561639 0;
BA_ "GenMsgCycleTime" BO_ 2365561639 20;

BA_ "GenMsgILSupport" BO_ 2554986535 0;
BA_ "GenMsgSendType" BO_ 2554986535 0;

BA_ "GenMsgILSupport" BO_ 2163223335 0;
BA_ "GenMsgCycleTime" BO_ 2163223335 500;

BA_ "GenMsgILSupport" BO_ 2600454422 0;
BA_ "GenMsgCycleTime" BO_ 2600454422 0;
BA_ "VFrameFormat" BO_ 2600454422 3;

BA_ "GenMsgILSupport" BO_ 2562086183 0;

BA_ "GenMsgILSupport" BO_ 2566540583 0;
BA_ "GenMsgSendType" BO_ 2566540583 0;

BA_ "GenMsgILSupport" BO_ 2600403754 0;
BA_ "GenMsgSendType" BO_ 2600403754 0;
BA_ "GenMsgCycleTime" BO_ 2600403754 20;

BA_ "GenMsgILSupport" BO_ 2600403727 0;
BA_ "VFrameFormat" BO_ 2600403727 3;

BA_ "GenMsgSendType" BO_ 2365289866 0;

BA_ "GenMsgILSupport" BO_ 2565966730 0;
BA_ "GenMsgSendType" BO_ 2565966730 0;
BA_ "GenMsgCycleTime" BO_ 2565966730 100;

BA_ "GenMsgILSupport" BO_ 2566889751 0;

BA_ "GenMsgILSupport" BO_ 2566890263 0;

BA_ "GenMsgILSupport" BO_ 2566890519 0;

BA_ "GenMsgILSupport" BO_ 2600454951 0;
BA_ "GenMsgCycleTime" BO_ 2600454951 0;
BA_ "VFrameFormat" BO_ 2600454951 3;

BA_ "GenMsgILSupport" BO_ 2600454424 0;
BA_ "GenMsgCycleTime" BO_ 2600454424 0;

BA_ "GenMsgILSupport" BO_ 2600454427 0;
BA_ "GenMsgCycleTime" BO_ 2600454427 0;
BA_ "VFrameFormat" BO_ 2600454427 3;

BA_ "GenMsgILSupport" BO_ 2600454428 0;
BA_ "GenMsgCycleTime" BO_ 2600454428 0;
BA_ "VFrameFormat" BO_ 2600454428 3;

BA_ "GenMsgILSupport" BO_ 2566891303 0;
BA_ "GenMsgCycleTime" BO_ 2566891303 0;

BA_ "GenMsgILSupport" BO_ 2600403717 0;
BA_ "GenMsgCycleTime" BO_ 2600403717 0;

BA_ "GenMsgILSupport" BO_ 2566890279 0;
BA_ "GenMsgCycleTime" BO_ 2566890279 0;

BA_ "GenMsgSendType" BO_ 2566818954 0;

BA_ "GenMsgSendType" BO_ 2566743552 0;

BA_ "GenMsgILSupport" BO_ 2364637578 0;
BA_ "GenMsgSendType" BO_ 2364637578 0;
BA_ "GenMsgCycleTime" BO_ 2364637578 100;

BA_ "GenMsgILSupport" BO_ 2600460802 0;

BA_ "GenMsgILSupport" BO_ 2583662700 0;
BA_ "GenMsgSendType" BO_ 2583662700 0;
BA_ "GenMsgCycleTime" BO_ 2583662700 5000;

BA_ "GenMsgILSupport" BO_ 2583662741 0;
BA_ "GenMsgSendType" BO_ 2583662741 0;
BA_ "GenMsgCycleTime" BO_ 2583662741 5000;

BA_ "GenMsgILSupport" BO_ 2566865516 0;
BA_ "GenMsgSendType" BO_ 2566865516 0;
BA_ "GenMsgCycleTime" BO_ 2566865516 50;

BA_ "GenMsgILSupport" BO_ 2566865557 0;
BA_ "GenMsgSendType" BO_ 2566865557 0;
BA_ "GenMsgCycleTime" BO_ 2566865557 50;

BA_ "GenMsgILSupport" BO_ 2564822823 0;
BA_ "GenMsgSendType" BO_ 2564822823 0;
BA_ "SystemSignalLongSymbol" SG_ 2565809931 brakeLineRemainRightWheel_1_5_BA "brakeLineRemainRightWheel_1_5_BASE";
BA_ "SystemSignalLongSymbol" SG_ 2565809931 BrakeLiniDistRemainLeftWheel_1_5 "BrakeLiniDistRemainLeftWheel_1_5_BASE";
BA_ "SystemSignalLongSymbol" SG_ 2565809931 BrakeLiniDistRemainRghtWheel_1_5 "BrakeLiniDistRemainRghtWheel_1_5_BASE";
BA_ "SystemSignalLongSymbol" SG_ 2565809931 brakeLineRemainLeftWheel_1_5_BAS "brakeLineRemainLeftWheel_1_5_BASE";
BA_ "SystemSignalLongSymbol" SG_ 2365479471 loweringControlModeFrontAxle_BAS "loweringControlModeFrontAxle_BASIS";
BA_ "SystemSignalLongSymbol" SG_ 2365479471 loweringControlModeRearAxle_BASI "loweringControlModeRearAxle_BASIS";
BA_ "SystemSignalLongSymbol" SG_ 2365479471 liftingControlModeFrontAxle_BASI "liftingControlModeFrontAxle_BASIS";
BA_ "SystemSignalLongSymbol" SG_ 2365479471 allowLvlCtrlDuringBrakingStatus_ "allowLvlCtrlDuringBrakingStatus_BASE";
BA_ "SystemSignalLongSymbol" SG_ 2365479471 speedDependantLevelControlStatus "speedDependantLevelControlStatus_BASE";
BA_ "SystemSignalLongSymbol" SG_ 2365479471 suspensionControlRefusalInfo_BAS "suspensionControlRefusalInfo_BASIS";
BA_ "SystemSignalLongSymbol" SG_ 2364539648 enginePercentLoadAtCurrentSpeed_ "enginePercentLoadAtCurrentSpeed_BASIS";
BA_ "SystemSignalLongSymbol" SG_ 2566889761 schalterFahrniveau1oder2senken_B "schalterFahrniveau1oder2senken_BASIS";
BA_ "SystemSignalLongSymbol" SG_ 2566889761 kraftstoffuellstandZuNiedrig_BAS "kraftstoffuellstandZuNiedrig_BASIS";
BA_ "SystemSignalLongSymbol" SG_ 2566889761 schalterBlinkerRechtsRueckm_BASI "schalterBlinkerRechtsRueckm_BASIS";
BA_ "SystemSignalLongSymbol" SG_ 2565865739 tractionControlOverrideSwitch_BA "tractionControlOverrideSwitch_BASIS";
BA_ "SystemSignalLongSymbol" SG_ 2565865739 engineAuxiliaryShutdownSwitch_BA "engineAuxiliaryShutdownSwitch_BASIS";
BA_ "SystemSignalLongSymbol" SG_ 2565865739 remoteAcceleratorEnableSwitch_BA "remoteAcceleratorEnableSwitch_BASIS";
BA_ "SystemSignalLongSymbol" SG_ 2565865739 sourceAddressOfControllDevice_EB "sourceAddressOfControllDevice_EBC1";
BA_ "SystemSignalLongSymbol" SG_ 2565865739 tractMountTrailerABSwarningSig_B "tractMountTrailerABSwarningSig_BASIS";
BA_ "SystemSignalLongSymbol" SG_ 2364539904 sourceAddressOfControllDevice_BA "sourceAddressOfControllDevice_BASIS";
BA_ "SystemSignalLongSymbol" SG_ 2364539904 driverDemandEnginePercentTorque_ "driverDemandEnginePercentTorque_BASIS";
BA_ "SystemSignalLongSymbol" SG_ 2565865487 driversDemandRetarderPercTorque_ "driversDemandRetarderPercTorque_RE";
BA_ "SystemSignalLongSymbol" SG_ 2633942787 splitterIndirectFastSelector_BAS "splitterIndirectFastSelector_BASIS";
BA_ "SystemSignalLongSymbol" SG_ 2565867838 steeringWheelAngleSensorType_BAS "steeringWheelAngleSensorType_BASIS";
BA_ "GenSigSendType" SG_ 2600450599 act24VpowerBCC_BASE 0;
BA_ "GenSigSendType" SG_ 2600450599 act24VPowHVAC_BASE 0;
BA_ "GenSigSendType" SG_ 2600450599 actHVpowerBCC_BASE 0;
BA_ "GenSigSendType" SG_ 2600450599 actElPowPwrtrn_BASE 0;
BA_ "GenSigSendType" SG_ 2600451111 actElPowElHeat_BASE 0;
BA_ "GenSigSendType" SG_ 2600451111 actualTempTES_BASE 0;
BA_ "GenSigSendType" SG_ 2600451111 DC24powerFltrd_BASE 0;
BA_ "GenSigSendType" SG_ 2600451111 PelOutInFlowTES_BASE 0;
BA_ "GenSigSendType" SG_ 2600451111 SOHactualTES_BASE 0;
BA_ "GenSigSendType" SG_ 2600451111 actElPowSteerPump_BASE 0;
BA_ "GenSigSendType" SG_ 2600451111 actElPowAirComp_BASE 0;
BA_ "GenSigSendType" SG_ 2600451111 actElPowHeatPump_BASE 0;
BA_ "GenSigSendType" SG_ 2600416039 extrnlChrgWakeUpTime_BASE 0;
BA_ "GenSigSendType" SG_ 2600416039 remDrivingRangeEnergy_BASE 0;
BA_ "GenSigSendType" SG_ 2600416039 stateOfChargeTES_BASE 0;
BA_ "GenSigSendType" SG_ 2600416039 extnlChrgRemTime_BASE 0;
BA_ "GenSigSendType" SG_ 2600462617 stHeatPump2_BASE 0;
BA_ "GenSigSendType" SG_ 2600462617 actModeHVAC1_BASE 0;
BA_ "GenSigSendType" SG_ 2600462617 actModeHVAC2_BASE 0;
BA_ "GenSigSendType" SG_ 2600462617 stElHeat_BASE 0;
BA_ "GenSigSendType" SG_ 2600462617 stElHeatMux_BASE 0;
BA_ "GenSigSendType" SG_ 2600462617 stCombHeat_BASE 0;
BA_ "GenSigSendType" SG_ 2600462617 predModePreCondHVAC1_BASE 0;
BA_ "GenSigSendType" SG_ 2600462617 predModePreCondHVAC2_BASE 0;
BA_ "GenSigSendType" SG_ 2600462617 statePreCondPrepHVAC_BASE 0;
BA_ "GenSigSendType" SG_ 2600462617 actElPowElHeat_BASE 0;
BA_ "GenSigSendType" SG_ 2600462617 actElPowHeatPump_BASE 0;
BA_ "GenSigSendType" SG_ 2600462617 stHeatPump1_BASE 0;
BA_ "GenSigSendType" SG_ 2600465433 actInsideTemp1_BASE 0;
BA_ "GenSigSendType" SG_ 2600465433 reqInsideTemp1_BASE 0;
BA_ "GenSigSendType" SG_ 2600465433 reqInsideTemp2_BASE 0;
BA_ "GenSigSendType" SG_ 2600465433 actInsideTemp2_BASE 0;
BA_ "GenSigSendType" SG_ 2600450855 actualCurrentHDU_BASE 0;
BA_ "GenSigSendType" SG_ 2600450855 energyAvbl_BASE 0;
BA_ "GenSigSendType" SG_ 2600450855 plausIactTES_BASE 0;
BA_ "GenSigSendType" SG_ 2600450855 UactDClink_BASE 0;
BA_ "GenSigSendType" SG_ 2565809931 AxleNumber_BASE 0;
BA_ "GenSigSendType" SG_ 2565809931 brakeLineRemainRightWheel_1_5_BA 0;
BA_ "GenSigSendType" SG_ 2565809931 BrakeLiniDistRemainLeftWheel_1_5 0;
BA_ "GenSigSendType" SG_ 2565809931 BrakeLiniDistRemainRghtWheel_1_5 0;
BA_ "GenSigSendType" SG_ 2565809931 brakeLineRemainLeftWheel_1_5_BAS 0;
BA_ "GenSigSendType" SG_ 2566844672 parkingBrakeSwitch_BASIS 0;
BA_ "GenSigSendType" SG_ 2566844672 CCactive_BASIS 0;
BA_ "GenSigSendType" SG_ 2566844672 CCenableSwitch_BASIS 0;
BA_ "GenSigSendType" SG_ 2566844672 brakeSwitch_BASIS 0;
BA_ "GenSigSendType" SG_ 2566844672 clutchSwitch_BASIS 0;
BA_ "GenSigSendType" SG_ 2566844672 CCswitchStatus_BASIS 0;
BA_ "GenSigSendType" SG_ 2566844672 speedLimitEnableSwitch_BASIS 0;
BA_ "GenSigSendType" SG_ 2566844672 CCsetSpeed_BASIS 0;
BA_ "GenSigSendType" SG_ 2566844672 PTOgovernorState_BASE 0;
BA_ "GenSigSendType" SG_ 2566844672 CCstates_BASIS 0;
BA_ "GenSigSendType" SG_ 2566844672 intelligentBrakingSwitch_BASIS 0;
BA_ "GenSigSendType" SG_ 2566844672 FGR_ACCswitch_BASIS 0;
BA_ "GenSigSendType" SG_ 2566844672 wheelBasedVehicleSpeed_VAR1 0;
BA_ "GenSigSendType" SG_ 2365479471 nominalLevelFrontAxle_BASIS 0;
BA_ "GenSigSendType" SG_ 2365479471 belowNominalLevelRearAxle_BASIS 0;
BA_ "GenSigSendType" SG_ 2365479471 aboveNominalLevelFrontAxle_BASIS 0;
BA_ "GenSigSendType" SG_ 2365479471 aboveNominalLevelRearAxle_BASIS 0;
BA_ "GenSigSendType" SG_ 2365479471 loweringControlModeFrontAxle_BAS 0;
BA_ "GenSigSendType" SG_ 2365479471 loweringControlModeRearAxle_BASI 0;
BA_ "GenSigSendType" SG_ 2365479471 liftingControlModeFrontAxle_BASI 0;
BA_ "GenSigSendType" SG_ 2365479471 liftingControlModeRearAxle_BASIS 0;
BA_ "GenSigSendType" SG_ 2365479471 kneelingInformation_BASIS 0;
BA_ "GenSigSendType" SG_ 2365479471 levelControlMode_BASIS 0;
BA_ "GenSigSendType" SG_ 2365479471 securityDevice_BASIS 0;
BA_ "GenSigSendType" SG_ 2365479471 vehicleMotionInhibit_BASIS 0;
BA_ "GenSigSendType" SG_ 2365479471 doorRelease_BASIS 0;
BA_ "GenSigSendType" SG_ 2365479471 liftAxle1position_BASIS 0;
BA_ "GenSigSendType" SG_ 2365479471 nominalLevelRearAxle_BASIS 0;
BA_ "GenSigSendType" SG_ 2365479471 frontAxleBumperRange_BASIS 0;
BA_ "GenSigSendType" SG_ 2365479471 rearAxleBumperRange_BASIS 0;
BA_ "GenSigSendType" SG_ 2365479471 liftAxle2position_BASIS 0;
BA_ "GenSigSendType" SG_ 2365479471 suspensionRemoteControl1_BASIS 0;
BA_ "GenSigSendType" SG_ 2365479471 suspensionRemoteControl2_BASIS 0;
BA_ "GenSigSendType" SG_ 2365479471 allowLvlCtrlDuringBrakingStatus_ 0;
BA_ "GenSigSendType" SG_ 2365479471 speedDependantLevelControlStatus 0;
BA_ "GenSigSendType" SG_ 2365479471 suspensionControlRefusalInfo_BAS 0;
BA_ "GenSigSendType" SG_ 2365479471 belowNominalLevelFrontAxle_BASIS 0;
BA_ "GenSigSendType" SG_ 2364539648 AP1lowIdleSwitch_BASIS 0;
BA_ "GenSigSendType" SG_ 2364539648 enginePercentLoadAtCurrentSpeed_ 0;
BA_ "GenSigSendType" SG_ 2364539648 APkickdownSwitch_BASIS 0;
BA_ "GenSigSendType" SG_ 2364539648 roadSpeedLimitStatus_BASIS 0;
BA_ "GenSigSendType" SG_ 2364539648 actMaxAvailEngPerTorq_BASE 0;
BA_ "GenSigSendType" SG_ 2364539648 APposition1_BASIS 0;
BA_ "GenSigSendType" SG_ 2600403746 DCDCavgEfficiency_BASE 0;
BA_ "GenSigSendType" SG_ 2600403746 predBattSysTempVehDep_BASE 0;
BA_ "GenSigSendType" SG_ 2600403746 HVACactMode_BASE 0;
BA_ "GenSigSendType" SG_ 2600403746 AMSactMode_BASE 0;
BA_ "GenSigSendType" SG_ 2600403746 CHSactMode_BASE 0;
BA_ "GenSigSendType" SG_ 2600403746 ePTOactMode_BASE 0;
BA_ "GenSigSendType" SG_ 2600403746 DCDCactPowerLV_BASE 0;
BA_ "GenSigSendType" SG_ 2600403746 reqTempTES_BASE 0;
BA_ "GenSigSendType" SG_ 2600403748 AMSenergyNorm_BASE 0;
BA_ "GenSigSendType" SG_ 2600403748 AMS1sMeanPowerLV_BASE 0;
BA_ "GenSigSendType" SG_ 2600403748 AMS1sMeanPowerHV_BASE 0;
BA_ "GenSigSendType" SG_ 2600403749 CHSenergyNorm_BASE 0;
BA_ "GenSigSendType" SG_ 2600403749 CHS1sMeanPowerLV_BASE 0;
BA_ "GenSigSendType" SG_ 2600403749 CHS1sMeanPowerHV_BASE 0;
BA_ "GenSigSendType" SG_ 2600403750 ePTOenergyNorm_BASE 0;
BA_ "GenSigSendType" SG_ 2600403750 ePTO1sMeanPowerLV_BASE 0;
BA_ "GenSigSendType" SG_ 2600403750 ePTO1sMeanPowerHV_BASE 0;
BA_ "GenSigSendType" SG_ 2600403751 HVACenergyNorm_BASE 0;
BA_ "GenSigSendType" SG_ 2600403751 HVAC1sMeanPowerLV_BASE 0;
BA_ "GenSigSendType" SG_ 2600403751 HVAC1sMeanPowerHV_BASE 0;
BA_ "GenSigSendType" SG_ 2583676915 BattSysDischEnergyTheorMax_BASE 0;
BA_ "GenSigSendType" SG_ 2583676915 BattPackIdCellModuleTempMax_BASE 0;
BA_ "GenSigSendType" SG_ 2583676915 BattPackIdCellModuleTempMin_BASE 0;
BA_ "GenSigSendType" SG_ 2583676915 BattSysCellModuleTempMin_BASE 0;
BA_ "GenSigSendType" SG_ 2583676915 BattSysCellModuleTempMax_BASE 0;
BA_ "GenSigSendType" SG_ 2583676915 BattSysSoh_BASE 0;
BA_ "GenSigSendType" SG_ 2566535975 ePTO1CurrentLimit_BASE 0;
BA_ "GenSigSendType" SG_ 2566535975 ePTO1Current_BASE 0;
BA_ "GenSigSendType" SG_ 2566535975 ePTO1Voltage_BASE 0;
BA_ "GenSigSendType" SG_ 2566889761 tuerkontaktLinks_BASIS 0;
BA_ "GenSigSendType" SG_ 2566889761 fahrerhausVerriegelung_BASIS 0;
BA_ "GenSigSendType" SG_ 2566889761 haengerABSerkennung_BASIS 0;
BA_ "GenSigSendType" SG_ 2566889761 flammstartAktiv_BASIS 0;
BA_ "GenSigSendType" SG_ 2566889761 fernlichtEinRueckmeldung_BASIS 0;
BA_ "GenSigSendType" SG_ 2566889761 tuerkontaktRechts_BASIS 0;
BA_ "GenSigSendType" SG_ 2566889761 schalterFahrniveau1oder2senken_B 0;
BA_ "GenSigSendType" SG_ 2566889761 hybTripReset_BASE 0;
BA_ "GenSigSendType" SG_ 2566889761 instrFunktionsfaehig_BASIS 0;
BA_ "GenSigSendType" SG_ 2566889761 kraftstoffuellstandZuNiedrig_BAS 0;
BA_ "GenSigSendType" SG_ 2566889761 schalterBlinkerRechtsRueckm_BASI 0;
BA_ "GenSigSendType" SG_ 2566889761 schalterBlinkerLinksRueckm_BASIS 0;
BA_ "GenSigSendType" SG_ 2566889761 lichttestAktivRueckmeldung_BASIS 0;
BA_ "GenSigSendType" SG_ 2566889761 kontrVersorgAnhaengerABS_BASIS 0;
BA_ "GenSigSendType" SG_ 2566889761 highBeamOutpState_BASE 0;
BA_ "GenSigSendType" SG_ 2566889761 beleuchtungHaenger1erkannt_BASIS 0;
BA_ "GenSigSendType" SG_ 2566889761 fahrlichtEinRueckmeldung_BASIS 0;
BA_ "GenSigSendType" SG_ 2566889761 rueckwaertsgangEingelegt_BASIS 0;
BA_ "GenSigSendType" SG_ 2566889761 infoNotaus_BASIS 0;
BA_ "GenSigSendType" SG_ 2565865739 ASRengineControlActPass_BASIS 0;
BA_ "GenSigSendType" SG_ 2565865739 ABSoffroadSwitch_BASIS 0;
BA_ "GenSigSendType" SG_ 2565865739 ASRoffroadSwitch_BASIS 0;
BA_ "GenSigSendType" SG_ 2565865739 ASRbrakeControlActPass_BASIS 0;
BA_ "GenSigSendType" SG_ 2565865739 ASRhillHolderSwitch_BASIS 0;
BA_ "GenSigSendType" SG_ 2565865739 tractionControlOverrideSwitch_BA 0;
BA_ "GenSigSendType" SG_ 2565865739 acceleratorInterlockSwitch_BASIS 0;
BA_ "GenSigSendType" SG_ 2565865739 engineDerateSwitch_BASIS 0;
BA_ "GenSigSendType" SG_ 2565865739 engineAuxiliaryShutdownSwitch_BA 0;
BA_ "GenSigSendType" SG_ 2565865739 remoteAcceleratorEnableSwitch_BA 0;
BA_ "GenSigSendType" SG_ 2565865739 engineRetarderSelection_BASIS 0;
BA_ "GenSigSendType" SG_ 2565865739 ABSactive_BASIS 0;
BA_ "GenSigSendType" SG_ 2565865739 ABSfullyOperational_BASIS 0;
BA_ "GenSigSendType" SG_ 2565865739 EBSredWarningSignal_BASIS 0;
BA_ "GenSigSendType" SG_ 2565865739 ABS_EBSamberWarningSignal_BASIS 0;
BA_ "GenSigSendType" SG_ 2565865739 ATC_ASRinformationSignal_BASIS 0;
BA_ "GenSigSendType" SG_ 2565865739 sourceAddressOfControllDevice_EB 0;
BA_ "GenSigSendType" SG_ 2565865739 haltBrakeSwitch_BASIS 0;
BA_ "GenSigSendType" SG_ 2565865739 EBSbrakeSwitch_BASIS 0;
BA_ "GenSigSendType" SG_ 2565865739 trailerABSstatus_BASIS 0;
BA_ "GenSigSendType" SG_ 2565865739 tractMountTrailerABSwarningSig_B 0;
BA_ "GenSigSendType" SG_ 2565865739 BPposition_BASIS 0;
BA_ "GenSigSendType" SG_ 2364539904 engineTorqueMode_BASIS 0;
BA_ "GenSigSendType" SG_ 2364539904 actualEnginePercentTorque_BASIS 0;
BA_ "GenSigSendType" SG_ 2364539904 engineSpeed_BASIS 0;
BA_ "GenSigSendType" SG_ 2364539904 actEngPerTorqHR_BASE 0;
BA_ "GenSigSendType" SG_ 2364539904 sourceAddressOfControllDevice_BA 0;
BA_ "GenSigSendType" SG_ 2364539904 engineStarterMode_MAN 0;
BA_ "GenSigSendType" SG_ 2364539904 engineDemandPercentTorque_BASIS 0;
BA_ "GenSigSendType" SG_ 2364539904 driverDemandEnginePercentTorque_ 0;
BA_ "GenSigSendType" SG_ 2565865487 retarderTorqueMode_RE 0;
BA_ "GenSigSendType" SG_ 2565865487 intendedRetarderPercentTorque_RE 0;
BA_ "GenSigSendType" SG_ 2565865487 sourceAddressOfControllDevice_RE 0;
BA_ "GenSigSendType" SG_ 2565865487 driversDemandRetarderPercTorque_ 0;
BA_ "GenSigSendType" SG_ 2565865487 actMaxAvailRetPercTorque_RE 0;
BA_ "GenSigSendType" SG_ 2565865487 actualRetarderPercentTorque_RE 0;
BA_ "GenSigSendType" SG_ 2633942787 neutralIndicator_BASIS 0;
BA_ "GenSigSendType" SG_ 2633942787 engagementIndicator_BASIS 0;
BA_ "GenSigSendType" SG_ 2633942787 rangeHighActuator_BASIS 0;
BA_ "GenSigSendType" SG_ 2633942787 rangeLowActuator_BASIS 0;
BA_ "GenSigSendType" SG_ 2633942787 splitterDirectActuator_BASIS 0;
BA_ "GenSigSendType" SG_ 2633942787 splitterIndirectActuator_BASIS 0;
BA_ "GenSigSendType" SG_ 2633942787 transmissionClutchActuator_BASIS 0;
BA_ "GenSigSendType" SG_ 2633942787 PTO1status_BASIS 0;
BA_ "GenSigSendType" SG_ 2633942787 PTO2status_BASIS 0;
BA_ "GenSigSendType" SG_ 2633942787 PTO3status_BASIS 0;
BA_ "GenSigSendType" SG_ 2633942787 rangeHighSelector_BASIS 0;
BA_ "GenSigSendType" SG_ 2633942787 rangeLowSelector_BASIS 0;
BA_ "GenSigSendType" SG_ 2633942787 splitterDirectSlowSelector_BASIS 0;
BA_ "GenSigSendType" SG_ 2633942787 splitterIndirectFastSelector_BAS 0;
BA_ "GenSigSendType" SG_ 2566799393 rotatingBeaconLight_BASE 0;
BA_ "GenSigSendType" SG_ 2566799393 rightTurnSignalLights_BASE 0;
BA_ "GenSigSendType" SG_ 2566799393 leftTurnSignalLights_BASE 0;
BA_ "GenSigSendType" SG_ 2566799393 centerStopLight_BASE 0;
BA_ "GenSigSendType" SG_ 2566799393 rightStopLight_BASE 0;
BA_ "GenSigSendType" SG_ 2566799393 leftStopLight_BASE 0;
BA_ "GenSigSendType" SG_ 2566799393 tractorMarkerLight_BASE 0;
BA_ "GenSigSendType" SG_ 2566799393 rearFogLights_BASE 0;
BA_ "GenSigSendType" SG_ 2566799393 lowBeamHeadLightData_BASE 0;
BA_ "GenSigSendType" SG_ 2566799393 highBeamHeadLightData_BASE 0;
BA_ "GenSigSendType" SG_ 2565867838 steeringWheelAngle_BASIS 0;
BA_ "GenSigSendType" SG_ 2565867838 steeringWheelTurnCounter_BASIS 0;
BA_ "GenSigSendType" SG_ 2565867838 steeringWheelAngleSensorType_BAS 0;
BA_ "GenSigSendType" SG_ 2565867838 yawRate_BASIS 0;
BA_ "GenSigSendType" SG_ 2565867838 lateralAcceleration_BASIS 0;
BA_ "GenSigSendType" SG_ 2565867838 longitudinalAcceleration_BASIS 0;
BA_ "GenSigSendType" SG_ 2600454443 vehDepartTimeMinutesDlyd_BASE 0;
BA_ "GenSigSendType" SG_ 2600454443 extnlChrgRemTime_VAR1 0;
BA_ "GenSigSendType" SG_ 2600454443 totalEnergyConsumption_BASE 0;
BA_ "GenSigSendType" SG_ 2600454443 vehDepartTimeDelayDlyd_BASE 0;
BA_ "GenSigSendType" SG_ 2566811434 speedOfForwardVehicle_BASIS 0;
BA_ "GenSigSendType" SG_ 2566811434 ACCsetSpeed_BASIS 0;
BA_ "GenSigSendType" SG_ 2566811434 ACCmode_BASIS 0;
BA_ "GenSigSendType" SG_ 2566811434 ACCsetDistanceMode_BASIS 0;
BA_ "GenSigSendType" SG_ 2566811434 roadCurvature_BASIS 0;
BA_ "GenSigSendType" SG_ 2566811434 ACCtargetDetected_BASIS 0;
BA_ "GenSigSendType" SG_ 2566811434 ACCsystemShutoffWarning_BASIS 0;
BA_ "GenSigSendType" SG_ 2566811434 ACCdistanceAlertSignal_BASIS 0;
BA_ "GenSigSendType" SG_ 2566811434 distanceToForwardVehicle_BASIS 0;
BA_ "GenSigSendType" SG_ 2566889767 AEBSactivationState_BASE 0;
BA_ "GenSigSendType" SG_ 2566889767 DPFlowLevelWarning_BASE 0;
BA_ "GenSigSendType" SG_ 2566889767 DPFmiddleLevelWarning_BASE 0;
BA_ "GenSigSendType" SG_ 2566889767 DPFactiveRegenerationManual_BASE 0;
BA_ "GenSigSendType" SG_ 2566889767 engDerateDueToUreaLevel_BASE 0;
BA_ "GenSigSendType" SG_ 2566889767 engDerateDueToUreaQuality_BASE 0;
BA_ "GenSigSendType" SG_ 2566889767 wrnDfctLDW_BASE 0;
BA_ "GenSigSendType" SG_ 2566889767 engDerateDueToUreaSystem_BASE 0;
BA_ "GenSigSendType" SG_ 2566889767 engDerateDueToATSystem_BASE 0;
BA_ "GenSigSendType" SG_ 2566889767 creepModeDueToUreaLevel_BASE 0;
BA_ "GenSigSendType" SG_ 2566889767 creepModeDueToUreaQuality_BASE 0;
BA_ "GenSigSendType" SG_ 2566889767 creepModeDueToUreaSystem_BASE 0;
BA_ "GenSigSendType" SG_ 2566889767 creepModeDueToATSystem_BASE 0;
BA_ "GenSigSendType" SG_ 2566889767 emgcyBrkState_BASE 0;
BA_ "GenSigSendType" SG_ 2566889767 antiJackknifeBrake_BASE 0;
BA_ "GenSigSendType" SG_ 2566889767 vehSpdLimWrn_BASE 0;
BA_ "GenSigSendType" SG_ 2566889767 wrnDfctEBA_BASE 0;
BA_ "GenSigSendType" SG_ 2566889767 PCCAenabled_BASE 0;
BA_ "GenSigSendType" SG_ 2566889767 PCCAecoDisp_BASE 0;
BA_ "GenSigSendType" SG_ 2566889767 dispMotionDataCnflct_BASE 0;
BA_ "GenSigSendType" SG_ 2566889767 LDWselected_BASE 0;
BA_ "GenSigSendType" SG_ 2566889767 dispMotionDataLimit_BASE 0;
BA_ "GenSigSendType" SG_ 2566889767 PCCAactiveDisp_BASE 0;
BA_ "GenSigSendType" SG_ 2566889767 brakeLightTailDfct_BASE 0;
BA_ "GenSigSendType" SG_ 2566889767 drvSysReadyToMove_BASE 0;
BA_ "GenSigSendType" SG_ 2566889767 exhaustHighTempLamp_BASE 0;
BA_ "GenSigSendType" SG_ 2566913831 modePCCA_BASE 0;
BA_ "GenSigSendType" SG_ 2566913831 spdIncPCCA_BASE 0;
BA_ "GenSigSendType" SG_ 2566913831 spdDecPCCA_BASE 0;
BA_ "GenSigSendType" SG_ 2583676659 BattPack1State_BASE 0;
BA_ "GenSigSendType" SG_ 2583676659 BattPack4State_BASE 0;
BA_ "GenSigSendType" SG_ 2583676659 BattPack5State_BASE 0;
BA_ "GenSigSendType" SG_ 2583676659 BattPack6State_BASE 0;
BA_ "GenSigSendType" SG_ 2583676659 BattPack7State_BASE 0;
BA_ "GenSigSendType" SG_ 2583676659 BattPackLast1State_BASE 0;
BA_ "GenSigSendType" SG_ 2583676659 BattPack9State_BASE 0;
BA_ "GenSigSendType" SG_ 2583676659 BattPack10State_BASE 0;
BA_ "GenSigSendType" SG_ 2583676659 BattPack2State_BASE 0;
BA_ "GenSigSendType" SG_ 2583676659 BattPack11State_BASE 0;
BA_ "GenSigSendType" SG_ 2583676659 BattPack12State_BASE 0;
BA_ "GenSigSendType" SG_ 2583676659 BattPack13State_BASE 0;
BA_ "GenSigSendType" SG_ 2583676659 BattPack14State_BASE 0;
BA_ "GenSigSendType" SG_ 2583676659 BattPack15State_BASE 0;
BA_ "GenSigSendType" SG_ 2583676659 BattPackLast2State_BASE 0;
BA_ "GenSigSendType" SG_ 2583676659 BattPack3State_BASE 0;
BA_ "GenSigSendType" SG_ 2583676403 battPackLast2TempSpreadMax_BASE 0;
BA_ "GenSigSendType" SG_ 2583676403 BattSysInterResistanceCh_BASE 0;
BA_ "GenSigSendType" SG_ 2583676403 BattSysInterResistanceDisch_BASE 0;
BA_ "GenSigSendType" SG_ 2583674611 BattPack1Temp_BASE 0;
BA_ "GenSigSendType" SG_ 2583674611 BattPack2Temp_BASE 0;
BA_ "GenSigSendType" SG_ 2583674611 BattPack3Temp_BASE 0;
BA_ "GenSigSendType" SG_ 2583674611 BattPack4Temp_BASE 0;
BA_ "GenSigSendType" SG_ 2583674867 BattPack5Temp_BASE 0;
BA_ "GenSigSendType" SG_ 2583674867 BattPack6Temp_BASE 0;
BA_ "GenSigSendType" SG_ 2583674867 BattPack7Temp_BASE 0;
BA_ "GenSigSendType" SG_ 2583674867 BattPackLast1Temp_BASE 0;
BA_ "GenSigSendType" SG_ 2583675123 BattPack9Temp_BASE 0;
BA_ "GenSigSendType" SG_ 2583675123 BattPack10Temp_BASE 0;
BA_ "GenSigSendType" SG_ 2583675123 BattPack11Temp_BASE 0;
BA_ "GenSigSendType" SG_ 2583675123 BattPack12Temp_BASE 0;
BA_ "GenSigSendType" SG_ 2583675379 BattPack13Temp_BASE 0;
BA_ "GenSigSendType" SG_ 2583675379 BattPack14Temp_BASE 0;
BA_ "GenSigSendType" SG_ 2583675379 BattPack15Temp_BASE 0;
BA_ "GenSigSendType" SG_ 2583675379 BattPackLast2Temp_BASE 0;
BA_ "GenSigSendType" SG_ 2566801959 transmissionMode1indicator_BASIS 0;
BA_ "GenSigSendType" SG_ 2583674355 BattSysTechSoc_BASE 0;
BA_ "GenSigSendType" SG_ 2583674355 BattSysVltgLimMax_BASE 0;
BA_ "GenSigSendType" SG_ 2583674355 BattSysDodSocMax_BASE 0;
BA_ "GenSigSendType" SG_ 2583674355 BattSysDodSocMin_BASE 0;
BA_ "GenSigSendType" SG_ 2583674355 BattSysIsoMeasResult_BASE 0;
BA_ "GenSigSendType" SG_ 2583674355 BattSysIsoMeasState_BASE 0;
BA_ "GenSigSendType" SG_ 2583639335 vehProfileLength_BASE 0;
BA_ "GenSigSendType" SG_ 2583639335 vehProfileWeightofAxle_BASE 0;
BA_ "GenSigSendType" SG_ 2583639335 vehProfileWeightofDblAxles_BASE 0;
BA_ "GenSigSendType" SG_ 2583639335 vehProfileHeight_BASE 0;
BA_ "GenSigSendType" SG_ 2583639335 vehProfileNumberOfAxles_BASE 0;
BA_ "GenSigSendType" SG_ 2583639335 vehProfileWidth_BASE 0;
BA_ "GenSigSendType" SG_ 2583639335 vehProfileTunnelCat_BASE 0;
BA_ "GenSigSendType" SG_ 2600403752 DCDCactPowerHV_BASE 0;
BA_ "GenSigSendType" SG_ 2600403752 sMeanPowerTES_BASE 0;
BA_ "GenSigSendType" SG_ 2600403752 BattSysTechSoc_BASE 0;
BA_ "GenSigSendType" SG_ 2600403752 axleLoadSum_BASIS 0;
BA_ "GenSigSendType" SG_ 2600403753 BattSysChCurrLimDyn_BASE 0;
BA_ "GenSigSendType" SG_ 2600403753 extrnlChrgImaxLim_BASE 0;
BA_ "GenSigSendType" SG_ 2600403753 extrnlChrgTargetCurrHR_BASE 0;
BA_ "GenSigSendType" SG_ 2600403753 extrnlChrgDCchrgngCurrent_BASE 0;
BA_ "GenSigSendType" SG_ 2562153767 hubVidInpUpdateTrigger_BASE 0;
BA_ "GenSigSendType" SG_ 2562153767 cameraHubTrigger3req_BASE 0;
BA_ "GenSigSendType" SG_ 2562153767 cameraHubTrigger2req_BASE 0;
BA_ "GenSigSendType" SG_ 2562153767 cameraHubTrigger4req_BASE 0;
BA_ "GenSigSendType" SG_ 2562153767 cameraHubTrigger1req_BASE 0;
BA_ "GenSigSendType" SG_ 2600407304 placeholderCuIntf15_BASE 0;
BA_ "GenSigSendType" SG_ 2600407309 placeholderCuIntf20_BASE 0;
BA_ "GenSigSendType" SG_ 2600407307 placeholderCuIntf18_BASE 0;
BA_ "GenSigSendType" SG_ 2600407308 placeholderCuIntf19_BASE 0;
BA_ "GenSigSendType" SG_ 2600407306 placeholderCuIntf17_BASE 0;
BA_ "GenSigSendType" SG_ 2600407305 placeholderCuIntf16_BASE 0;
BA_ "GenSigSendType" SG_ 2566575655 inletContactorState_BASE 0;
BA_ "GenSigSendType" SG_ 2566575655 EVSEconnectorLockState_BASE 0;
BA_ "GenSigSendType" SG_ 2365561639 BB_PlaceHolder_BASE 0;
BA_ "GenSigSendType" SG_ 2554986535 EVmcCabinCondFlag_BASE 0;
BA_ "GenSigSendType" SG_ 2554986535 EVmcRESScondFlag_BASE 0;
BA_ "GenSigSendType" SG_ 2163223335 crashType_BASE 0;
BA_ "GenSigSendType" SG_ 2163223335 CNcntE2E_BASE 0;
BA_ "GenSigSendType" SG_ 2163223335 CNchkE2E_BASE 0;
BA_ "GenSigSendType" SG_ 2600454422 PCCAinfrastructEnabled_BASE 3;
BA_ "GenSigSendType" SG_ 2600454422 brkLiningSlidingContact_BASE 3;
BA_ "GenSigSendType" SG_ 2600454422 EBSalive_BASE 3;
BA_ "GenSigSendType" SG_ 2600454422 PCCAdynamicRollEnabled_BASE 3;
BA_ "GenSigSendType" SG_ 2600454422 PCCAvarSpdLimiterEnabled_BASE 3;
BA_ "GenSigSendType" SG_ 2600454422 dispPCCAmapDataNotAvailable_BASE 3;
BA_ "GenSigSendType" SG_ 2600454422 dispPCCAreactInfrastruct_BASE 3;
BA_ "GenSigSendType" SG_ 2600454422 dispRecommVarSpdLimiter_BASE 3;
BA_ "GenSigSendType" SG_ 2600454422 monDiffLockWrng_BASE 3;
BA_ "GenSigSendType" SG_ 2600454422 dispAutoSpeedReduction_BASE 3;
BA_ "GenSigSendType" SG_ 2600454422 auxStatMC16cntE2E_BASE 3;
BA_ "GenSigSendType" SG_ 2600454422 auxStatMC16chkE2E_BASE 3;
BA_ "GenSigSendType" SG_ 2562086183 PCM6_CRC8_BASE 0;
BA_ "GenSigSendType" SG_ 2562086183 pbCan1button_BASE 0;
BA_ "GenSigSendType" SG_ 2562086183 pbCan2button_BASE 0;
BA_ "GenSigSendType" SG_ 2562086183 pbCan3button_BASE 0;
BA_ "GenSigSendType" SG_ 2562086183 pbCan4button_BASE 0;
BA_ "GenSigSendType" SG_ 2562086183 pbCan5button_BASE 0;
BA_ "GenSigSendType" SG_ 2562086183 pbCan6button_BASE 0;
BA_ "GenSigSendType" SG_ 2562086183 pbExteriorReq1BB_BASE 0;
BA_ "GenSigSendType" SG_ 2562086183 pbExteriorReq2BB_BASE 0;
BA_ "GenSigSendType" SG_ 2562086183 pbExteriorReq3BB_BASE 0;
BA_ "GenSigSendType" SG_ 2562086183 pbExteriorReq4BB_BASE 0;
BA_ "GenSigSendType" SG_ 2562086183 PCM6_cnt_BASE 0;
BA_ "GenSigSendType" SG_ 2566540583 totalTripEnergyConsumed_BASE 0;
BA_ "GenSigSendType" SG_ 2566540583 tripDriveEnergyEconomy_BASE 0;
BA_ "GenSigSendType" SG_ 2600403754 ActTransmOutputShaftTrq_BASE 0;
BA_ "GenSigSendType" SG_ 2600403754 DrivrDemTransOutputShftTrq_BASE 0;
BA_ "GenSigSendType" SG_ 2600403727 dispBatt24VDischrgMntsOTA_BASE 0;
BA_ "GenSigSendType" SG_ 2600403727 workinglightNotWork1_BASE 0;
BA_ "GenSigSendType" SG_ 2600403727 workinglightNotWork2_BASE 0;
BA_ "GenSigSendType" SG_ 2600403727 warningbeaconNotWork1_BASE 0;
BA_ "GenSigSendType" SG_ 2600403727 warningbeaconNotWork3_BASE 0;
BA_ "GenSigSendType" SG_ 2600403727 runUpPropInhibitRmtTstr_BASE 0;
BA_ "GenSigSendType" SG_ 2600403727 rmtTstrInstallStRcCalled_BASE 0;
BA_ "GenSigSendType" SG_ 2600403727 rmtTstrInstallState_BASE 0;
BA_ "GenSigSendType" SG_ 2600403727 placeHolder1cvm21_DUMMY 0;
BA_ "GenSigSendType" SG_ 2600403727 CVM21cntE2E_BASE 0;
BA_ "GenSigSendType" SG_ 2600403727 CVM21chkE2E_BASE 0;
BA_ "GenSigSendType" SG_ 2600403727 placeHolder2cvm21_DUMMY 0;
BA_ "GenSigSendType" SG_ 2365289866 msgCRC8saeJ1939_BASE 0;
BA_ "GenSigSendType" SG_ 2365289866 inverterReferenceTorque_BASE 0;
BA_ "GenSigSendType" SG_ 2365289866 inverterMotorRefSpeed_BASE 0;
BA_ "GenSigSendType" SG_ 2365289866 msgCNTsaeJ1939_BASE 0;
BA_ "GenSigSendType" SG_ 2565966730 msgCRC8saeJ1939_BASE 0;
BA_ "GenSigSendType" SG_ 2565966730 MG1availableMaxTorque_BASE 0;
BA_ "GenSigSendType" SG_ 2565966730 MG1availableMinTorque_BASE 0;
BA_ "GenSigSendType" SG_ 2565966730 msgCNTsaeJ1939_BASE 0;
BA_ "GenSigSendType" SG_ 2566889751 lightSensValue_BASE 0;
BA_ "GenSigSendType" SG_ 2566889751 hmiDashboardIllumiFocussed_BASE 0;
BA_ "GenSigSendType" SG_ 2566889751 hmiHeadlightAdjtmntFocussed_BASE 0;
BA_ "GenSigSendType" SG_ 2566889751 PCCAenableReq_BASE 0;
BA_ "GenSigSendType" SG_ 2566889751 reqSetRevAlert_BASE 0;
BA_ "GenSigSendType" SG_ 2566889751 ctrlSwStatusCluster_BASE 0;
BA_ "GenSigSendType" SG_ 2566889751 rollMaticEnableReq_BASE 0;
BA_ "GenSigSendType" SG_ 2566890263 daytimeRunninLightReq_BASE 0;
BA_ "GenSigSendType" SG_ 2566890263 backgroundLightAutoRevReq_BASE 0;
BA_ "GenSigSendType" SG_ 2566890263 bckgrndLghtDyNghtMdAutReq_BASE 0;
BA_ "GenSigSendType" SG_ 2566890263 uiFCWactivWrnReq_BASE 0;
BA_ "GenSigSendType" SG_ 2566890263 uiFCWactivActWrnReq_BASE 0;
BA_ "GenSigSendType" SG_ 2566890263 DPFrgnrtnReq_BASE 0;
BA_ "GenSigSendType" SG_ 2566890263 hmiWarningAGenabledReq_BASE 0;
BA_ "GenSigSendType" SG_ 2566890263 lccpaEnableReq_BASE 0;
BA_ "GenSigSendType" SG_ 2566890263 reqHmiSeatVbrtnLft_BASE 0;
BA_ "GenSigSendType" SG_ 2566890263 reqHmiSeatVbrtnRght_BASE 0;
BA_ "GenSigSendType" SG_ 2566890263 crpCtrlEnableReq_BASE 0;
BA_ "GenSigSendType" SG_ 2566890263 bckgrndLghtDyNghtMdManReq_BASE 0;
BA_ "GenSigSendType" SG_ 2566890263 interiorLightAutoCLreq_BASE 0;
BA_ "GenSigSendType" SG_ 2566890263 interiorLightAutoReq_BASE 0;
BA_ "GenSigSendType" SG_ 2566890263 lightWasherReq_BASE 0;
BA_ "GenSigSendType" SG_ 2566890263 comfModeSlct_BASE 0;
BA_ "GenSigSendType" SG_ 2566890263 showAxleLoadCntrlReq_BASE 0;
BA_ "GenSigSendType" SG_ 2566890263 reqLateralLaneAlignmentLKA_BASE 0;
BA_ "GenSigSendType" SG_ 2566890263 confirmReverseReq_BASE 0;
BA_ "GenSigSendType" SG_ 2566890263 entranceLightAutoReq_BASE 0;
BA_ "GenSigSendType" SG_ 2566890263 uiCntrlLockSpeedSelect_BASE 0;
BA_ "GenSigSendType" SG_ 2566890263 uiCntrlUnlockDoorSelect_BASE 0;
BA_ "GenSigSendType" SG_ 2566890263 uiDispAddDrvTimePreWarnReq_BASE 0;
BA_ "GenSigSendType" SG_ 2566890263 intBrkSwReq_BASE 0;
BA_ "GenSigSendType" SG_ 2566890263 brkmaticOffsetReq_BASE 0;
BA_ "GenSigSendType" SG_ 2566890519 resetTourReason1_BASE 0;
BA_ "GenSigSendType" SG_ 2566890519 lightTestWithLearnReq_BASE 0;
BA_ "GenSigSendType" SG_ 2566890519 lightTestWithoutLearnReq_BASE 0;
BA_ "GenSigSendType" SG_ 2566890519 resetTourReason2_BASE 0;
BA_ "GenSigSendType" SG_ 2566890519 PCCAinfrastructEnableReq_BASE 0;
BA_ "GenSigSendType" SG_ 2566890519 PCCAdynamicRollEnableReq_BASE 0;
BA_ "GenSigSendType" SG_ 2566890519 PCCAvarSpdLimiterEnableReq_BASE 0;
BA_ "GenSigSendType" SG_ 2566890519 revgPrhbtnSw_BASE 0;
BA_ "GenSigSendType" SG_ 2566890519 TJAenableReq_BASE 0;
BA_ "GenSigSendType" SG_ 2566890519 LGAenableReq_BASE 0;
BA_ "GenSigSendType" SG_ 2566890519 LDWenableReq_BASE 0;
BA_ "GenSigSendType" SG_ 2566890519 setTirePressAutoMode_BASE 0;
BA_ "GenSigSendType" SG_ 2566890519 instrWorkg_BASE 0;
BA_ "GenSigSendType" SG_ 2566890519 payloadReset_BASE 0;
BA_ "GenSigSendType" SG_ 2566890519 resetTourReason3_BASE 0;
BA_ "GenSigSendType" SG_ 2566890519 setTireSize_BASE 0;
BA_ "GenSigSendType" SG_ 2566890519 axleLocSetTireSize_BASE 0;
BA_ "GenSigSendType" SG_ 2566890519 auxStatInst4cntE2E_BASE 0;
BA_ "GenSigSendType" SG_ 2566890519 transferCaseCtrlNeutReq_BASE 0;
BA_ "GenSigSendType" SG_ 2566890519 auxStatInst4chkE2E_BASE 0;
BA_ "GenSigSendType" SG_ 2566890519 statusAcousticWrnSig_BASE 0;
BA_ "GenSigSendType" SG_ 2600454951 dispBatt24V_BASE 3;
BA_ "GenSigSendType" SG_ 2600454951 LCWselected_BASE 3;
BA_ "GenSigSendType" SG_ 2600454951 TCWselected_BASE 3;
BA_ "GenSigSendType" SG_ 2600454951 TCWLCWshowSelection_BASE 3;
BA_ "GenSigSendType" SG_ 2600454951 modeOptWrngSideLft_BASE 3;
BA_ "GenSigSendType" SG_ 2600454951 modeOptWrngSideRght_BASE 3;
BA_ "GenSigSendType" SG_ 2600454951 wrngSideSource_BASE 3;
BA_ "GenSigSendType" SG_ 2600454951 TCWLCWshowDeactWrng_BASE 3;
BA_ "GenSigSendType" SG_ 2600454951 lightWasherPump_BASE 3;
BA_ "GenSigSendType" SG_ 2600454424 dispHGBactiveState_BASE 3;
BA_ "GenSigSendType" SG_ 2600454424 tsiStateLEDreq_BASE 3;
BA_ "GenSigSendType" SG_ 2600454424 TSInotificationSound_BASE 3;
BA_ "GenSigSendType" SG_ 2600454424 TSIwrnSound_BASE 3;
BA_ "GenSigSendType" SG_ 2600454424 reqDispSafeStopEnd_BASE 3;
BA_ "GenSigSendType" SG_ 2600454424 reqDispSafeStopActive_BASE 3;
BA_ "GenSigSendType" SG_ 2600454424 dispCrpCtrlAbortPreWarn_BASE 3;
BA_ "GenSigSendType" SG_ 2600454424 dispCrpCtrlState_BASE 3;
BA_ "GenSigSendType" SG_ 2600454424 dispCrpCtrlActivationState_BASE 3;
BA_ "GenSigSendType" SG_ 2600454424 tsiChangeInfoSetting_BASE 3;
BA_ "GenSigSendType" SG_ 2600454424 tsiToleranceSetting_BASE 3;
BA_ "GenSigSendType" SG_ 2600454424 tsiEnableSpdWrn_BASE 3;
BA_ "GenSigSendType" SG_ 2600454424 dispHGBactiveStateAcoustic_BASE 3;
BA_ "GenSigSendType" SG_ 2600454424 tsiSelectedMode_BASE 3;
BA_ "GenSigSendType" SG_ 2600454424 dispFCWwarning_BASE 3;
BA_ "GenSigSendType" SG_ 2600454424 gearNotEfficient_BASE 3;
BA_ "GenSigSendType" SG_ 2600454424 highThermalLoadOnEngShtdwn_BASE 3;
BA_ "GenSigSendType" SG_ 2600454424 fcwUiMenuEnable_BASE 3;
BA_ "GenSigSendType" SG_ 2600454424 ISCroadSweeperActv_BASE 3;
BA_ "GenSigSendType" SG_ 2600454427 EBAselected_BASE 3;
BA_ "GenSigSendType" SG_ 2600454427 EBAsystemEngEnd_BASE 3;
BA_ "GenSigSendType" SG_ 2600454427 dispADASmenuReq_BASE 3;
BA_ "GenSigSendType" SG_ 2600454427 muteADASwrnReq_BASE 3;
BA_ "GenSigSendType" SG_ 2600454427 currMaxSpdPCCA_BASE 3;
BA_ "GenSigSendType" SG_ 2600454427 EBAselectedVRU_BASE 3;
BA_ "GenSigSendType" SG_ 2600454427 bremsomatAvailable_BASE 3;
BA_ "GenSigSendType" SG_ 2600454427 TAsysActivated_BASE 3;
BA_ "GenSigSendType" SG_ 2600454427 DVFRlateRevCAMmessage_BASE 3;
BA_ "GenSigSendType" SG_ 2600454427 ACC_FailureJ10_BASE 3;
BA_ "GenSigSendType" SG_ 2600454427 dispFrontVehicleAvailable_BASE 3;
BA_ "GenSigSendType" SG_ 2600454427 attentionGuardAvailable_BASE 3;
BA_ "GenSigSendType" SG_ 2600454427 hmiWarningAGenabled_BASE 3;
BA_ "GenSigSendType" SG_ 2600454427 dispDPFactvRgnrtnClngDwn_BASE 3;
BA_ "GenSigSendType" SG_ 2600454427 EBAsystemAvailableVEH_BASE 3;
BA_ "GenSigSendType" SG_ 2600454427 CCselectedMode_BASE 3;
BA_ "GenSigSendType" SG_ 2600454427 TSIuiMenuEnable_BASE 3;
BA_ "GenSigSendType" SG_ 2600454427 higherLvlCtrlRsp_BASE 3;
BA_ "GenSigSendType" SG_ 2600454427 reqDispLDWworking_BASE 3;
BA_ "GenSigSendType" SG_ 2600454427 reqDispLCCPAworking_BASE 3;
BA_ "GenSigSendType" SG_ 2600454427 reqDispTJAworking_BASE 3;
BA_ "GenSigSendType" SG_ 2600454427 reqDispLGAworking_BASE 3;
BA_ "GenSigSendType" SG_ 2600454427 ldwSysState_VAR1 3;
BA_ "GenSigSendType" SG_ 2600454427 EBAsystemAvailableVRU_BASE 3;
BA_ "GenSigSendType" SG_ 2600454427 EBAdispNoSelectPossibleVRU_BASE 3;
BA_ "GenSigSendType" SG_ 2600454428 dispVASCmenuReq_BASE 3;
BA_ "GenSigSendType" SG_ 2600454428 levelLearnTrlStatusSpdLvl_BASE 3;
BA_ "GenSigSendType" SG_ 2600454428 spdDpndntLvlCtrlStatus_BASE 3;
BA_ "GenSigSendType" SG_ 2600454428 liftAxleAutoStatus_BASE 3;
BA_ "GenSigSendType" SG_ 2600454428 relieveAxleNotPossible_BASE 3;
BA_ "GenSigSendType" SG_ 2600454428 nomLvlNotSet_BASE 3;
BA_ "GenSigSendType" SG_ 2600454428 lvlCtrlNotPossible_BASE 3;
BA_ "GenSigSendType" SG_ 2600454428 liftAxleNotPossible_BASE 3;
BA_ "GenSigSendType" SG_ 2600454428 spdDpndntLvlCtrlRsp_BASE 3;
BA_ "GenSigSendType" SG_ 2600454428 trctnHlpTrlRefusal_BASE 3;
BA_ "GenSigSendType" SG_ 2600454428 kneelingOff_BASE 3;
BA_ "GenSigSendType" SG_ 2600454428 VASCerrorActive_BASE 3;
BA_ "GenSigSendType" SG_ 2600454428 kneelingNotPossible_BASE 3;
BA_ "GenSigSendType" SG_ 2600454428 kneelgPrslctAutoState_BASE 3;
BA_ "GenSigSendType" SG_ 2600454428 belowFAminSteeringLoad_BASE 3;
BA_ "GenSigSendType" SG_ 2600454428 lccpaSelected_BASE 3;
BA_ "GenSigSendType" SG_ 2600454428 trctnHlpNotPossible_BASE 3;
BA_ "GenSigSendType" SG_ 2600454428 lateralLaneAlignmentLKA_BASE 3;
BA_ "GenSigSendType" SG_ 2600454428 FCWacuteWarningSelected_BASE 3;
BA_ "GenSigSendType" SG_ 2600454428 FCWwarningSelected_BASE 3;
BA_ "GenSigSendType" SG_ 2600454428 distanceGuardCollWrn_BASE 3;
BA_ "GenSigSendType" SG_ 2600454428 levelLearnTrlStatusNL2_BASE 3;
BA_ "GenSigSendType" SG_ 2600454428 distanceWarning_BASE 3;
BA_ "GenSigSendType" SG_ 2600454428 levelLearnTrlStatus_BASE 3;
BA_ "GenSigSendType" SG_ 2566891303 ASRactvRsp_BASE 3;
BA_ "GenSigSendType" SG_ 2566891303 curBrkmaticMode_BASE 3;
BA_ "GenSigSendType" SG_ 2566891303 curBrkmaticSpeedAbs_BASE 3;
BA_ "GenSigSendType" SG_ 2600403717 transShiftingServoHSpdf_BASE 3;
BA_ "GenSigSendType" SG_ 2600403717 transShiftingServoLS_BASE 3;
BA_ "GenSigSendType" SG_ 2600403717 PTO1HS_BASE 3;
BA_ "GenSigSendType" SG_ 2600403717 PTO2HS_BASE 3;
BA_ "GenSigSendType" SG_ 2600403717 PTO3HS_BASE 3;
BA_ "GenSigSendType" SG_ 2600403717 PTO3userReqResp_BASE 3;
BA_ "GenSigSendType" SG_ 2600403717 signalHorn_BASE 3;
BA_ "GenSigSendType" SG_ 2600403717 signalHornValveOn_BASE 3;
BA_ "GenSigSendType" SG_ 2600403717 CAVIcomReq_BASE 3;
BA_ "GenSigSendType" SG_ 2600403717 elecSteerBackupNotAvail_BASE 3;
BA_ "GenSigSendType" SG_ 2600403717 LDWselectedCB_BASE 3;
BA_ "GenSigSendType" SG_ 2600403717 LGAselected_BASE 3;
BA_ "GenSigSendType" SG_ 2600403717 LKAselected_BASE 3;
BA_ "GenSigSendType" SG_ 2600403717 reqDispCtrlSteeringWheel_BASE 3;
BA_ "GenSigSendType" SG_ 2600403717 reqDispHandsOff1_BASE 3;
BA_ "GenSigSendType" SG_ 2600403717 reqDispHandsOff2_BASE 3;
BA_ "GenSigSendType" SG_ 2600403717 reqDispHandsOff3_BASE 3;
BA_ "GenSigSendType" SG_ 2600403717 reqDispLGAactive_BASE 3;
BA_ "GenSigSendType" SG_ 2600403717 reqDispLGAdeactTemp_BASE 3;
BA_ "GenSigSendType" SG_ 2600403717 reqDispLGAmodeActive_BASE 3;
BA_ "GenSigSendType" SG_ 2600403717 slowVoltDecrDtctd_BASE 3;
BA_ "GenSigSendType" SG_ 2600403717 CVM05cntE2E_BASE 3;
BA_ "GenSigSendType" SG_ 2600403717 CVM05chkE2E_BASE 3;
BA_ "GenSigSendType" SG_ 2566890279 dispDPFregProgress_BASE 3;
BA_ "GenSigSendType" SG_ 2566890279 LDWdispNoActvnReqPossible_BASE 3;
BA_ "GenSigSendType" SG_ 2566890279 lvlOutOfRgRsp_BASE 3;
BA_ "GenSigSendType" SG_ 2566890279 drvSwitchNeutralReq_BASE 3;
BA_ "GenSigSendType" SG_ 2566890279 airFilterClogged_BASE 3;
BA_ "GenSigSendType" SG_ 2566890279 fuelLvlWarning_BASE 3;
BA_ "GenSigSendType" SG_ 2566890279 condFuelPrefilterHtngFail_BASE 3;
BA_ "GenSigSendType" SG_ 2566890279 washerFluidLvlLow_BASE 3;
BA_ "GenSigSendType" SG_ 2566890279 displayAntiTheftWarning2_BASE 3;
BA_ "GenSigSendType" SG_ 2566890279 displayAntiTheftWarning_BASE 3;
BA_ "GenSigSendType" SG_ 2566890279 dispWarningCoolantLvl_BASE 3;
BA_ "GenSigSendType" SG_ 2566890279 deactInfrFGRwarn_BASE 3;
BA_ "GenSigSendType" SG_ 2566890279 engineStarterMode_MAN 3;
BA_ "GenSigSendType" SG_ 2566890279 DPFRgnDrvSysActvReq_BASE 3;
BA_ "GenSigSendType" SG_ 2566890279 DPFRgnClutchReleaseReq_BASE 3;
BA_ "GenSigSendType" SG_ 2566890279 DPFRgnReleasePTOreq_BASE 3;
BA_ "GenSigSendType" SG_ 2566890279 DPFrgnrtnProhReleaseReq_BASE 3;
BA_ "GenSigSendType" SG_ 2566890279 DPFRgnVehStandStillReq_BASE 3;
BA_ "GenSigSendType" SG_ 2566890279 DPFRgnWarmUpEngReq_BASE 3;
BA_ "GenSigSendType" SG_ 2566890279 DPFRgnNeutrGearReq_BASE 3;
BA_ "GenSigSendType" SG_ 2566890279 DPFRgnParkBrkActvReq_BASE 3;
BA_ "GenSigSendType" SG_ 2566890279 DPFrgnReleaseAPreq_BASE 3;
BA_ "GenSigSendType" SG_ 2566890279 DPFrgnReleaseBPReq_BASE 3;
BA_ "GenSigSendType" SG_ 2566890279 auxStatMC3cntE2E_BASE 3;
BA_ "GenSigSendType" SG_ 2566890279 auxStatMC3chkE2E_BASE 3;
BA_ "GenSigSendType" SG_ 2566890279 EBAdispNoSelectionPossible_BASE 3;
BA_ "GenSigSendType" SG_ 2566818954 auxiliaryTemperature1_BASIS 0;
BA_ "GenSigSendType" SG_ 2566818954 auxiliaryPressure1_BASIS 0;
BA_ "GenSigSendType" SG_ 2566818954 auxiliaryPressure2_BASIS 0;
BA_ "GenSigSendType" SG_ 2566818954 auxiliaryLevel_BASIS 0;
BA_ "GenSigSendType" SG_ 2566818954 airHumidity_BASIS 0;
BA_ "GenSigSendType" SG_ 2566818954 auxiliaryTemperature3_BASIS 0;
BA_ "GenSigSendType" SG_ 2566818954 auxiliaryTemperature2_BASIS 0;
BA_ "GenSigSendType" SG_ 2566743552 engineCoolantTemperature2_BASE 0;
BA_ "GenSigSendType" SG_ 2364637578 msgCRC8saeJ1939_BASE 0;
BA_ "GenSigSendType" SG_ 2364637578 MG1InvCtrlLmtsOvrrdeMd_BASE 0;
BA_ "GenSigSendType" SG_ 2364637578 MGIMF1setpointMode_BASE 0;
BA_ "GenSigSendType" SG_ 2364637578 msgCNTsaeJ1939_BASE 0;
BA_ "GenSigSendType" SG_ 2600460802 currSelectMenuID_BASE 0;
BA_ "GenSigSendType" SG_ 2583662700 batt24VchargeOutptAccmlt_B_BASE 0;
BA_ "GenSigSendType" SG_ 2583662700 batt24VchargeInputAccmlt_B_BASE 0;
BA_ "GenSigSendType" SG_ 2583662741 batt24VchargeOutputAccmlt_A_BASE 0;
BA_ "GenSigSendType" SG_ 2583662741 batt24VchargeInputAccmlt_A_BASE 0;
BA_ "GenSigSendType" SG_ 2566865516 BDM1_CRC_BASE 0;
BA_ "GenSigSendType" SG_ 2566865516 UactBatt24V_B_BASE 0;
BA_ "GenSigSendType" SG_ 2566865516 UactBatt12V_B_BASE 0;
BA_ "GenSigSendType" SG_ 2566865516 IactBatt24V_B_BASE 0;
BA_ "GenSigSendType" SG_ 2566865516 BDM1_Cnt_BASE 0;
BA_ "GenSigSendType" SG_ 2566865557 BDM1_CRC_BASE 0;
BA_ "GenSigSendType" SG_ 2566865557 UactBatt24V_A_BASE 0;
BA_ "GenSigSendType" SG_ 2566865557 UactBatt12V_A_BASE 0;
BA_ "GenSigSendType" SG_ 2566865557 IactBatt24V_A_BASE 0;
BA_ "GenSigSendType" SG_ 2566865557 BDM1_Cnt_BASE 0;
BA_ "GenSigSendType" SG_ 2564822823 requestedPercentFanSpd_BASE 0;
BA_ "GenSigSendType" SG_ 2564822823 seatBeltSwitch_BASE 0;
BA_ "GenSigSendType" SG_ 2564822823 DPFregenerationInhibitSw_BASE 0;
BA_ "GenSigSendType" SG_ 2564822823 DPFregenerationForceSw_BASE 0;
VAL_ 2600462617 stHeatPump2_BASE 0 "off" 1 "active" 2 "closed" 3 "failure" 14 "error" 15 "not available";
VAL_ 2600462617 actModeHVAC1_BASE 0 "ventilation mode" 1 "heating mode" 2 "air conditioning mode" 14 "error" 15 "not available";
VAL_ 2600462617 actModeHVAC2_BASE 0 "ventilation mode" 1 "heating mode" 2 "air conditioning mode" 14 "error" 15 "not available";
VAL_ 2600462617 stElHeat_BASE 0 "off" 1 "active" 2 "closed" 3 "failure" 14 "error" 15 "not available";
VAL_ 2600462617 stElHeatMux_BASE 0 "electric heater 1" 1 "electric heater 2" 2 "electric heater 3" 3 "electric heater 4" 4 "electric heater 5" 14 "error" 15 "not available";
VAL_ 2600462617 stCombHeat_BASE 0 "off" 1 "active" 2 "closed" 3 "failure" 14 "error" 15 "not available";
VAL_ 2600462617 predModePreCondHVAC1_BASE 0 "ventilation mode" 1 "heating mode" 2 "air conditioning mode" 14 "error" 15 "not available";
VAL_ 2600462617 predModePreCondHVAC2_BASE 0 "ventilation mode" 1 "heating mode" 2 "air conditioning mode" 14 "error" 15 "not available";
VAL_ 2600462617 statePreCondPrepHVAC_BASE 0 "preCond not released" 1 "preCond released" 2 "error" 3 "not available";
VAL_ 2600462617 stHeatPump1_BASE 0 "off" 1 "active" 2 "closed" 3 "failure" 14 "error" 15 "not available";
VAL_ 2566844672 parkingBrakeSwitch_BASIS 0 "Parking brake not set" 1 "Parking brake set" 2 "Error" 3 "Not available";
VAL_ 2566844672 CCactive_BASIS 0 "Cruise control switched off" 1 "Cruise control switched on" 2 "error" 3 "not available / not installed";
VAL_ 2566844672 CCenableSwitch_BASIS 0 "Cruise control disable" 1 "Cruise control enable" 2 "Error" 3 "Not available";
VAL_ 2566844672 brakeSwitch_BASIS 0 "Brake pedal released" 1 "Brake pedal depressed" 2 "Error" 3 "Not available";
VAL_ 2566844672 clutchSwitch_BASIS 0 "Clutch pedal released" 1 "Clutch pedal depressed" 2 "Error" 3 "Not available";
VAL_ 2566844672 CCswitchStatus_BASIS 0 "neutral" 1 "Aus" 4 "Set-" 16 "Wiederaufnahme" 64 "Set+" 170 "Defekt";
VAL_ 2566844672 speedLimitEnableSwitch_BASIS 0 "off" 1 "on" 2 "error" 3 "not available";
VAL_ 2566844672 PTOgovernorState_BASE 0 "Off/Disabled" 1 "Hold" 2 "Remote Hold" 3 "Standby" 4 "Remote Standby" 5 "Set" 6 "Decelerate/Coast" 7 "Resume" 8 "Accelerate" 9 "Accelerator Override" 10 "Preprogrammed set speed 1" 11 "Preprogrammed set speed 2" 12 "Preprogrammed set speed 3" 13 "Preprogrammed set speed 4" 14 "Preprogrammed set speed 5" 15 "Preprogrammed set speed 6" 16 "Preprogrammed set speed 7" 17 "Preprogrammed set speed 8" 18 "PTO set speed memory 1" 19 "PTO set speed memory 2" 31 "Not available";
VAL_ 2566844672 CCstates_BASIS 0 "OFF_Disabled" 1 "Hold" 2 "Accelerate" 3 "Decelerate_Coast" 4 "Resume" 5 "Set" 6 "Accelerate override" 7 "not available";
VAL_ 2566844672 intelligentBrakingSwitch_BASIS 0 "intelligent coupling deactivated" 1 "intelligent coupling activated" 2 "Error" 3 "Not available";
VAL_ 2566844672 FGR_ACCswitch_BASIS 0 "schalter nicht betätigt" 1 "schalter betätigt" 2 "error" 3 "not available";
VAL_ 2365479471 nominalLevelFrontAxle_BASIS 0 "level not specified,(i.e. the nominal level is none of the specified levels, no" 1 "Normal Level 1,(i.e. the level prescribed for normal driving, given by design)" 2 "Normal Level 2,(i.e. a level permitted for driving, for example to lower the vehicle in case of high speed)" 3 "Normal Level 3,(i.e. a level permitted for driving, for example to lift the vehicle in case of offroad)" 4 "Preset Level,(i.e. a level to be defined externally via CAN)" 5 "Customer Level,(i.e. a level to be defined by customer via parameter setting)" 6 "Upper Level,(i.e. the highest level to be controlled)" 7 "Lower Level,(i.e. the lowest level to be controlled)" 8 "Level change stopped" 9 "Raising" 10 "Lowering" 11 "1011-1101 Reserved" 14 "error" 15 "not available";
VAL_ 2365479471 belowNominalLevelRearAxle_BASIS 0 "not below" 1 "below" 2 "error" 3 "not available";
VAL_ 2365479471 aboveNominalLevelFrontAxle_BASIS 0 "not above" 1 "above" 2 "error" 3 "not available";
VAL_ 2365479471 aboveNominalLevelRearAxle_BASIS 0 "not above" 1 "above" 2 "error" 3 "not available";
VAL_ 2365479471 loweringControlModeFrontAxle_BAS 0 "lowering not active" 1 "lowering active" 2 "error" 3 "not available";
VAL_ 2365479471 loweringControlModeRearAxle_BASI 0 "lowering not active" 1 "lowering active" 2 "error state lowering not possible" 3 "not available";
VAL_ 2365479471 liftingControlModeFrontAxle_BASI 0 "lifting not active" 1 "lifting active" 2 "error state" 3 "not available";
VAL_ 2365479471 liftingControlModeRearAxle_BASIS 0 "lifting not active" 1 "lifting active" 2 "error state" 3 "not available";
VAL_ 2365479471 kneelingInformation_BASIS 0 "not active,(i.e. the kneeling function is not active)" 1 "Lowering active,(i.e. the vehicle is lowered due to a kneeling request)" 2 "Kneeling level reached,(i.e. the vehicle is at the fixed kneeling level)" 3 "Lifting active,(i.e. the vehicle is lifted due to a recover request)" 4 "Kneeling aborted,(i.e. in case of manual actuation the request was dropped before the kneeling level was reached)" 5 "0101-1101 not defined" 14 "error" 15 "not available";
VAL_ 2365479471 levelControlMode_BASIS 0 "Normal operation; i.e. the system performs a pure control of the vehicle hei" 1 "Traction help (load transfer); i.e. the driven axle is loaded to a maximum value given by legislation or design" 2 "Load fixing; i.e. the driven axlen is loaded to a value defined by the driver" 3 "Pressure ratio 1; i.e. the ratio between the pressures at the driven axle and at the third axle is controlled, so that the ratio equals a fixed value 1" 4 "Pressure ratio 2; i.e. the ratio between the pressures at the driven axle and at the third axle is controlled, so that the ratio equals a fixed value 2" 5 "Optimum traction 1; i.e. the pressure at the driven axle is controlled at a fixed value 1" 6 "Optimum traction 2; i.e. the pressure at the driven axle is controlled at a fixed value 2" 7 "Traction help - load reduce; (i.e. the driven axle load is reduced to normal load condition)" 8 "Exhausting bellow function; i.e. the bellows are exhausted totally" 9 "Air suspension control prohibited (i.e. hold current pressures in all suspension devices)" 10 "Automatic air suspension control prohibited" 11 "Forced bumper level (i.e. anti tilt function)" 12 "not defined" 13 "not defined" 14 "error" 15 "not available";
VAL_ 2365479471 securityDevice_BASIS 0 "passive" 1 "active" 2 "error" 3 "not available";
VAL_ 2365479471 vehicleMotionInhibit_BASIS 0 "vehicle may be moved" 1 "vehicle motion is inhibited" 2 "error" 3 "not available";
VAL_ 2365479471 doorRelease_BASIS 0 "doors may not be opened" 1 "doors may be opened" 2 "error" 3 "not available";
VAL_ 2365479471 liftAxle1position_BASIS 0 "lift axle position down, tag axle laden" 1 "lift axle position up" 2 "error" 3 "not available";
VAL_ 2365479471 nominalLevelRearAxle_BASIS 0 "level not specified,(i.e. the nominal level is none of the specified levels, no" 1 "Normal Level 1,(i.e. the level prescribed for normal driving, given by design)" 2 "Normal Level 2,(i.e. a level permitted for driving, for example to lower the vehicle in case of high speed)" 3 "Normal Level 3,(i.e. a level permitted for driving, for example to lift the vehicle in case of offroad)" 4 "Preset Level,(i.e. a level to be defined externally via CAN)" 5 "Customer Level,(i.e. a level to be defined by customer via parameter setting)" 6 "Upper Level,(i.e. the highest level to be controlled)" 7 "Lower Level,(i.e. the lowest level to be controlled)" 8 "Level change stopped" 9 "Raising" 10 "Lowering" 11 "1011-1101 Reserved" 14 "error" 15 "not available";
VAL_ 2365479471 frontAxleBumperRange_BASIS 0 "actual level above bumper range" 1 "actual level within bumper range" 2 "error" 3 "not available";
VAL_ 2365479471 rearAxleBumperRange_BASIS 0 "actual level out of bumper range" 1 "actual level within bumper range" 2 "error" 3 "not available";
VAL_ 2365479471 liftAxle2position_BASIS 0 "lift axle position down, tag axle laden" 1 "lift axle position up/tag axle unladen" 2 "error" 3 "not available";
VAL_ 2365479471 suspensionRemoteControl1_BASIS 0 "not active" 1 "active" 2 "error" 3 "not available";
VAL_ 2365479471 suspensionRemoteControl2_BASIS 0 "not active" 1 "active" 2 "error" 3 "not available";
VAL_ 2365479471 allowLvlCtrlDuringBrakingStatus_ 0 "Deactivate" 1 "Activate" 2 "Reserved" 3 "Dont care/take no action";
VAL_ 2365479471 speedDependantLevelControlStatus 0 "Inactive" 1 "Active" 2 "Reserved" 3 "Dont care/take no action";
VAL_ 2365479471 suspensionControlRefusalInfo_BAS 0 "actual request not refused" 1 "Axle load limit reached (load transfer)" 2 "Would exceed axle load limit (tag axle)" 3 "Bogie differential not locked" 4 "Above speed limit" 5 "Below speed limit" 6 "general reject i.e. no specified reason applies" 7 "0111-1101 not defined" 14 "error" 15 "not available";
VAL_ 2365479471 belowNominalLevelFrontAxle_BASIS 0 "not below" 1 "below" 2 "error" 3 "not available";
VAL_ 2364539648 AP1lowIdleSwitch_BASIS 0 "AP 1 not in low idle condition" 1 "AP 1  in low idle condition" 2 "Error" 3 "Not available";
VAL_ 2364539648 APkickdownSwitch_BASIS 0 "Kickdown passive" 1 "Kickdown active" 2 "Error" 3 "Not available";
VAL_ 2364539648 roadSpeedLimitStatus_BASIS 0 "active" 1 "not active" 2 "error" 3 "not available";
VAL_ 2600403746 HVACactMode_BASE 0 "Normal mode" 1 "Eco mode" 2 "Boost mode" 3 "Silent mode" 4 "Waste Energy mode" 5 "Shutdown mode" 6 "Off mode" 14 "error" 15 "not available";
VAL_ 2600403746 AMSactMode_BASE 0 "Normal mode" 1 "Eco mode" 2 "Boost mode" 3 "Silent mode" 4 "Waste Energy mode" 5 "Shutdown mode" 6 "Off mode" 7 "Failure mode" 14 "error" 15 "not available";
VAL_ 2600403746 CHSactMode_BASE 0 "Normal mode" 1 "Eco mode" 2 "Boost mode" 3 "Silent mode" 4 "Waste Energy mode" 5 "Shutdown mode" 6 "Off mode" 7 "Failure mode" 14 "error" 15 "not available";
VAL_ 2600403746 ePTOactMode_BASE 0 "Normal mode" 1 "Eco mode" 2 "Boost mode" 3 "Silent mode" 4 "Waste Energy mode" 5 "Shutdown mode" 6 "Off mode" 7 "Failure mode" 14 "error" 15 "not available";
VAL_ 2566889761 tuerkontaktLinks_BASIS 0 "Tuerkontakt geöffnet" 1 "Tuerkontakt geschlossen" 2 "Fehler" 3 "Signal nicht verfügbar";
VAL_ 2566889761 fahrerhausVerriegelung_BASIS 0 "Fahrerhaus verriegelt" 1 "Fahrerhaus nicht verriegelt" 2 "Fehler" 3 "Signal nicht verfügbar";
VAL_ 2566889761 haengerABSerkennung_BASIS 0 "Trailer with ABS-functionality recognized" 1 "Trailer without ABS-functionality recognized" 2 "Error" 3 "NotAvailable (no trailer recognized)";
VAL_ 2566889761 flammstartAktiv_BASIS 0 "Flammstart nicht aktive" 1 "Flammstart  aktive" 3 "Signal nicht verfügbar";
VAL_ 2566889761 fernlichtEinRueckmeldung_BASIS 0 "Fernlicht aus" 1 "Fernlicht ein" 2 "Fehler Fernlicht rechts oder links" 3 "Signal nicht verfügbar";
VAL_ 2566889761 tuerkontaktRechts_BASIS 0 "Tuerkontakt geöffnet" 1 "Tuerkontakt geschlossen" 2 "Fehler" 3 "Signal nicht verfügbar";
VAL_ 2566889761 schalterFahrniveau1oder2senken_B 0 "00-10 aus Byte4,Bit 1,2;aus auxstatInst1" 3 "falls auxstatInst1 nicht gesendet wird";
VAL_ 2566889761 hybTripReset_BASE 0 "reset passive" 1 "reset active" 2 "error" 3 "not available";
VAL_ 2566889761 instrFunktionsfaehig_BASIS 0 "instrumentation not working / timeout / no signal" 1 "instrumentation working" 2 "error" 3 "not available";
VAL_ 2566889761 kraftstoffuellstandZuNiedrig_BAS 0 "Tankinhalt in Ordnung" 1 "Tankinhalt unter Minimum";
VAL_ 2566889761 schalterBlinkerRechtsRueckm_BASI 0 "switch open" 1 "switch closed" 2 "error" 3 "not available";
VAL_ 2566889761 schalterBlinkerLinksRueckm_BASIS 0 "switch open" 1 "switch closed" 2 "error" 3 "not available";
VAL_ 2566889761 lichttestAktivRueckmeldung_BASIS 0 "response light check control not active" 1 "response light check control active" 2 "error" 3 "not available";
VAL_ 2566889761 kontrVersorgAnhaengerABS_BASIS 0 "trailer ABS present and no errors" 1 "indicator lamp trailer ABS set" 2 "error (trailer ABS short to Ubatt)" 3 "not available (no trailer detected or trailer without ABS detected)";
VAL_ 2566889761 highBeamOutpState_BASE 0 "off" 1 "on";
VAL_ 2566889761 beleuchtungHaenger1erkannt_BASIS 0 "kein Hänger erkannt" 1 "Hänger erkannt" 2 "error" 3 "not available";
VAL_ 2566889761 fahrlichtEinRueckmeldung_BASIS 0 "Fahrlicht aus" 1 "Fahrlicht ein" 2 "Fehler Abblendlicht links oder rechts" 3 "Signal nicht verfügbar";
VAL_ 2566889761 rueckwaertsgangEingelegt_BASIS 0 "gear > = 0(>=125) und gültig" 1 "gear < 0 (<125) und gültig" 2 "gear = 254" 3 "sonst";
VAL_ 2566889761 infoNotaus_BASIS 0 "no emergency shut off" 1 "emergency shut off activated" 2 "error" 3 "notavailable";
VAL_ 2565865739 ASRengineControlActPass_BASIS 0 "ASR engine control passive, but installed" 1 "ASR engine control active" 2 "reserved" 3 "not available";
VAL_ 2565865739 ABSoffroadSwitch_BASIS 0 "passive" 1 "active" 2 "error indicator" 3 "not available";
VAL_ 2565865739 ASRoffroadSwitch_BASIS 0 "ASR off-road switch passive" 1 "ASR off-road switch active" 2 "error indicator" 3 "not available";
VAL_ 2565865739 ASRbrakeControlActPass_BASIS 0 "ASR brake control passive, but installed" 1 "ASR brake control active" 2 "reserved" 3 "not available";
VAL_ 2565865739 ASRhillHolderSwitch_BASIS 0 "ASR hill holder switch passive" 1 "ASR hill holder switch active" 2 "Error" 3 "not available";
VAL_ 2565865739 tractionControlOverrideSwitch_BA 0 "Off" 1 "On" 2 "reserved" 3 "not available or not installed";
VAL_ 2565865739 acceleratorInterlockSwitch_BASIS 0 "off" 1 "on" 2 "error" 3 "not available";
VAL_ 2565865739 engineDerateSwitch_BASIS 0 "off" 1 "on" 2 "error" 3 "not available";
VAL_ 2565865739 engineAuxiliaryShutdownSwitch_BA 0 "off" 1 "on" 2 "error" 3 "not available";
VAL_ 2565865739 remoteAcceleratorEnableSwitch_BA 0 "Off" 1 "On" 2 "reserved" 3 "take no action";
VAL_ 2565865739 ABSactive_BASIS 0 "ABS passive but installed" 1 "ABS active" 2 "Reserved" 3 "Don´t care";
VAL_ 2565865739 ABSfullyOperational_BASIS 0 "Not Fully Operaional" 1 "Fully Operational" 2 "Reserved" 3 "Take No Action";
VAL_ 2565865739 EBSredWarningSignal_BASIS 0 "Off" 1 "On" 2 "reserved" 3 "take no action";
VAL_ 2565865739 ABS_EBSamberWarningSignal_BASIS 0 "off" 1 "on" 2 "reserved" 3 "take no action";
VAL_ 2565865739 ATC_ASRinformationSignal_BASIS 0 "off" 1 "on" 2 "reserved" 3 "take no action";
VAL_ 2565865739 haltBrakeSwitch_BASIS 0 "halt brake switch passive" 1 "halt brake switch active" 2 "error" 3 "not available";
VAL_ 2565865739 EBSbrakeSwitch_BASIS 0 "Brake pedal is not being pressed" 1 "Brake pedal is being pressed" 2 "error" 3 "not available";
VAL_ 2565865739 trailerABSstatus_BASIS 0 "trailer ABS status info available but not active" 1 "trailer ABS active" 2 "reserved" 3 "trailer ABS status info not available or parameter not supported";
VAL_ 2565865739 tractMountTrailerABSwarningSig_B 0 "Off" 1 "On" 2 "reserved" 3 "take no action";
VAL_ 2364539904 engineTorqueMode_BASIS 0 "Low idle governor _ no request" 1 "Acelerator pedal _ operation selector" 2 "Cruise control" 3 "PTO governor" 4 "Road speed governor" 5 "ASR Control" 6 "Transmission Control" 7 "ABS Control" 8 "Torque limiting" 9 "High speed governor" 10 "Braking System" 11 "Remote Accelerator" 12 "Service Procedure" 13 "not defined" 14 "Other" 15 "not available";
VAL_ 2364539904 engineStarterMode_MAN 0 "no start (no request)" 1 "start active" 2 "start finished" 3 "no start (due to engine reasons)" 4 "no start (due to vehicle reasons)" 5 "no start (because of active immobilizer)" 6 "no start (due to starter reasons)" 14 "error" 15 "not available";
VAL_ 2565865487 retarderTorqueMode_RE 0 "Low idle governor/ no request(default mode)" 1 "Acelator pedal/operator selection" 2 "cruise control" 3 "PTO governor" 4 "Road Speed Governor" 5 "ASR Control" 6 "Transmission Control" 7 "ABS Control" 8 "Torque Limiting" 9 "High Speed Governor" 10 "Braking System" 11 "Remote Accelerator" 12 "Service Procedure" 13 "not defined" 14 "other" 15 "not available";
VAL_ 2633942787 neutralIndicator_BASIS 0 "Off" 1 "On" 2 "Error" 3 "Not available";
VAL_ 2633942787 engagementIndicator_BASIS 0 "Off" 1 "On" 2 "Error" 3 "Not available";
VAL_ 2633942787 rangeHighActuator_BASIS 0 "off" 1 "on" 2 "error" 3 "not available";
VAL_ 2633942787 rangeLowActuator_BASIS 0 "off" 1 "on" 2 "error" 3 "not available";
VAL_ 2633942787 splitterDirectActuator_BASIS 0 "off" 1 "on" 2 "error" 3 "not available";
VAL_ 2633942787 splitterIndirectActuator_BASIS 0 "off" 1 "on" 2 "error" 3 "not available";
VAL_ 2633942787 transmissionClutchActuator_BASIS 0 "Off" 1 "On" 2 "error" 3 "not available";
VAL_ 2633942787 PTO1status_BASIS 0 "PTO1 nicht verbaut oder PTO1 verbaut und nicht aktiviert" 1 "activated" 2 "engaged" 3 "activated and engaged" 7 "not available";
VAL_ 2633942787 PTO2status_BASIS 0 "PTO2 nicht verbaut oder PTO2 verbaut und nicht aktiviert" 1 "activated" 2 "engaged" 3 "activated and engaged" 7 "not available";
VAL_ 2633942787 PTO3status_BASIS 0 "PTO3 nicht verbaut oder PTO3 verbaut und nicht aktiviert" 1 "activated" 2 "engaged" 3 "activated and engaged";
VAL_ 2633942787 rangeHighSelector_BASIS 0 "off" 1 "on";
VAL_ 2633942787 rangeLowSelector_BASIS 0 "off" 1 "on";
VAL_ 2633942787 splitterDirectSlowSelector_BASIS 0 "off" 1 "on";
VAL_ 2633942787 splitterIndirectFastSelector_BAS 0 "off" 1 "on";
VAL_ 2566799393 rotatingBeaconLight_BASE 0 "De-activated" 1 "Activated" 2 "Fault Detected" 3 "Not Available";
VAL_ 2566799393 rightTurnSignalLights_BASE 0 "De-activated" 1 "Activated" 2 "Fault Detected" 3 "Not Available";
VAL_ 2566799393 leftTurnSignalLights_BASE 0 "De-activated" 1 "Activated" 2 "Fault Detected" 3 "Not Available";
VAL_ 2566799393 centerStopLight_BASE 0 "De-activated" 1 "Activated" 2 "Fault Detected" 3 "Not Available";
VAL_ 2566799393 rightStopLight_BASE 0 "De-activated" 1 "Activated" 2 "Fault Detected" 3 "Not Available";
VAL_ 2566799393 leftStopLight_BASE 0 "De-activated" 1 "Activated" 2 "Fault Detected" 3 "Not Available";
VAL_ 2566799393 tractorMarkerLight_BASE 0 "De-activated" 1 "Activated" 2 "Fault Detected" 3 "Not Available";
VAL_ 2566799393 rearFogLights_BASE 0 "De-activated" 1 "Activated" 2 "Fault Detected" 3 "Not Available";
VAL_ 2566799393 lowBeamHeadLightData_BASE 0 "De-activate" 1 "Activate" 2 "Fault Detected" 3 "Not Available";
VAL_ 2566799393 highBeamHeadLightData_BASE 0 "De-activate" 1 "Activate" 2 "Fault Detected" 3 "Not Available";
VAL_ 2565867838 steeringWheelAngleSensorType_BAS 0 "Relative measuring principle" 1 "Absolute measuring principle" 2 "Reserved" 3 "not available";
VAL_ 2566811434 ACCmode_BASIS 0 "off (standby, enabled, ready for activation)" 1 "speed control active" 2 "distance control active" 3 "overtake mode" 4 "hold mode" 5 "finish mode" 6 "disabled or error condition" 7 "not available/not valid";
VAL_ 2566811434 ACCsetDistanceMode_BASIS 0 "ACC Distance mode #1 (largest distance)" 1 "ACC Distance mode #2" 2 "ACC Distance mode #3" 3 "ACC Distance mode #4" 4 "ACC Distance mode #5 (shortest distance)" 5 "conventional cruise control mode" 6 "error condition" 7 "not available/ not valid";
VAL_ 2566811434 ACCtargetDetected_BASIS 0 "no targets detected" 1 "target detected" 2 "reserved" 3 "take no action";
VAL_ 2566811434 ACCsystemShutoffWarning_BASIS 0 "ACC SSOW not active" 1 "ACC SSOW active" 2 "reserved" 3 "take no action";
VAL_ 2566811434 ACCdistanceAlertSignal_BASIS 0 "ACC DAS Not Active" 1 "ACC DAS  Active" 2 "reserved" 3 "take no action";
VAL_ 2566889767 AEBSactivationState_BASE 0 "system is not active" 1 "system is active" 2 "error" 3 "not available";
VAL_ 2566889767 DPFlowLevelWarning_BASE 0 "low level not reached" 1 "low level reached" 2 "error" 3 "not available";
VAL_ 2566889767 DPFmiddleLevelWarning_BASE 0 "middle level not reached" 1 "middle level reached" 2 "error" 3 "not available";
VAL_ 2566889767 DPFactiveRegenerationManual_BASE 0 "not active" 1 "active" 2 "error" 3 "not available";
VAL_ 2566889767 engDerateDueToUreaLevel_BASE 0 "not active" 1 "active" 2 "error" 3 "not available";
VAL_ 2566889767 engDerateDueToUreaQuality_BASE 0 "not active" 1 "active" 2 "error" 3 "not available";
VAL_ 2566889767 wrnDfctLDW_BASE 0 "warning working" 1 "warning defect" 2 "error" 3 "not available";
VAL_ 2566889767 engDerateDueToUreaSystem_BASE 0 "not active" 1 "active" 2 "error" 3 "not available";
VAL_ 2566889767 engDerateDueToATSystem_BASE 0 "not active" 1 "active" 2 "error" 3 "not available";
VAL_ 2566889767 creepModeDueToUreaLevel_BASE 0 "not active" 1 "active" 2 "error" 3 "not available";
VAL_ 2566889767 creepModeDueToUreaQuality_BASE 0 "not active" 1 "active" 2 "error" 3 "not available";
VAL_ 2566889767 creepModeDueToUreaSystem_BASE 0 "not active" 1 "active" 2 "error" 3 "not available";
VAL_ 2566889767 creepModeDueToATSystem_BASE 0 "not active" 1 "active" 2 "error" 3 "not available";
VAL_ 2566889767 emgcyBrkState_BASE 0 "Emergency brake signal not active" 1 "Emergency brake signal active" 2 "error" 3 "not available";
VAL_ 2566889767 antiJackknifeBrake_BASE 0 "not active" 1 "active" 2 "error" 3 "not available";
VAL_ 2566889767 vehSpdLimWrn_BASE 0 "not active" 1 "active" 2 "error" 3 "not available";
VAL_ 2566889767 wrnDfctEBA_BASE 0 "warning working" 1 "warning defect" 2 "error" 3 "not available";
VAL_ 2566889767 PCCAenabled_BASE 0 "PCCA not enabled" 1 "PCCA enabled" 2 "error" 3 "not available";
VAL_ 2566889767 PCCAecoDisp_BASE 0 "no eco display due PCCA" 1 "eco display due PCCA" 2 "error" 3 "not available";
VAL_ 2566889767 dispMotionDataCnflct_BASE 0 "do not display vehicle motion data conflict" 1 "display vehicle motion data conflict" 2 "error" 3 "not available";
VAL_ 2566889767 LDWselected_BASE 0 "Lane Departure Warning is not activated" 1 "Lane Departure Warning is activated" 2 "error" 3 "not available";
VAL_ 2566889767 dispMotionDataLimit_BASE 0 "no limitation pending due to vehicle motion data conflict" 1 "limitation pending due to vehicle motion data conflict" 2 "error" 3 "not available";
VAL_ 2566889767 PCCAactiveDisp_BASE 0 "no display active" 1 "PCCA speed reduction display active" 2 "PCCA speed increase display active" 14 "error" 15 "not available";
VAL_ 2566889767 brakeLightTailDfct_BASE 0 "not all of the tail brake lights are defect" 1 "all of the tail brake lights are defect" 2 "error" 3 "not available";
VAL_ 2566889767 drvSysReadyToMove_BASE 0 "off" 1 "on" 2 "error" 3 "not available";
VAL_ 2566889767 exhaustHighTempLamp_BASE 0 "off" 1 "on" 2 "error" 3 "not available";
VAL_ 2566913831 modePCCA_BASE 0 "display preset 0" 1 "display preset 1" 2 "display preset 2" 3 "display preset 3" 4 "display preset 4" 5 "display preset 5" 6 "display preset 6" 7 "display preset 7" 8 "reserved 1" 9 "reserved 2" 10 "reserved 3" 11 "reserved 4" 12 "reserved 5" 13 "reserved 6" 14 "error" 15 "not available";
VAL_ 2583676659 BattPack1State_BASE 0 "Init" 1 "HV off" 2 "HV off - Locked" 3 "HV off - Error" 4 "HV on - Precharge" 5 "HV on - Drive" 6 "HV on - Charging" 7 "HV on - Electrical afterrun" 8 "HV on - Zero current request" 9 "HV on - Error" 10 "Shutdown" 11 "Reserved" 12 "Reserved" 13 "Reserved" 14 "Error" 15 "Not available";
VAL_ 2583676659 BattPack4State_BASE 0 "Init" 1 "HV off" 2 "HV off - Locked" 3 "HV off - Error" 4 "HV on - Precharge" 5 "HV on - Drive" 6 "HV on - Charging" 7 "HV on - Electrical afterrun" 8 "HV on - Zero current request" 9 "HV on - Error" 10 "Shutdown" 11 "Reserved" 12 "Reserved" 13 "Reserved" 14 "Error" 15 "Not available";
VAL_ 2583676659 BattPack5State_BASE 0 "Init" 1 "HV off" 2 "HV off - Locked" 3 "HV off - Error" 4 "HV on - Precharge" 5 "HV on - Drive" 6 "HV on - Charging" 7 "HV on - Electrical afterrun" 8 "HV on - Zero current request" 9 "HV on - Error" 10 "Shutdown" 11 "Reserved" 12 "Reserved" 13 "Reserved" 14 "Error" 15 "Not available";
VAL_ 2583676659 BattPack6State_BASE 0 "Init" 1 "HV off" 2 "HV off - Locked" 3 "HV off - Error" 4 "HV on - Precharge" 5 "HV on - Drive" 6 "HV on - Charging" 7 "HV on - Electrical afterrun" 8 "HV on - Zero current request" 9 "HV on - Error" 10 "Shutdown" 11 "Reserved" 12 "Reserved" 13 "Reserved" 14 "Error" 15 "Not available";
VAL_ 2583676659 BattPack7State_BASE 0 "Init" 1 "HV off" 2 "HV off - Locked" 3 "HV off - Error" 4 "HV on - Precharge" 5 "HV on - Drive" 6 "HV on - Charging" 7 "HV on - Electrical afterrun" 8 "HV on - Zero current request" 9 "HV on - Error" 10 "Shutdown" 11 "Reserved" 12 "Reserved" 13 "Reserved" 14 "Error" 15 "Not available";
VAL_ 2583676659 BattPackLast1State_BASE 0 "Init" 1 "HV off" 2 "HV off - Locked" 3 "HV off - Error" 4 "HV on - Precharge" 5 "HV on - Drive" 6 "HV on - Charging" 7 "HV on - Electrical afterrun" 8 "HV on - Zero current request" 9 "HV on - Error" 10 "Shutdown" 11 "Reserved" 12 "Reserved" 13 "Reserved" 14 "Error" 15 "Not available";
VAL_ 2583676659 BattPack9State_BASE 0 "Init" 1 "HV off" 2 "HV off - Locked" 3 "HV off - Error" 4 "HV on - Precharge" 5 "HV on - Drive" 6 "HV on - Charging" 7 "HV on - Electrical afterrun" 8 "HV on - Zero current request" 9 "HV on - Error" 10 "Shutdown" 11 "Reserved" 12 "Reserved" 13 "Reserved" 14 "Error" 15 "Not available";
VAL_ 2583676659 BattPack10State_BASE 0 "Init" 1 "HV off" 2 "HV off - Locked" 3 "HV off - Error" 4 "HV on - Precharge" 5 "HV on - Drive" 6 "HV on - Charging" 7 "HV on - Electrical afterrun" 8 "HV on - Zero current request" 9 "HV on - Error" 10 "Shutdown" 11 "Reserved" 12 "Reserved" 13 "Reserved" 14 "Error" 15 "Not available";
VAL_ 2583676659 BattPack2State_BASE 0 "Init" 1 "HV off" 2 "HV off - Locked" 3 "HV off - Error" 4 "HV on - Precharge" 5 "HV on - Drive" 6 "HV on - Charging" 7 "HV on - Electrical afterrun" 8 "HV on - Zero current request" 9 "HV on - Error" 10 "Shutdown" 11 "Reserved" 12 "Reserved" 13 "Reserved" 14 "Error" 15 "Not available";
VAL_ 2583676659 BattPack11State_BASE 0 "Init" 1 "HV off" 2 "HV off - Locked" 3 "HV off - Error" 4 "HV on - Precharge" 5 "HV on - Drive" 6 "HV on - Charging" 7 "HV on - Electrical afterrun" 8 "HV on - Zero current request" 9 "HV on - Error" 10 "Shutdown" 11 "Reserved" 12 "Reserved" 13 "Reserved" 14 "Error" 15 "Not available";
VAL_ 2583676659 BattPack12State_BASE 0 "Init" 1 "HV off" 2 "HV off - Locked" 3 "HV off - Error" 4 "HV on - Precharge" 5 "HV on - Drive" 6 "HV on - Charging" 7 "HV on - Electrical afterrun" 8 "HV on - Zero current request" 9 "HV on - Error" 10 "Shutdown" 11 "Reserved" 12 "Reserved" 13 "Reserved" 14 "Error" 15 "Not available";
VAL_ 2583676659 BattPack13State_BASE 0 "Init" 1 "HV off" 2 "HV off - Locked" 3 "HV off - Error" 4 "HV on - Precharge" 5 "HV on - Drive" 6 "HV on - Charging" 7 "HV on - Electrical afterrun" 8 "HV on - Zero current request" 9 "HV on - Error" 10 "Shutdown" 11 "Reserved" 12 "Reserved" 13 "Reserved" 14 "Error" 15 "Not available";
VAL_ 2583676659 BattPack14State_BASE 0 "Init" 1 "HV off" 2 "HV off - Locked" 3 "HV off - Error" 4 "HV on - Precharge" 5 "HV on - Drive" 6 "HV on - Charging" 7 "HV on - Electrical afterrun" 8 "HV on - Zero current request" 9 "HV on - Error" 10 "Shutdown" 11 "Reserved" 12 "Reserved" 13 "Reserved" 14 "Error" 15 "Not available";
VAL_ 2583676659 BattPack15State_BASE 0 "Init" 1 "HV off" 2 "HV off - Locked" 3 "HV off - Error" 4 "HV on - Precharge" 5 "HV on - Drive" 6 "HV on - Charging" 7 "HV on - Electrical afterrun" 8 "HV on - Zero current request" 9 "HV on - Error" 10 "Shutdown" 11 "Reserved" 12 "Reserved" 13 "Reserved" 14 "Error" 15 "Not available";
VAL_ 2583676659 BattPackLast2State_BASE 0 "Init" 1 "HV off" 2 "HV off - Locked" 3 "HV off - Error" 4 "HV on - Precharge" 5 "HV on - Drive" 6 "HV on - Charging" 7 "HV on - Electrical afterrun" 8 "HV on - Zero current request" 9 "HV on - Error" 10 "Shutdown" 11 "Reserved" 12 "Reserved" 13 "Reserved" 14 "Error" 15 "Not available";
VAL_ 2583676659 BattPack3State_BASE 0 "Init" 1 "HV off" 2 "HV off - Locked" 3 "HV off - Error" 4 "HV on - Precharge" 5 "HV on - Drive" 6 "HV on - Charging" 7 "HV on - Electrical afterrun" 8 "HV on - Zero current request" 9 "HV on - Error" 10 "Shutdown" 11 "Reserved" 12 "Reserved" 13 "Reserved" 14 "Error" 15 "Not available";
VAL_ 2566801959 transmissionMode1indicator_BASIS 0 "Transmission Mode 1 not active" 1 "Transmission Mode 1 Active" 2 "error" 3 "not available";
VAL_ 2583674355 BattSysIsoMeasResult_BASE 0 "No fault" 1 "Minor fault" 2 "Major fault" 3 "Reserved" 4 "Reserved" 5 "Reserved" 6 "Reserved" 7 "Reserved" 8 "Reserved" 9 "Reserved" 10 "Reserved" 11 "Reserved" 12 "Reserved" 13 "Reserved" 14 "Error" 15 "Not Available";
VAL_ 2583674355 BattSysIsoMeasState_BASE 0 "Not active" 1 "Active" 2 "Error" 3 "Not available";
VAL_ 2583639335 vehProfileTunnelCat_BASE 0 "No restriction" 1 "Category B" 2 "Category C" 3 "Category D" 4 "Category E" 14 "error" 15 "not available";
VAL_ 2562153767 hubVidInpUpdateTrigger_BASE 0 "no check" 1 "check vid inputs for updates" 2 "error" 3 "not available";
VAL_ 2562153767 cameraHubTrigger3req_BASE 0 "Not triggered" 1 "Triggered" 2 "error" 3 "not available";
VAL_ 2562153767 cameraHubTrigger2req_BASE 0 "Not triggered" 1 "Triggered" 2 "error" 3 "not available";
VAL_ 2562153767 cameraHubTrigger4req_BASE 0 "Not triggered" 1 "Triggered" 2 "error" 3 "not available";
VAL_ 2562153767 cameraHubTrigger1req_BASE 0 "Not triggered" 1 "Triggered" 2 "error" 3 "not available";
VAL_ 2566575655 inletContactorState_BASE 0 "Contactor Open" 1 "Contactor Closed" 2 "error - contactor fault detected" 3 "not available";
VAL_ 2566575655 EVSEconnectorLockState_BASE 0 "Unlocked" 1 "Locked" 2 "In transition to or from Locked" 3 "Reserved 3" 4 "Reserved 4" 5 "No locking mechanism is available on this vehicle" 6 "error" 7 "not available";
VAL_ 2554986535 EVmcCabinCondFlag_BASE 0 "Cabin conditioning not active" 1 "Cabin conditioning active" 2 "error" 3 "not available";
VAL_ 2554986535 EVmcRESScondFlag_BASE 0 "Battery conditioning not active" 1 "Battery conditioning active" 2 "error" 3 "not available";
VAL_ 2163223335 crashType_BASE 0 "no crash" 1 "frontal crash" 2 "rear crash" 3 "side crash left" 4 "side crash right" 16 "rollover" 27 "error 1" 28 "error 2" 29 "error 3" 30 "error" 31 "not available";
VAL_ 2600454422 PCCAinfrastructEnabled_BASE 0 "PCCA infrastructure not enabled" 1 "PCCA infrastructure enabled" 2 "error" 3 "not available";
VAL_ 2600454422 brkLiningSlidingContact_BASE 0 "brake linings sufficient" 1 "brake linings insufficient" 2 "error" 3 "not available";
VAL_ 2600454422 EBSalive_BASE 0 "ECU not alive" 1 "ECU alive" 2 "error" 3 "not available";
VAL_ 2600454422 PCCAdynamicRollEnabled_BASE 0 "PCCA dynamic rolling not enabled" 1 "PCCA dynamic rolling enabled" 2 "error" 3 "not available";
VAL_ 2600454422 PCCAvarSpdLimiterEnabled_BASE 0 "PCCA variable speed limiter not enabled" 1 "PCCA variable speed limiter enabled" 2 "error" 3 "not available";
VAL_ 2600454422 dispPCCAmapDataNotAvailable_BASE 0 "map data for PCCA available" 1 "map data for PCCA temporary not available" 2 "error" 3 "not available";
VAL_ 2600454422 dispPCCAreactInfrastruct_BASE 0 "no action" 1 "reaction on speed limit" 2 "reaction on curve" 3 "reaction on traffic circle" 4 "reaction on slip road" 14 "error" 15 "not available";
VAL_ 2600454422 dispRecommVarSpdLimiter_BASE 0 "no action" 1 "recommendation to roll out / speed down" 2 "recommendation to speed up" 14 "error" 15 "not available";
VAL_ 2600454422 monDiffLockWrng_BASE 0 "Warning inactive" 1 "Warning active" 2 "error" 3 "not available";
VAL_ 2600454422 dispAutoSpeedReduction_BASE 0 "not active" 1 "active" 2 "error" 3 "not available";
VAL_ 2562086183 pbCan1button_BASE 0 "inactive" 1 "active" 2 "error" 3 "not available";
VAL_ 2562086183 pbCan2button_BASE 0 "inactive" 1 "active" 2 "error" 3 "not available";
VAL_ 2562086183 pbCan3button_BASE 0 "inactive" 1 "active" 2 "error" 3 "not available";
VAL_ 2562086183 pbCan4button_BASE 0 "inactive" 1 "active" 2 "error" 3 "not available";
VAL_ 2562086183 pbCan5button_BASE 0 "inactive" 1 "active" 2 "error" 3 "not available";
VAL_ 2562086183 pbCan6button_BASE 0 "inactive" 1 "active" 2 "error" 3 "not available";
VAL_ 2562086183 pbExteriorReq1BB_BASE 0 "not pressed" 1 "pressed" 2 "error" 3 "not available / not installed";
VAL_ 2562086183 pbExteriorReq2BB_BASE 0 "not pressed" 1 "pressed" 2 "error" 3 "not available / not installed";
VAL_ 2562086183 pbExteriorReq3BB_BASE 0 "not pressed" 1 "pressed" 2 "error" 3 "not available / not installed";
VAL_ 2562086183 pbExteriorReq4BB_BASE 0 "not pressed" 1 "pressed" 2 "error" 3 "not available / not installed";
VAL_ 2600403727 workinglightNotWork1_BASE 0 "No Request" 1 "Request not functional Workinglight" 2 "error" 3 "not available";
VAL_ 2600403727 workinglightNotWork2_BASE 0 "No Request" 1 "Request not functional Workinglight" 2 "error" 3 "not available";
VAL_ 2600403727 warningbeaconNotWork1_BASE 0 "No Request" 1 "Request not functional Workinglight" 2 "error" 3 "not available";
VAL_ 2600403727 warningbeaconNotWork3_BASE 0 "No Request" 1 "Request not functional Workinglight" 2 "error" 3 "not available";
VAL_ 2600403727 runUpPropInhibitRmtTstr_BASE 0 "run up not inhibited" 1 "run up inhibited" 2 "error" 3 "not available";
VAL_ 2600403727 rmtTstrInstallStRcCalled_BASE 0 "routine control has not been called" 1 "routine control has been called" 2 "error" 3 "not available";
VAL_ 2600403727 rmtTstrInstallState_BASE 0 "IDLE" 1 "UNCRITICAL_FAIL_END" 24 "INSTALL" 25 "INSTALL_SUCCESS_TOCONFIRM" 26 "ROLLBACK_SUCCESS_TOCONFIRM" 27 "CRITICAL_FAIL_TOCONFIRM" 28 "UNCRITICAL_FAIL_TOCONFIRM" 29 "STARTUP" 31 "CRITICAL_FAIL_END";
VAL_ 2566889751 hmiDashboardIllumiFocussed_BASE 0 "Unfocussed" 1 "Focussed" 2 "error" 3 "not available";
VAL_ 2566889751 hmiHeadlightAdjtmntFocussed_BASE 0 "Unfocussed" 1 "Focussed" 2 "error" 3 "not available";
VAL_ 2566889751 PCCAenableReq_BASE 0 "No User Input for Activation PCCA" 1 "User Input for Activation PCCA" 2 "error" 3 "not available";
VAL_ 2566889751 reqSetRevAlert_BASE 0 "default mute" 1 "default loud" 2 "error" 3 "not available";
VAL_ 2566889751 ctrlSwStatusCluster_BASE 0 "neutral" 1 "Off" 4 "Set-" 16 "Resume" 64 "Set+" 128 "Set" 170 "Defect" 250 "Save Current Speed";
VAL_ 2566889751 rollMaticEnableReq_BASE 0 "no user input for rollMatic" 1 "user input for rollMatic" 2 "error" 3 "not available";
VAL_ 2566890263 daytimeRunninLightReq_BASE 0 "deactivated" 1 "activated" 2 "error" 3 "not available";
VAL_ 2566890263 backgroundLightAutoRevReq_BASE 0 "no user request" 1 "user request" 2 "error" 3 "not available";
VAL_ 2566890263 bckgrndLghtDyNghtMdAutReq_BASE 0 "no user request" 1 "user request" 2 "error" 3 "not available";
VAL_ 2566890263 uiFCWactivWrnReq_BASE 0 "Warning ON" 1 "Warning OFF" 2 "error" 3 "not available";
VAL_ 2566890263 uiFCWactivActWrnReq_BASE 0 "Acute Warning ON" 1 "Acute Warning OFF" 2 "error" 3 "not available";
VAL_ 2566890263 DPFrgnrtnReq_BASE 0 "tipSw DPFrgnrtnReq not pressed" 1 "tipSw DPFrgnrtnReq pressed" 2 "error" 3 "not available";
VAL_ 2566890263 hmiWarningAGenabledReq_BASE 0 "no attentionGuard HMI Warning requested" 1 "attentionGuard HMI Warning requested" 2 "no request" 14 "error" 15 "not available";
VAL_ 2566890263 lccpaEnableReq_BASE 0 "no user request to enable LCCPA" 1 "user request to enable LCCPA" 2 "error" 3 "not available";
VAL_ 2566890263 reqHmiSeatVbrtnLft_BASE 0 "No haptic" 1 "Haptic" 2 "error" 3 "not available";
VAL_ 2566890263 reqHmiSeatVbrtnRght_BASE 0 "No haptic" 1 "Haptic" 2 "error" 3 "not available";
VAL_ 2566890263 crpCtrlEnableReq_BASE 0 "no user requests to change activation state" 1 "user requests to change activation state" 2 "error" 3 "not available";
VAL_ 2566890263 bckgrndLghtDyNghtMdManReq_BASE 0 "no user request" 1 "user request" 2 "error" 3 "not available";
VAL_ 2566890263 interiorLightAutoCLreq_BASE 0 "deactivated" 1 "activated" 2 "error" 3 "not available";
VAL_ 2566890263 interiorLightAutoReq_BASE 0 "deactivated" 1 "activated" 2 "error" 3 "not available";
VAL_ 2566890263 lightWasherReq_BASE 0 "deactivated" 1 "activated" 2 "error" 3 "not available";
VAL_ 2566890263 comfModeSlct_BASE 0 "comfort mode for indicator lights not requested" 1 "comfort mode for indicator lights requested" 2 "error" 3 "not available";
VAL_ 2566890263 showAxleLoadCntrlReq_BASE 0 "No request to show axle load control" 1 "Request to show axle load control" 2 "error" 3 "not available";
VAL_ 2566890263 reqLateralLaneAlignmentLKA_BASE 0 "rechts" 1 "mittig" 2 "links" 14 "error" 15 "not available";
VAL_ 2566890263 confirmReverseReq_BASE 0 "confirmation not active" 1 "confirmation active" 2 "error" 3 "not available";
VAL_ 2566890263 entranceLightAutoReq_BASE 0 "No request" 1 "Request";
VAL_ 2566890263 uiCntrlLockSpeedSelect_BASE 0 "no user request" 1 "user request" 2 "error" 3 "not available";
VAL_ 2566890263 uiCntrlUnlockDoorSelect_BASE 0 "no user request" 1 "user request" 2 "error" 3 "not available";
VAL_ 2566890263 uiDispAddDrvTimePreWarnReq_BASE 0 "inactive" 1 "active" 2 "error" 3 "not available";
VAL_ 2566890263 intBrkSwReq_BASE 0 "Do not change brakematic setting" 1 "Change brakematic setting" 2 "error" 3 "not available";
VAL_ 2566890519 resetTourReason1_BASE 0 "no reset" 1 "reset" 2 "error" 3 "not available";
VAL_ 2566890519 lightTestWithLearnReq_BASE 0 "deactivated" 1 "activated" 2 "error" 3 "not available";
VAL_ 2566890519 lightTestWithoutLearnReq_BASE 0 "deactivated" 1 "activated" 2 "error" 3 "not available";
VAL_ 2566890519 resetTourReason2_BASE 0 "no reset" 1 "reset" 2 "error" 3 "not available";
VAL_ 2566890519 PCCAinfrastructEnableReq_BASE 0 "no user input for deactivation/activation PCCA infrastructure" 1 "user input for deactivation/activation PCCA infrastructure" 2 "error" 3 "not available";
VAL_ 2566890519 PCCAdynamicRollEnableReq_BASE 0 "no user input for deactivation/activation PCCA dynamic rolling" 1 "user input for deactivation/activation PCCA dynamic rolling" 2 "error" 3 "not available";
VAL_ 2566890519 PCCAvarSpdLimiterEnableReq_BASE 0 "no user input for deactivation/activation PCCA variable speed limiter" 1 "user input for deactivation/activation PCCA variable speed limiter" 2 "error" 3 "not available";
VAL_ 2566890519 revgPrhbtnSw_BASE 0 "not active" 1 "active" 2 "error" 3 "not available";
VAL_ 2566890519 TJAenableReq_BASE 0 "no user request to activate TJA" 1 "user request to activate TJA" 2 "error" 3 "not available";
VAL_ 2566890519 LGAenableReq_BASE 0 "no user request to enable LGA" 1 "user request to enable LGA" 2 "error" 3 "not available";
VAL_ 2566890519 LDWenableReq_BASE 0 "no user request to enable LDW" 1 "user request to enable LDW" 2 "error" 3 "not available";
VAL_ 2566890519 setTirePressAutoMode_BASE 0 "manually" 1 "automatically" 2 "error indicator" 3 "not available / not installed";
VAL_ 2566890519 instrWorkg_BASE 0 "display instrumentation not working / timeout / no signal" 1 "display instrumentation working" 2 "error" 3 "not available";
VAL_ 2566890519 payloadReset_BASE 0 "No Reset" 1 "Reset" 2 "error" 3 "not available / not installed";
VAL_ 2566890519 resetTourReason3_BASE 0 "no reset" 1 "reset" 2 "error" 3 "not available";
VAL_ 2566890519 axleLocSetTireSize_BASE 0 "no axle" 1 "axle 1" 2 "axle 2" 3 "axle 3" 4 "axle 4" 5 "axle 5" 6 "axle 6";
VAL_ 2566890519 transferCaseCtrlNeutReq_BASE 0 "not pressed" 1 "pressed" 2 "error" 3 "not available";
VAL_ 2566890519 statusAcousticWrnSig_BASE 0 "acoustic warning working" 1 "acoustic warning left not working" 2 "acoustic warning right not working" 3 "acoustic warning left and right not working" 254 "error" 255 "not available";
VAL_ 2600454951 LCWselected_BASE 0 "Lane Change Warning is not activated" 1 "Lane Change Warning is activated" 2 "error" 3 "not available";
VAL_ 2600454951 TCWselected_BASE 0 "Turn Collision Warning is not activated" 1 "Turn Collision Warning is activated" 2 "error" 3 "not available";
VAL_ 2600454951 TCWLCWshowSelection_BASE 0 "TCW and LCW selection menu not requested" 1 "TCW and LCW selection menu requested" 2 "error" 3 "not available";
VAL_ 2600454951 modeOptWrngSideLft_BASE 0 "no warning" 1 "driver notice" 2 "warning step 1" 3 "warning step 2";
VAL_ 2600454951 modeOptWrngSideRght_BASE 0 "no warning" 1 "driver notice" 2 "warning step 1" 3 "warning step 2";
VAL_ 2600454951 wrngSideSource_BASE 0 "no warning" 1 "Turn Collision Warning" 2 "Lane Change Warning";
VAL_ 2600454951 TCWLCWshowDeactWrng_BASE 0 "no user request" 1 "user request to deactivate both systems" 2 "error" 3 "not available";
VAL_ 2600454951 lightWasherPump_BASE 0 "deactivated" 1 "activated" 2 "error" 3 "not available";
VAL_ 2600454424 dispHGBactiveState_BASE 0 "no HGB symbol" 1 "green HGB icon" 2 "reserved" 3 "yellow HGB icon" 4 "reserved" 5 "red HGB icon" 6 "blinking red HGB icon";
VAL_ 2600454424 tsiStateLEDreq_BASE 0 "LED off" 1 "LED on" 2 "error" 3 "not available";
VAL_ 2600454424 TSInotificationSound_BASE 0 "Notification sound off" 1 "Notification sound once" 2 "error" 3 "not available";
VAL_ 2600454424 TSIwrnSound_BASE 0 "Do not play TSI warning sound" 1 "Play Tsi warning sound" 2 "error" 3 "not available";
VAL_ 2600454424 reqDispSafeStopEnd_BASE 0 "no request" 1 "request" 2 "error" 3 "not available";
VAL_ 2600454424 reqDispSafeStopActive_BASE 0 "no request" 1 "request" 2 "error" 3 "not available";
VAL_ 2600454424 dispCrpCtrlAbortPreWarn_BASE 0 "notAborted" 1 "Abortion" 2 "error" 3 "not available";
VAL_ 2600454424 dispCrpCtrlState_BASE 0 "not expected and not active" 1 "active" 2 "expected but not active" 14 "error" 15 "not available";
VAL_ 2600454424 dispCrpCtrlActivationState_BASE 0 "notActivated" 1 "activated" 2 "error" 3 "not available";
VAL_ 2600454424 tsiChangeInfoSetting_BASE 0 "off" 1 "on" 2 "Error" 3 "Not available";
VAL_ 2600454424 tsiToleranceSetting_BASE 0 "0kph / 0mph" 1 "1kph / 1mph" 2 "2kph / 2mph" 3 "3kph / 3mph" 4 "4kph / 4mph" 5 "5kph / 5mph" 6 "6kph / 6mph" 7 "7kph / 7mph" 8 "8kph / 8mph" 9 "9kph / 9mph" 10 "10kph / 10mph" 11 "11kph / 11mph" 12 "12kph / 12mph" 13 "13kph / 13mph" 14 "14kph / 14mph" 15 "15kph / 15mph" 16 "16kph / 16mph" 17 "17kph / 17mph" 18 "18kph / 18mph" 19 "19kph / 19mph" 20 "20kph / 20mph" 62 "Error" 63 "Not available";
VAL_ 2600454424 tsiEnableSpdWrn_BASE 0 "off" 1 "on" 2 "Error" 3 "Not available";
VAL_ 2600454424 dispHGBactiveStateAcoustic_BASE 0 "no acoustic warning" 1 "acoustic warning once" 2 "acoustic warning continuous";
VAL_ 2600454424 tsiSelectedMode_BASE 0 "mode 0 - OFF" 1 "mode 1 - static signs" 2 "mode 2 - flashing signs" 3 "mode 3 - flashing signs and tone" 14 "Error" 15 "Not available";
VAL_ 2600454424 dispFCWwarning_BASE 0 "no warning" 1 "driver notice" 2 "warning step 1" 3 "warning step 2" 14 "error" 15 "not available";
VAL_ 2600454424 gearNotEfficient_BASE 0 "OD gear not relevant" 1 "OD gear not efficient" 2 "error" 3 "not available";
VAL_ 2600454424 highThermalLoadOnEngShtdwn_BASE 0 "not detected - moderate thermal load" 1 "detected - high thermal load" 2 "error" 3 "not available";
VAL_ 2600454424 fcwUiMenuEnable_BASE 0 "off" 1 "on" 2 "error" 3 "not available";
VAL_ 2600454424 ISCroadSweeperActv_BASE 0 "normal operation" 1 "roadSweeper limit active" 2 "error" 3 "not available";
VAL_ 2600454427 EBAselected_BASE 0 "the driver does not want the Advanced Emergency Braking System to warn or intervene at any time (deactivation of system)" 1 "the driver wants the Advanced Emergency Braking Sysstem to warn or intervene if necessary (no deactivation of system)" 2 "error" 3 "not available";
VAL_ 2600454427 EBAsystemEngEnd_BASE 0 "no display" 1 "display EBA finished" 2 "error" 3 "not available";
VAL_ 2600454427 dispADASmenuReq_BASE 0 "ADAS menu not requested" 1 "ADAS menu requested" 2 "error" 3 "not available";
VAL_ 2600454427 muteADASwrnReq_BASE 0 "mute of ADAS warnings not requested" 1 "mute of ADAS warnings requested" 2 "error" 3 "not available";
VAL_ 2600454427 EBAselectedVRU_BASE 0 "The driver does not want the VRU component of the Advanced Emergency Braking System to warn or intervene at any time (deactivation of system)" 1 "The driver wants the VRU component of the Advanced Emergency Braking System to warn or intervene if necessary (no deactivation of system)" 2 "error" 3 "not available";
VAL_ 2600454427 bremsomatAvailable_BASE 0 "brakematic is not available" 1 "brakematic is available" 2 "error" 3 "not available";
VAL_ 2600454427 TAsysActivated_BASE 0 "TA disabled" 1 "TA enabled" 2 "error" 3 "not available";
VAL_ 2600454427 DVFRlateRevCAMmessage_BASE 0 "Reverse CAM not late" 1 "Reverse CAM too late" 2 "error" 3 "not available";
VAL_ 2600454427 ACC_FailureJ10_BASE 0 "Failure not active" 1 "Failure active" 2 "error" 3 "not available";
VAL_ 2600454427 dispFrontVehicleAvailable_BASE 0 "front vehicle display is not available" 1 "front vehicle display is available" 2 "error" 3 "not available";
VAL_ 2600454427 attentionGuardAvailable_BASE 0 "attentionGuard is not available" 1 "attentionGuard is available" 2 "error" 3 "not available";
VAL_ 2600454427 hmiWarningAGenabled_BASE 0 "HMI output disabled" 1 "visual, acoustic and haptic HMI output enabled";
VAL_ 2600454427 dispDPFactvRgnrtnClngDwn_BASE 0 "No display of DPF active regeneration cooling down" 1 "Display DPF active regeneration cooling down" 2 "error" 3 "not available";
VAL_ 2600454427 EBAsystemAvailableVEH_BASE 0 "EBA system not available" 1 "EBA system available" 2 "error" 3 "not available";
VAL_ 2600454427 CCselectedMode_BASE 0 "none" 1 "FGR or ACC" 2 "FGB" 6 "error" 7 "not available";
VAL_ 2600454427 TSIuiMenuEnable_BASE 0 "menu disabled" 1 "menu enabled" 2 "error" 3 "not available";
VAL_ 2600454427 higherLvlCtrlRsp_BASE 0 "no action" 1 "automatic ON, level inactive" 2 "automatic ON, level active" 6 "error" 7 "not available";
VAL_ 2600454427 reqDispLDWworking_BASE 0 "not working" 1 "working" 2 "error" 3 "not available";
VAL_ 2600454427 reqDispLCCPAworking_BASE 0 "not working" 1 "working" 2 "error" 3 "not available";
VAL_ 2600454427 reqDispTJAworking_BASE 0 "not working" 1 "working" 2 "error" 3 "not available";
VAL_ 2600454427 reqDispLGAworking_BASE 0 "not working" 1 "working" 2 "error" 3 "not available";
VAL_ 2600454427 ldwSysState_VAR1 0 "LDW not ready (not installed)" 1 "LDW not ready (initializing)" 2 "LDW not ready (defilade light mode)" 3 "LDW not ready (mission mode)" 9 "LDW not ready (not defined)" 10 "LDW not selected and error detected" 11 "LDW not selected and temporary not available (camera blocked)" 12 "LDW not selected and temporary not available (camera overheated)" 13 "LDW not selected and temporary not available (radar blocked)" 14 "LDW not selected and input signals not available" 15 "LDW not selected (checkbox-cond) and no malfunction detected" 16 "LDW not selected (LKA-cond) and no malfunction detected" 30 "LDW selected and error detected" 31 "LDW selected and temporary not available (camera blocked)" 32 "LDW selected and temporary not available (camera overheated)" 33 "LDW selected and temporary not available (radar blocked)" 34 "LDW selected and input signals not available" 53 "LDW selected, no errors, deactivated due to driving-level" 55 "LDW selected, no errors, deactivated due to current curvature" 56 "LDW selected, no errors, deactivated due to vehicle-speed" 57 "LDW selected, no errors, deactivated due to indicator-left" 58 "LDW selected, no errors, deactivated due to indicator-right" 60 "LDW selected, no errors, deactivated due to road-reference" 61 "LDW selected, no errors, deactivated due to road-marking-left" 62 "LDW selected, no errors, deactivated due to road-marking-right" 63 "LDW selected, no errors, deactivated due to lane-width" 64 "LDW selected, no errors, deactivated due to oncoming-traffic" 67 "LDW selected, no errors, deactivated due to driving-off-center" 70 "LDW selected, no errors, deactivated due to previous LDW warning" 73 "LDW selected, no errors, deactivated due to LGA-condition" 100 "LDW selected, no errors, activated" 101 "LDW selected, no errors, left active" 105 "LDW selected, no errors, right active" 254 "error" 255 "not available";
VAL_ 2600454427 EBAsystemAvailableVRU_BASE 0 "EBA system not available" 1 "EBA system available" 2 "error" 3 "not available";
VAL_ 2600454427 EBAdispNoSelectPossibleVRU_BASE 0 "no display requested" 1 "display requested (no selection of the VRU component of EBA possible)" 2 "error" 3 "not available";
VAL_ 2600454428 dispVASCmenuReq_BASE 0 "no action" 1 "FA truck lowering" 2 "FA truck raising" 3 "RA truck lowering" 4 "RA truck raising" 5 "FA trailer lowering" 6 "FA trailer raising" 7 "RA trailer lowering" 8 "RA trailer raising" 9 "D1 truck lowering" 10 "D1 truck raising" 11 "NN1 request" 12 "NN2 request" 13 "NN3 request" 14 "lower level request" 15 "upper level request" 16 "memory 1 request" 17 "memory 2 request" 18 "memory 3 request" 19 "memory 4 request" 20 "memory 1 store request" 21 "memory 2 store request" 22 "memory 3 store request" 23 "memory 4 store request" 24 "truck lowering" 25 "truck raising" 26 "trailer lowering" 27 "trailer raising" 28 "truck + trailer lowering" 29 "truck + trailer raising" 30 "last active menu screen" 62 "error" 63 "not available";
VAL_ 2600454428 levelLearnTrlStatusSpdLvl_BASE 0 "not activated" 1 "activated" 2 "error" 3 "not available";
VAL_ 2600454428 spdDpndntLvlCtrlStatus_BASE 0 "inactive" 1 "active" 2 "error" 3 "not available";
VAL_ 2600454428 liftAxleAutoStatus_BASE 0 "no action" 1 "lifting due to low axle load" 2 "lowering due to high axle load" 6 "error" 7 "not available";
VAL_ 2600454428 relieveAxleNotPossible_BASE 0 "no refusal" 1 "would exceed axle load limit" 2 "above speed limit" 3 "general reject" 6 "error" 7 "not available";
VAL_ 2600454428 nomLvlNotSet_BASE 0 "no action" 1 "nominal level not set" 2 "error" 3 "not available";
VAL_ 2600454428 lvlCtrlNotPossible_BASE 0 "no action" 1 "above speed limit" 2 "general reject" 3 "requested level not available" 4 "driving level reject" 6 "error" 7 "not available";
VAL_ 2600454428 liftAxleNotPossible_BASE 0 "no refusal" 1 "would exceed axle load limit" 2 "above speed limit" 3 "general reject" 6 "error" 7 "not available";
VAL_ 2600454428 spdDpndntLvlCtrlRsp_BASE 0 "not activated" 1 "activated" 2 "error" 3 "not available";
VAL_ 2600454428 trctnHlpTrlRefusal_BASE 0 "no reason for deactivation of traction help" 1 "front axle has fallen below minimum load" 2 "driving axle has exceeded permissible load" 3 "deactivation of traction help at the truck" 4 "deactivation through ASR" 5 "deactivation by speed limit" 6 "deactivation with unspecifc reason" 14 "error" 15 "not available";
VAL_ 2600454428 kneelingOff_BASE 0 "no kneeling off" 1 "kneeling off activated" 2 "error" 3 "not available";
VAL_ 2600454428 VASCerrorActive_BASE 0 "inactive" 1 "active" 2 "error" 3 "not available";
VAL_ 2600454428 kneelingNotPossible_BASE 0 "no kneeling refusal" 1 "kneeling refusal active" 2 "error" 3 "not available";
VAL_ 2600454428 kneelgPrslctAutoState_BASE 0 "inactive" 1 "active" 2 "error" 3 "not available";
VAL_ 2600454428 belowFAminSteeringLoad_BASE 0 "inactive" 1 "active" 2 "error" 3 "not available";
VAL_ 2600454428 lccpaSelected_BASE 0 "LCCPA is not selected" 1 "LCCPA is selected" 2 "error" 3 "not available";
VAL_ 2600454428 trctnHlpNotPossible_BASE 0 "no refusal" 1 "above speed limit" 2 "below supply pressure threshold" 3 "general reject" 6 "error" 7 "not available";
VAL_ 2600454428 lateralLaneAlignmentLKA_BASE 0 "OFF" 1 "outside active" 2 "center active" 3 "inside active" 6 "error" 7 "not available";
VAL_ 2600454428 FCWacuteWarningSelected_BASE 0 "FCW acute warning deselected" 1 "FCW acute warning selected" 2 "error" 3 "not available";
VAL_ 2600454428 FCWwarningSelected_BASE 0 "FCW warning deselected" 1 "FCW warning selected" 2 "error" 3 "not available";
VAL_ 2600454428 distanceGuardCollWrn_BASE 0 "No warning" 1 "Warning level 1" 2 "Warning level 2" 6 "Error" 7 "Not available";
VAL_ 2600454428 levelLearnTrlStatusNL2_BASE 0 "not activated" 1 "activated" 2 "error" 3 "not available";
VAL_ 2600454428 distanceWarning_BASE 0 "Distance warning off" 1 "Distance warning level 1" 2 "Distance warning level 2" 6 "Error" 7 "Not available";
VAL_ 2600454428 levelLearnTrlStatus_BASE 0 "no action" 1 "requested" 2 "conditions not correct" 3 "in progress" 4 "failed" 5 "successfully completed" 14 "error" 15 "not available";
VAL_ 2566891303 ASRactvRsp_BASE 0 "ASR brake control and ASR engine control passive" 1 "ASR brake control active or ASR engine control active" 2 "error" 3 "not available";
VAL_ 2566891303 curBrkmaticMode_BASE 0 "Nothing (active) -" 1 "Deactivated BrakeMatic - A/" 2 "Automatic active and working - A" 3 "Servicebrake active and working - symbol brake" 4 "Manual Level 1 active and working" 5 "Manual Level 2 active and working" 6 "Manual Level 3 active and working" 7 "Manual Level 4 active and working" 8 "Manual Level 5 active and working" 9 "Manual Level 6 active and working" 10 "Manual Level Max active and working (reserved)" 11 "Manual Level active and working - only one level";
VAL_ 2600403717 transShiftingServoLS_BASE 0 "not activated" 1 "activated" 2 "error" 3 "not available";
VAL_ 2600403717 PTO1HS_BASE 0 "off" 1 "on" 2 "error" 3 "not available";
VAL_ 2600403717 PTO2HS_BASE 0 "off" 1 "on" 2 "error" 3 "not available";
VAL_ 2600403717 PTO3HS_BASE 0 "off" 1 "on" 2 "error" 3 "not available";
VAL_ 2600403717 PTO3userReqResp_BASE 0 "response not active" 1 "response active" 2 "error" 3 "not available";
VAL_ 2600403717 signalHorn_BASE 0 "deactivated" 1 "activated" 2 "error" 3 "not available";
VAL_ 2600403717 signalHornValveOn_BASE 0 "deactivated" 1 "activated" 2 "error" 3 "not available";
VAL_ 2600403717 CAVIcomReq_BASE 0 "no ComReq" 1 "Comreq" 2 "error" 3 "not available";
VAL_ 2600403717 elecSteerBackupNotAvail_BASE 0 "electrical steering Backup available" 1 "no electrical steering Backup available" 2 "error" 3 "not available";
VAL_ 2600403717 LDWselectedCB_BASE 0 "warning not selected" 1 "warning selected" 2 "error" 3 "not available";
VAL_ 2600403717 LGAselected_BASE 0 "Lane Guard Assist is not activated" 1 "Lane Guard Assist is activated" 2 "error" 3 "not available";
VAL_ 2600403717 LKAselected_BASE 0 "LKA is not selected" 1 "LKA is selected" 2 "error" 3 "not available";
VAL_ 2600403717 reqDispCtrlSteeringWheel_BASE 0 "not active" 1 "active" 2 "error" 3 "not available";
VAL_ 2600403717 reqDispHandsOff1_BASE 0 "not active" 1 "active" 2 "error" 3 "not available";
VAL_ 2600403717 reqDispHandsOff2_BASE 0 "not active" 1 "active" 2 "error" 3 "not available";
VAL_ 2600403717 reqDispHandsOff3_BASE 0 "not active" 1 "active" 2 "error" 3 "not available";
VAL_ 2600403717 reqDispLGAactive_BASE 0 "not active" 1 "active" 2 "error" 3 "not available";
VAL_ 2600403717 reqDispLGAdeactTemp_BASE 0 "not active" 1 "active" 2 "error" 3 "not available";
VAL_ 2600403717 reqDispLGAmodeActive_BASE 0 "not in active mode" 1 "active mode" 2 "error" 3 "not available";
VAL_ 2600403717 slowVoltDecrDtctd_BASE 0 "no slow voltage decrease detected" 1 "slow voltage decrease detected" 2 "error" 3 "not available";
VAL_ 2566890279 LDWdispNoActvnReqPossible_BASE 0 "no display" 1 "display LDW not operable" 2 "error" 3 "not available";
VAL_ 2566890279 lvlOutOfRgRsp_BASE 0 "level not out of range" 1 "level out of range" 2 "error" 3 "not available";
VAL_ 2566890279 drvSwitchNeutralReq_BASE 0 "no switch to neutral request" 1 "switch to neutral request" 2 "error" 3 "not available";
VAL_ 2566890279 airFilterClogged_BASE 0 "air filter not clogged" 1 "air filter clogged" 2 "error" 3 "not available";
VAL_ 2566890279 fuelLvlWarning_BASE 0 "warning fuel level not active" 1 "warning fuel level active" 2 "error" 3 "not available";
VAL_ 2566890279 condFuelPrefilterHtngFail_BASE 0 "no failure" 1 "failure" 2 "error" 3 "not available";
VAL_ 2566890279 washerFluidLvlLow_BASE 0 "washer level above threshold" 1 "washer level below threshold" 2 "error" 3 "not available";
VAL_ 2566890279 displayAntiTheftWarning2_BASE 0 "no display" 1 "display" 2 "error" 3 "not available";
VAL_ 2566890279 displayAntiTheftWarning_BASE 0 "no display" 1 "display" 2 "error" 3 "not available";
VAL_ 2566890279 dispWarningCoolantLvl_BASE 0 "no warning" 1 "warning" 2 "error" 3 "not available";
VAL_ 2566890279 deactInfrFGRwarn_BASE 0 "no deactivation warning" 1 "deactivation warning" 2 "error" 3 "not available";
VAL_ 2566890279 engineStarterMode_MAN 0 "no start (no request)" 1 "start active" 2 "start finished" 3 "no start (due to engine reasons)" 4 "no start (due to vehicle reasons)" 5 "no start (because of active immobilizer)" 6 "no start (due to starter reasons)" 14 "error" 15 "not available";
VAL_ 2566890279 DPFRgnDrvSysActvReq_BASE 0 "request not active" 1 "request active" 2 "error" 3 "not available";
VAL_ 2566890279 DPFRgnClutchReleaseReq_BASE 0 "request not active" 1 "request active" 2 "error" 3 "not available";
VAL_ 2566890279 DPFRgnReleasePTOreq_BASE 0 "request not active" 1 "request active" 2 "error" 3 "not available";
VAL_ 2566890279 DPFrgnrtnProhReleaseReq_BASE 0 "request not active" 1 "request active" 2 "error" 3 "not available";
VAL_ 2566890279 DPFRgnVehStandStillReq_BASE 0 "request not active" 1 "request active" 2 "error" 3 "not available";
VAL_ 2566890279 DPFRgnWarmUpEngReq_BASE 0 "request not active" 1 "request active" 2 "error" 3 "not available";
VAL_ 2566890279 DPFRgnNeutrGearReq_BASE 0 "request not active" 1 "request active" 2 "error" 3 "not available";
VAL_ 2566890279 DPFRgnParkBrkActvReq_BASE 0 "request not active" 1 "request active" 2 "error" 3 "not available";
VAL_ 2566890279 DPFrgnReleaseAPreq_BASE 0 "request not active" 1 "request active" 2 "error" 3 "not available";
VAL_ 2566890279 DPFrgnReleaseBPReq_BASE 0 "request not active" 1 "request active" 2 "error" 3 "not available";
VAL_ 2566890279 EBAdispNoSelectionPossible_BASE 0 "no display requested" 1 "display requested (no selection of EBA possible)" 2 "error indicator" 3 "not available / not installed";
VAL_ 2364637578 MG1InvCtrlLmtsOvrrdeMd_BASE 0 "Operating limits are not overridden" 1 "Torque Limits Mode" 2 "Speed Limits Mode" 3 "DC Side Voltage Limits Mode" 4 "DC Side Current Limits Mode" 5 "DC Side Power Limits Mode" 6 "Mechanical Power Limits Mode" 7 "SAE Reserved 7" 8 "SAE Reserved 8" 9 "SAE Reserved 9" 10 "SAE Reserved 10" 11 "SAE Reserved 11" 12 "SAE Reserved 12" 13 "SAE Reserved 13" 14 "error" 15 "not available";
VAL_ 2364637578 MGIMF1setpointMode_BASE 0 "Powered On" 1 "Waiting for Operational conditions" 2 "Standby" 3 "SAE Reserved 3" 4 "SAE Reserved 4" 5 "Manufacturer specific passive mode 1" 6 "Manufacturer specific passive mode 2" 7 "Torque Control Mode" 8 "Speed Control Mode" 9 "DC Side Voltage Mode" 10 "DC Side Current Mode" 11 "Mechanical Power Control Mode" 12 "DC Power Control Mode" 13 "SAE Reserved 13" 14 "SAE Reserved 14" 15 "SAE Reserved 15" 16 "SAE Reserved 16" 17 "SAE Reserved 17" 18 "Manufacturer specific active mode 1" 19 "Manufacturer specific active mode 2" 20 "Inverter active discharge mode e.g. used to discharge capacitance within the inverter." 21 "Inverter power down command mode  - afterwards inverter will not respond to further commands." 22 "SAE Reserved 22" 23 "SAE Reserved 23" 24 "SAE Reserved 24" 25 "SAE Reserved 25" 26 "SAE Reserved 26" 27 "SAE Reserved 27" 28 "Manufacturer specific special mode 1" 29 "Manufacturer specific special mode 2" 30 "error" 31 "Not Available - Dont Care -Take No";
VAL_ 2564822823 seatBeltSwitch_BASE 0 "NOT Buckled" 1 "OK - Seat Belt is buckled" 2 "Error - Switch state cannot be determined" 3 "Not Available";
VAL_ 2564822823 DPFregenerationInhibitSw_BASE 0 "not active" 1 "active" 2 "error" 3 "not available";
VAL_ 2564822823 DPFregenerationForceSw_BASE 0 "not active" 1 "active" 2 "error" 3 "not available";
